VERSION ""

NS_ :

BS_:

BU_: CVC_I MHU TBOX FCAM_I MRR SRR_RL SRR_RR SRR_FL SRR_FR DUMMY_ECU ADCU_I AMP HUD

BO_ 1178 RMCU_WarnMsg: 8 CVC_I
 SG_ CRC_RMCU_WarnMsg : 7|8@0+ (1,0) [0|255] ""  MHU
 SG_ ALIVE_RMCU_WarnMsg : 11|4@0+ (1,0) [0|15] ""  MHU
 SG_ RMCU_Warning_Flag_1 : 12|1@0+ (1,0) [0|1] ""  MHU
 SG_ RMCU_Warning_Flag_2 : 13|1@0+ (1,0) [0|1] ""  MHU
 SG_ RMCU_Warning_Flag_3 : 14|1@0+ (1,0) [0|1] ""  MHU
 SG_ RMCU_Warning_Flag_4 : 15|1@0+ (1,0) [0|1] ""  MHU
 SG_ RMCU_Warning_Flag_5 : 16|1@0+ (1,0) [0|1] ""  MHU
 SG_ RMCU_Warning_Flag_6 : 17|1@0+ (1,0) [0|1] ""  MHU
 SG_ RMCU_Warning_Flag_7 : 18|1@0+ (1,0) [0|1] ""  MHU
 SG_ RMCU_Warning_Flag_8 : 19|1@0+ (1,0) [0|1] ""  MHU
 SG_ RMCU_Warning_Flag_9 : 20|1@0+ (1,0) [0|1] ""  MHU
 SG_ RMCU_Warning_Flag_10 : 21|1@0+ (1,0) [0|1] ""  MHU
 SG_ RMCU_Warning_Flag_11 : 22|1@0+ (1,0) [0|1] ""  MHU
 SG_ RMCU_Warning_Flag_12 : 23|1@0+ (1,0) [0|1] ""  MHU
 SG_ RMCU_Reserved_signal1 : 31|8@0+ (1,0) [0|255] ""  MHU
 SG_ RMCU_Reserved_signal2 : 39|8@0+ (1,0) [0|255] ""  MHU
 SG_ RMCU_Reserved_signal3 : 47|8@0+ (1,0) [0|255] ""  MHU
 SG_ RMCU_Reserved_signal4 : 55|8@0+ (1,0) [0|255] ""  MHU
 SG_ RMCU_Reserved_signal5 : 63|8@0+ (1,0) [0|255] ""  MHU

BO_ 1179 FMCU_WarnMsg: 8 CVC_I
 SG_ CRC_FMCU_WarnMsg : 7|8@0+ (1,0) [0|255] ""  MHU
 SG_ ALIVE_FMCU_WarnMsg : 11|4@0+ (1,0) [0|15] ""  MHU
 SG_ FMCU_Warning_Flag_1 : 12|1@0+ (1,0) [0|1] ""  MHU
 SG_ FMCU_Warning_Flag_2 : 13|1@0+ (1,0) [0|1] ""  MHU
 SG_ FMCU_Warning_Flag_3 : 14|1@0+ (1,0) [0|1] ""  MHU
 SG_ FMCU_Warning_Flag_4 : 15|1@0+ (1,0) [0|1] ""  MHU
 SG_ FMCU_Warning_Flag_5 : 16|1@0+ (1,0) [0|1] ""  MHU
 SG_ FMCU_Warning_Flag_6 : 17|1@0+ (1,0) [0|1] ""  MHU
 SG_ FMCU_Warning_Flag_7 : 18|1@0+ (1,0) [0|1] ""  MHU
 SG_ FMCU_Warning_Flag_8 : 19|1@0+ (1,0) [0|1] ""  MHU
 SG_ FMCU_Warning_Flag_9 : 20|1@0+ (1,0) [0|1] ""  MHU
 SG_ FMCU_Warning_Flag_10 : 21|1@0+ (1,0) [0|1] ""  MHU
 SG_ FMCU_Warning_Flag_11 : 22|1@0+ (1,0) [0|1] ""  MHU
 SG_ FMCU_Warning_Flag_12 : 23|1@0+ (1,0) [0|1] ""  MHU
 SG_ FMCU_Reserved_signal1 : 31|8@0+ (1,0) [0|255] ""  MHU
 SG_ FMCU_Reserved_signal2 : 39|8@0+ (1,0) [0|255] ""  MHU
 SG_ FMCU_Reserved_signal3 : 47|8@0+ (1,0) [0|255] ""  MHU
 SG_ FMCU_Reserved_signal4 : 55|8@0+ (1,0) [0|255] ""  MHU
 SG_ FMCU_Reserved_signal5 : 63|8@0+ (1,0) [0|255] ""  MHU

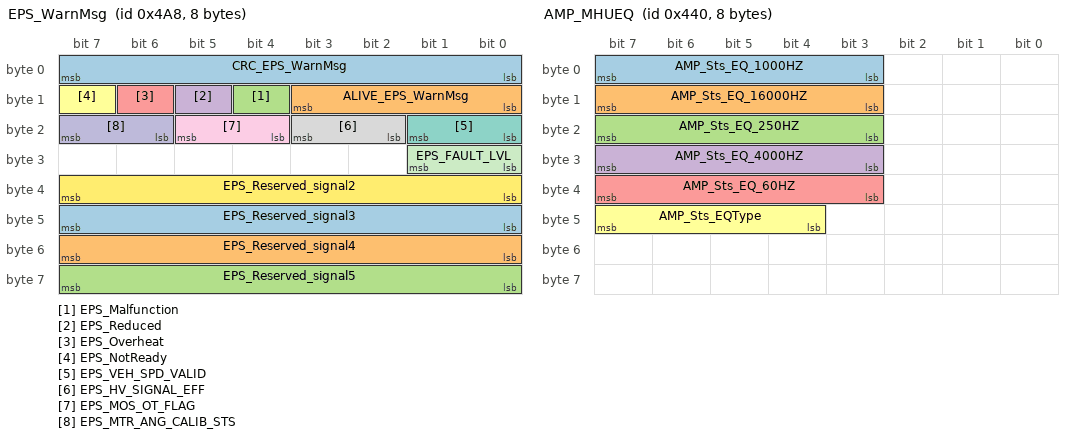
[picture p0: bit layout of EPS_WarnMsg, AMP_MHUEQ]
BO_ 1192 EPS_WarnMsg: 8 CVC_I
 SG_ CRC_EPS_WarnMsg : 7|8@0+ (1,0) [0|255] ""  MHU
 SG_ ALIVE_EPS_WarnMsg : 11|4@0+ (1,0) [0|15] ""  MHU
 SG_ EPS_Malfunction : 12|1@0+ (1,0) [0|1] ""  MHU
 SG_ EPS_Reduced : 13|1@0+ (1,0) [0|1] ""  MHU
 SG_ EPS_Overheat : 14|1@0+ (1,0) [0|1] ""  MHU
 SG_ EPS_NotReady : 15|1@0+ (1,0) [0|1] ""  MHU
 SG_ EPS_VEH_SPD_VALID : 17|2@0+ (1,0) [0|3] ""  MHU
 SG_ EPS_HV_SIGNAL_EFF : 19|2@0+ (1,0) [0|3] ""  MHU
 SG_ EPS_MOS_OT_FLAG : 21|2@0+ (1,0) [0|3] ""  MHU
 SG_ EPS_MTR_ANG_CALIB_STS : 23|2@0+ (1,0) [0|3] ""  MHU
 SG_ EPS_FAULT_LVL : 25|2@0+ (1,0) [0|3] ""  MHU
 SG_ EPS_Reserved_signal2 : 39|8@0+ (1,0) [0|255] ""  MHU
 SG_ EPS_Reserved_signal3 : 47|8@0+ (1,0) [0|255] ""  MHU
 SG_ EPS_Reserved_signal4 : 55|8@0+ (1,0) [0|255] ""  MHU
 SG_ EPS_Reserved_signal5 : 63|8@0+ (1,0) [0|255] ""  MHU

BO_ 1196 CVC_WarnMsg: 12 CVC_I
 SG_ CRC_CVC_WarnMsg : 7|8@0+ (1,0) [0|255] ""  MHU
 SG_ ALIVE_CVC_WarnMsg : 11|4@0+ (1,0) [0|15] ""  MHU
 SG_ CVC_GearPOnlyAtStationaryAlert : 12|1@0+ (1,0) [0|1] ""  MHU
 SG_ CVC_GearP_NotPossibleAlert : 13|1@0+ (1,0) [0|1] ""  MHU
 SG_ CVC_PressBrakeToEngageGear : 14|1@0+ (1,0) [0|1] ""  MHU
 SG_ CVC_CantChangeGear : 15|1@0+ (1,0) [0|1] ""  MHU
 SG_ CVC_GearMalfunction : 16|1@0+ (1,0) [0|1] ""  MHU
 SG_ CVC_RangeAlert : 17|1@0+ (1,0) [0|1] ""  MHU
 SG_ CVC_HVSystemReduced : 18|1@0+ (1,0) [0|1] ""  MHU
 SG_ CVC_FrontEDSReduced : 19|1@0+ (1,0) [0|1] ""  MHU
 SG_ CVC_FrontEDS_Malfunc : 20|1@0+ (1,0) [0|1] ""  MHU
 SG_ CVC_RearEDSReduced : 21|1@0+ (1,0) [0|1] ""  MHU
 SG_ CVC_RearEDS_Malfunc : 22|1@0+ (1,0) [0|1] ""  MHU
 SG_ CVC_CoolingSystem_Malfunc : 23|1@0+ (1,0) [0|1] ""  MHU
 SG_ CVC_NeutralRequest : 24|1@0+ (1,0) [0|1] ""  MHU
 SG_ CVC_SoftShutdown : 25|1@0+ (1,0) [0|1] ""  MHU
 SG_ CVC_EmergencyShutdown : 26|1@0+ (1,0) [0|1] ""  MHU
 SG_ CVC_ChgPortDoorSys_Malfunc : 27|1@0+ (1,0) [0|1] ""  MHU
 SG_ CVC_Gearchange_NotPossible : 28|1@0+ (1,0) [0|1] ""  MHU
 SG_ CVC_12v_Warning : 29|1@0+ (1,0) [0|1] ""  MHU,ADCU_I
 SG_ CVC_WflagRes19 : 30|1@0+ (1,0) [0|1] ""  MHU
 SG_ CVC_WflagRes20 : 31|1@0+ (1,0) [0|1] ""  MHU
 SG_ CVC_WflagRes21 : 32|1@0+ (1,0) [0|1] ""  MHU
 SG_ CVC_WflagRes22 : 33|1@0+ (1,0) [0|1] ""  MHU
 SG_ CVC_WflagRes23 : 34|1@0+ (1,0) [0|1] ""  MHU
 SG_ CVC_WflagRes24 : 35|1@0+ (1,0) [0|1] ""  MHU
 SG_ CVC_WflagRes25 : 36|1@0+ (1,0) [0|1] ""  MHU
 SG_ CVC_WflagRes26 : 37|1@0+ (1,0) [0|1] ""  MHU
 SG_ CVC_WflagRes27 : 38|1@0+ (1,0) [0|1] ""  MHU
 SG_ CVC_SuperFastCharge_longer : 39|1@0+ (1,0) [0|1] ""  MHU
 SG_ CVC_InvalidLimitSpeed : 46|1@0+ (1,0) [0|1] ""  MHU
 SG_ CVC_InvalidCruiseSpeed : 47|1@0+ (1,0) [0|1] ""  MHU
 SG_ CVC_Reserved_signal2 : 55|8@0+ (1,0) [0|255] ""  MHU
 SG_ CVC_Reserved_signal3 : 63|8@0+ (1,0) [0|255] ""  MHU
 SG_ CabinCoolDemand : 71|7@0+ (0.1,0) [0|10] "kW"  MHU
 SG_ CabinHeatDemand : 79|7@0+ (0.1,0) [0|10] "kW"  MHU
 SG_ CVC_TMSMode : 87|8@0+ (1,0) [0|255] ""  MHU

BO_ 1248 CVC_WarnMsgID_1: 64 CVC_I
 SG_ CRC_CVC_WarnMsgID_1 : 7|8@0+ (1,0) [0|255] ""  MHU
 SG_ ALIVE_CVC_WarnMsgID_1 : 11|4@0+ (1,0) [0|15] ""  MHU
 SG_ WarnMsgID_0 : 12|1@0+ (1,0) [0|1] ""  MHU
 SG_ WarnMsgID_1 : 13|1@0+ (1,0) [0|1] ""  MHU
 SG_ WarnMsgID_2 : 14|1@0+ (1,0) [0|1] ""  MHU
 SG_ WarnMsgID_3 : 15|1@0+ (1,0) [0|1] ""  MHU
 SG_ WarnMsgID_4 : 16|1@0+ (1,0) [0|1] ""  MHU
 SG_ WarnMsgID_5 : 17|1@0+ (1,0) [0|1] ""  MHU
 SG_ WarnMsgID_6 : 18|1@0+ (1,0) [0|1] ""  MHU
 SG_ WarnMsgID_7 : 19|1@0+ (1,0) [0|1] ""  MHU
 SG_ WarnMsgID_8 : 20|1@0+ (1,0) [0|1] ""  MHU
 SG_ WarnMsgID_9 : 21|1@0+ (1,0) [0|1] ""  MHU
 SG_ WarnMsgID_10 : 22|1@0+ (1,0) [0|1] ""  MHU
 SG_ WarnMsgID_11 : 23|1@0+ (1,0) [0|1] ""  MHU
 SG_ WarnMsgID_12 : 24|1@0+ (1,0) [0|1] ""  MHU
 SG_ WarnMsgID_13 : 25|1@0+ (1,0) [0|1] ""  MHU
 SG_ WarnMsgID_14 : 26|1@0+ (1,0) [0|1] ""  MHU
 SG_ WarnMsgID_15 : 27|1@0+ (1,0) [0|1] ""  MHU
 SG_ WarnMsgID_16 : 28|1@0+ (1,0) [0|1] ""  MHU
 SG_ WarnMsgID_17 : 29|1@0+ (1,0) [0|1] ""  MHU
 SG_ WarnMsgID_18 : 30|1@0+ (1,0) [0|1] ""  MHU
 SG_ WarnMsgID_19 : 31|1@0+ (1,0) [0|1] ""  MHU
 SG_ WarnMsgID_20 : 32|1@0+ (1,0) [0|1] ""  MHU
 SG_ WarnMsgID_21 : 33|1@0+ (1,0) [0|1] ""  MHU
 SG_ WarnMsgID_22 : 34|1@0+ (1,0) [0|1] ""  MHU
 SG_ WarnMsgID_23 : 35|1@0+ (1,0) [0|1] ""  MHU
 SG_ WarnMsgID_24 : 36|1@0+ (1,0) [0|1] ""  MHU
 SG_ WarnMsgID_25 : 37|1@0+ (1,0) [0|1] ""  MHU
 SG_ WarnMsgID_26 : 38|1@0+ (1,0) [0|1] ""  MHU
 SG_ WarnMsgID_27 : 39|1@0+ (1,0) [0|1] ""  MHU
 SG_ WarnMsgID_28 : 40|1@0+ (1,0) [0|1] ""  MHU
 SG_ WarnMsgID_29 : 41|1@0+ (1,0) [0|1] ""  MHU
 SG_ WarnMsgID_30 : 42|1@0+ (1,0) [0|1] ""  MHU
 SG_ WarnMsgID_31 : 43|1@0+ (1,0) [0|1] ""  MHU
 SG_ WarnMsgID_32 : 44|1@0+ (1,0) [0|1] ""  MHU
 SG_ WarnMsgID_33 : 45|1@0+ (1,0) [0|1] ""  MHU
 SG_ WarnMsgID_34 : 46|1@0+ (1,0) [0|1] ""  MHU
 SG_ WarnMsgID_35 : 47|1@0+ (1,0) [0|1] ""  MHU
 SG_ WarnMsgID_36 : 48|1@0+ (1,0) [0|1] ""  MHU
 SG_ WarnMsgID_37 : 49|1@0+ (1,0) [0|1] ""  MHU
 SG_ WarnMsgID_38 : 50|1@0+ (1,0) [0|1] ""  MHU
 SG_ WarnMsgID_39 : 51|1@0+ (1,0) [0|1] ""  MHU
 SG_ WarnMsgID_40 : 52|1@0+ (1,0) [0|1] ""  MHU
 SG_ WarnMsgID_41 : 53|1@0+ (1,0) [0|1] ""  MHU
 SG_ WarnMsgID_42 : 54|1@0+ (1,0) [0|1] ""  MHU
 SG_ WarnMsgID_43 : 55|1@0+ (1,0) [0|1] ""  MHU
 SG_ WarnMsgID_44 : 56|1@0+ (1,0) [0|1] ""  MHU
 SG_ WarnMsgID_45 : 57|1@0+ (1,0) [0|1] ""  MHU
 SG_ WarnMsgID_46 : 58|1@0+ (1,0) [0|1] ""  MHU
 SG_ WarnMsgID_47 : 59|1@0+ (1,0) [0|1] ""  MHU
 SG_ WarnMsgID_48 : 60|1@0+ (1,0) [0|1] ""  MHU
 SG_ WarnMsgID_49 : 61|1@0+ (1,0) [0|1] ""  MHU
 SG_ WarnMsgID_50 : 62|1@0+ (1,0) [0|1] ""  MHU
 SG_ WarnMsgID_51 : 63|1@0+ (1,0) [0|1] ""  MHU
 SG_ WarnMsgID_52 : 64|1@0+ (1,0) [0|1] ""  MHU
 SG_ WarnMsgID_53 : 65|1@0+ (1,0) [0|1] ""  MHU
 SG_ WarnMsgID_54 : 66|1@0+ (1,0) [0|1] ""  MHU
 SG_ WarnMsgID_55 : 67|1@0+ (1,0) [0|1] ""  MHU
 SG_ WarnMsgID_56 : 68|1@0+ (1,0) [0|1] ""  MHU
 SG_ WarnMsgID_57 : 69|1@0+ (1,0) [0|1] ""  MHU
 SG_ WarnMsgID_58 : 70|1@0+ (1,0) [0|1] ""  MHU
 SG_ WarnMsgID_59 : 71|1@0+ (1,0) [0|1] ""  MHU
 SG_ WarnMsgID_60 : 72|1@0+ (1,0) [0|1] ""  MHU
 SG_ WarnMsgID_61 : 73|1@0+ (1,0) [0|1] ""  MHU
 SG_ WarnMsgID_62 : 74|1@0+ (1,0) [0|1] ""  MHU
 SG_ WarnMsgID_63 : 75|1@0+ (1,0) [0|1] ""  MHU
 SG_ WarnMsgID_64 : 76|1@0+ (1,0) [0|1] ""  MHU
 SG_ WarnMsgID_65 : 77|1@0+ (1,0) [0|1] ""  MHU
 SG_ WarnMsgID_66 : 78|1@0+ (1,0) [0|1] ""  MHU
 SG_ WarnMsgID_67 : 79|1@0+ (1,0) [0|1] ""  MHU
 SG_ WarnMsgID_68 : 80|1@0+ (1,0) [0|1] ""  MHU
 SG_ WarnMsgID_69 : 81|1@0+ (1,0) [0|1] ""  MHU
 SG_ WarnMsgID_70 : 82|1@0+ (1,0) [0|1] ""  MHU
 SG_ WarnMsgID_71 : 83|1@0+ (1,0) [0|1] ""  MHU
 SG_ WarnMsgID_72 : 84|1@0+ (1,0) [0|1] ""  MHU
 SG_ WarnMsgID_73 : 85|1@0+ (1,0) [0|1] ""  MHU
 SG_ WarnMsgID_74 : 86|1@0+ (1,0) [0|1] ""  MHU
 SG_ WarnMsgID_75 : 87|1@0+ (1,0) [0|1] ""  MHU
 SG_ WarnMsgID_76 : 88|1@0+ (1,0) [0|1] ""  MHU
 SG_ WarnMsgID_77 : 89|1@0+ (1,0) [0|1] ""  MHU
 SG_ WarnMsgID_78 : 90|1@0+ (1,0) [0|1] ""  MHU
 SG_ WarnMsgID_79 : 91|1@0+ (1,0) [0|1] ""  MHU
 SG_ WarnMsgID_80 : 92|1@0+ (1,0) [0|1] ""  MHU
 SG_ WarnMsgID_81 : 93|1@0+ (1,0) [0|1] ""  MHU
 SG_ WarnMsgID_82 : 94|1@0+ (1,0) [0|1] ""  MHU
 SG_ WarnMsgID_83 : 95|1@0+ (1,0) [0|1] ""  MHU
 SG_ WarnMsgID_84 : 96|1@0+ (1,0) [0|1] ""  MHU
 SG_ WarnMsgID_85 : 97|1@0+ (1,0) [0|1] ""  MHU
 SG_ WarnMsgID_86 : 98|1@0+ (1,0) [0|1] ""  MHU
 SG_ WarnMsgID_87 : 99|1@0+ (1,0) [0|1] ""  MHU
 SG_ WarnMsgID_88 : 100|1@0+ (1,0) [0|1] ""  MHU
 SG_ WarnMsgID_89 : 101|1@0+ (1,0) [0|1] ""  MHU
 SG_ WarnMsgID_90 : 102|1@0+ (1,0) [0|1] ""  MHU
 SG_ WarnMsgID_91 : 103|1@0+ (1,0) [0|1] ""  MHU
 SG_ WarnMsgID_92 : 104|1@0+ (1,0) [0|1] ""  MHU
 SG_ WarnMsgID_93 : 105|1@0+ (1,0) [0|1] ""  MHU
 SG_ WarnMsgID_94 : 106|1@0+ (1,0) [0|1] ""  MHU
 SG_ WarnMsgID_95 : 107|1@0+ (1,0) [0|1] ""  MHU
 SG_ WarnMsgID_96 : 108|1@0+ (1,0) [0|1] ""  MHU
 SG_ WarnMsgID_97 : 109|1@0+ (1,0) [0|1] ""  MHU
 SG_ WarnMsgID_98 : 110|1@0+ (1,0) [0|1] ""  MHU
 SG_ WarnMsgID_99 : 111|1@0+ (1,0) [0|1] ""  MHU
 SG_ WarnMsgID_100 : 112|1@0+ (1,0) [0|1] ""  MHU
 SG_ WarnMsgID_101 : 113|1@0+ (1,0) [0|1] ""  MHU
 SG_ WarnMsgID_102 : 114|1@0+ (1,0) [0|1] ""  MHU
 SG_ WarnMsgID_103 : 115|1@0+ (1,0) [0|1] ""  MHU
 SG_ WarnMsgID_104 : 116|1@0+ (1,0) [0|1] ""  MHU
 SG_ WarnMsgID_105 : 117|1@0+ (1,0) [0|1] ""  MHU
 SG_ WarnMsgID_106 : 118|1@0+ (1,0) [0|1] ""  MHU
 SG_ WarnMsgID_107 : 119|1@0+ (1,0) [0|1] ""  MHU
 SG_ WarnMsgID_108 : 120|1@0+ (1,0) [0|1] ""  MHU
 SG_ WarnMsgID_109 : 121|1@0+ (1,0) [0|1] ""  MHU
 SG_ WarnMsgID_110 : 122|1@0+ (1,0) [0|1] ""  MHU
 SG_ WarnMsgID_111 : 123|1@0+ (1,0) [0|1] ""  MHU
 SG_ WarnMsgID_112 : 124|1@0+ (1,0) [0|1] ""  MHU
 SG_ WarnMsgID_113 : 125|1@0+ (1,0) [0|1] ""  MHU
 SG_ WarnMsgID_114 : 126|1@0+ (1,0) [0|1] ""  MHU
 SG_ WarnMsgID_115 : 127|1@0+ (1,0) [0|1] ""  MHU
 SG_ WarnMsgID_116 : 128|1@0+ (1,0) [0|1] ""  MHU
 SG_ WarnMsgID_117 : 129|1@0+ (1,0) [0|1] ""  MHU
 SG_ WarnMsgID_118 : 130|1@0+ (1,0) [0|1] ""  MHU
 SG_ WarnMsgID_119 : 131|1@0+ (1,0) [0|1] ""  MHU
 SG_ WarnMsgID_120 : 132|1@0+ (1,0) [0|1] ""  MHU
 SG_ WarnMsgID_121 : 133|1@0+ (1,0) [0|1] ""  MHU
 SG_ WarnMsgID_122 : 134|1@0+ (1,0) [0|1] ""  MHU
 SG_ WarnMsgID_123 : 135|1@0+ (1,0) [0|1] ""  MHU
 SG_ WarnMsgID_124 : 136|1@0+ (1,0) [0|1] ""  MHU
 SG_ WarnMsgID_125 : 137|1@0+ (1,0) [0|1] ""  MHU
 SG_ WarnMsgID_126 : 138|1@0+ (1,0) [0|1] ""  MHU
 SG_ WarnMsgID_127 : 139|1@0+ (1,0) [0|1] ""  MHU
 SG_ WarnMsgID_128 : 140|1@0+ (1,0) [0|1] ""  MHU
 SG_ WarnMsgID_129 : 141|1@0+ (1,0) [0|1] ""  MHU
 SG_ WarnMsgID_130 : 142|1@0+ (1,0) [0|1] ""  MHU
 SG_ WarnMsgID_131 : 143|1@0+ (1,0) [0|1] ""  MHU
 SG_ WarnMsgID_132 : 144|1@0+ (1,0) [0|1] ""  MHU
 SG_ WarnMsgID_133 : 145|1@0+ (1,0) [0|1] ""  MHU
 SG_ WarnMsgID_134 : 146|1@0+ (1,0) [0|1] ""  MHU
 SG_ WarnMsgID_135 : 147|1@0+ (1,0) [0|1] ""  MHU
 SG_ WarnMsgID_136 : 148|1@0+ (1,0) [0|1] ""  MHU
 SG_ WarnMsgID_137 : 149|1@0+ (1,0) [0|1] ""  MHU
 SG_ WarnMsgID_138 : 150|1@0+ (1,0) [0|1] ""  MHU
 SG_ WarnMsgID_139 : 151|1@0+ (1,0) [0|1] ""  MHU
 SG_ WarnMsgID_140 : 152|1@0+ (1,0) [0|1] ""  MHU
 SG_ WarnMsgID_141 : 153|1@0+ (1,0) [0|1] ""  MHU
 SG_ WarnMsgID_142 : 154|1@0+ (1,0) [0|1] ""  MHU
 SG_ WarnMsgID_143 : 155|1@0+ (1,0) [0|1] ""  MHU
 SG_ WarnMsgID_144 : 156|1@0+ (1,0) [0|1] ""  MHU
 SG_ WarnMsgID_145 : 157|1@0+ (1,0) [0|1] ""  MHU
 SG_ WarnMsgID_146 : 158|1@0+ (1,0) [0|1] ""  MHU
 SG_ WarnMsgID_147 : 159|1@0+ (1,0) [0|1] ""  MHU
 SG_ WarnMsgID_148 : 160|1@0+ (1,0) [0|1] ""  MHU
 SG_ WarnMsgID_149 : 161|1@0+ (1,0) [0|1] ""  MHU
 SG_ WarnMsgID_150 : 162|1@0+ (1,0) [0|1] ""  MHU
 SG_ WarnMsgID_151 : 163|1@0+ (1,0) [0|1] ""  MHU
 SG_ WarnMsgID_152 : 164|1@0+ (1,0) [0|1] ""  MHU
 SG_ WarnMsgID_153 : 165|1@0+ (1,0) [0|1] ""  MHU
 SG_ WarnMsgID_154 : 166|1@0+ (1,0) [0|1] ""  MHU
 SG_ WarnMsgID_155 : 167|1@0+ (1,0) [0|1] ""  MHU
 SG_ WarnMsgID_156 : 168|1@0+ (1,0) [0|1] ""  MHU
 SG_ WarnMsgID_157 : 169|1@0+ (1,0) [0|1] ""  MHU
 SG_ WarnMsgID_158 : 170|1@0+ (1,0) [0|1] ""  MHU
 SG_ WarnMsgID_159 : 171|1@0+ (1,0) [0|1] ""  MHU
 SG_ WarnMsgID_160 : 172|1@0+ (1,0) [0|1] ""  MHU
 SG_ WarnMsgID_161 : 173|1@0+ (1,0) [0|1] ""  MHU
 SG_ WarnMsgID_162 : 174|1@0+ (1,0) [0|1] ""  MHU
 SG_ WarnMsgID_163 : 175|1@0+ (1,0) [0|1] ""  MHU
 SG_ WarnMsgID_164 : 176|1@0+ (1,0) [0|1] ""  MHU
 SG_ WarnMsgID_165 : 177|1@0+ (1,0) [0|1] ""  MHU
 SG_ WarnMsgID_166 : 178|1@0+ (1,0) [0|1] ""  MHU
 SG_ WarnMsgID_167 : 179|1@0+ (1,0) [0|1] ""  MHU
 SG_ WarnMsgID_168 : 180|1@0+ (1,0) [0|1] ""  MHU
 SG_ WarnMsgID_169 : 181|1@0+ (1,0) [0|1] ""  MHU
 SG_ WarnMsgID_170 : 182|1@0+ (1,0) [0|1] ""  MHU
 SG_ WarnMsgID_171 : 183|1@0+ (1,0) [0|1] ""  MHU
 SG_ WarnMsgID_172 : 184|1@0+ (1,0) [0|1] ""  MHU
 SG_ WarnMsgID_173 : 185|1@0+ (1,0) [0|1] ""  MHU
 SG_ WarnMsgID_174 : 186|1@0+ (1,0) [0|1] ""  MHU
 SG_ WarnMsgID_175 : 187|1@0+ (1,0) [0|1] ""  MHU
 SG_ WarnMsgID_176 : 188|1@0+ (1,0) [0|1] ""  MHU
 SG_ WarnMsgID_177 : 189|1@0+ (1,0) [0|1] ""  MHU
 SG_ WarnMsgID_178 : 190|1@0+ (1,0) [0|1] ""  MHU
 SG_ WarnMsgID_179 : 191|1@0+ (1,0) [0|1] ""  MHU
 SG_ WarnMsgID_180 : 192|1@0+ (1,0) [0|1] ""  MHU
 SG_ WarnMsgID_181 : 193|1@0+ (1,0) [0|1] ""  MHU
 SG_ WarnMsgID_182 : 194|1@0+ (1,0) [0|1] ""  MHU
 SG_ WarnMsgID_183 : 195|1@0+ (1,0) [0|1] ""  MHU
 SG_ WarnMsgID_184 : 196|1@0+ (1,0) [0|1] ""  MHU
 SG_ WarnMsgID_185 : 197|1@0+ (1,0) [0|1] ""  MHU
 SG_ WarnMsgID_186 : 198|1@0+ (1,0) [0|1] ""  MHU
 SG_ WarnMsgID_187 : 199|1@0+ (1,0) [0|1] ""  MHU
 SG_ WarnMsgID_188 : 200|1@0+ (1,0) [0|1] ""  MHU
 SG_ WarnMsgID_189 : 201|1@0+ (1,0) [0|1] ""  MHU
 SG_ WarnMsgID_190 : 202|1@0+ (1,0) [0|1] ""  MHU
 SG_ WarnMsgID_191 : 203|1@0+ (1,0) [0|1] ""  MHU
 SG_ WarnMsgID_192 : 204|1@0+ (1,0) [0|1] ""  MHU
 SG_ WarnMsgID_193 : 205|1@0+ (1,0) [0|1] ""  MHU
 SG_ WarnMsgID_194 : 206|1@0+ (1,0) [0|1] ""  MHU
 SG_ WarnMsgID_195 : 207|1@0+ (1,0) [0|1] ""  MHU
 SG_ WarnMsgID_196 : 208|1@0+ (1,0) [0|1] ""  MHU
 SG_ WarnMsgID_197 : 209|1@0+ (1,0) [0|1] ""  MHU
 SG_ WarnMsgID_198 : 210|1@0+ (1,0) [0|1] ""  MHU
 SG_ WarnMsgID_199 : 211|1@0+ (1,0) [0|1] ""  MHU
 SG_ WarnMsgID_200 : 212|1@0+ (1,0) [0|1] ""  MHU
 SG_ WarnMsgID_201 : 213|1@0+ (1,0) [0|1] ""  MHU
 SG_ WarnMsgID_202 : 214|1@0+ (1,0) [0|1] ""  MHU
 SG_ WarnMsgID_203 : 215|1@0+ (1,0) [0|1] ""  MHU
 SG_ WarnMsgID_204 : 216|1@0+ (1,0) [0|1] ""  MHU
 SG_ WarnMsgID_205 : 217|1@0+ (1,0) [0|1] ""  MHU
 SG_ WarnMsgID_206 : 218|1@0+ (1,0) [0|1] ""  MHU
 SG_ WarnMsgID_207 : 219|1@0+ (1,0) [0|1] ""  MHU
 SG_ WarnMsgID_208 : 220|1@0+ (1,0) [0|1] ""  MHU
 SG_ WarnMsgID_209 : 221|1@0+ (1,0) [0|1] ""  MHU
 SG_ WarnMsgID_210 : 222|1@0+ (1,0) [0|1] ""  MHU
 SG_ WarnMsgID_211 : 223|1@0+ (1,0) [0|1] ""  MHU
 SG_ WarnMsgID_212 : 224|1@0+ (1,0) [0|1] ""  MHU
 SG_ WarnMsgID_213 : 225|1@0+ (1,0) [0|1] ""  MHU
 SG_ WarnMsgID_214 : 226|1@0+ (1,0) [0|1] ""  MHU
 SG_ WarnMsgID_215 : 227|1@0+ (1,0) [0|1] ""  MHU
 SG_ WarnMsgID_216 : 228|1@0+ (1,0) [0|1] ""  MHU
 SG_ WarnMsgID_217 : 229|1@0+ (1,0) [0|1] ""  MHU
 SG_ WarnMsgID_218 : 230|1@0+ (1,0) [0|1] ""  MHU
 SG_ WarnMsgID_219 : 231|1@0+ (1,0) [0|1] ""  MHU
 SG_ WarnMsgID_220 : 232|1@0+ (1,0) [0|1] ""  MHU
 SG_ WarnMsgID_221 : 233|1@0+ (1,0) [0|1] ""  MHU
 SG_ WarnMsgID_222 : 234|1@0+ (1,0) [0|1] ""  MHU
 SG_ WarnMsgID_223 : 235|1@0+ (1,0) [0|1] ""  MHU
 SG_ WarnMsgID_224 : 236|1@0+ (1,0) [0|1] ""  MHU
 SG_ WarnMsgID_225 : 237|1@0+ (1,0) [0|1] ""  MHU
 SG_ WarnMsgID_226 : 238|1@0+ (1,0) [0|1] ""  MHU
 SG_ WarnMsgID_227 : 239|1@0+ (1,0) [0|1] ""  MHU
 SG_ WarnMsgID_228 : 240|1@0+ (1,0) [0|1] ""  MHU
 SG_ WarnMsgID_229 : 241|1@0+ (1,0) [0|1] ""  MHU
 SG_ WarnMsgID_230 : 242|1@0+ (1,0) [0|1] ""  MHU
 SG_ WarnMsgID_231 : 243|1@0+ (1,0) [0|1] ""  MHU
 SG_ WarnMsgID_232 : 244|1@0+ (1,0) [0|1] ""  MHU
 SG_ WarnMsgID_233 : 245|1@0+ (1,0) [0|1] ""  MHU
 SG_ WarnMsgID_234 : 246|1@0+ (1,0) [0|1] ""  MHU
 SG_ WarnMsgID_235 : 247|1@0+ (1,0) [0|1] ""  MHU
 SG_ WarnMsgID_236 : 248|1@0+ (1,0) [0|1] ""  MHU
 SG_ WarnMsgID_237 : 249|1@0+ (1,0) [0|1] ""  MHU
 SG_ WarnMsgID_238 : 250|1@0+ (1,0) [0|1] ""  MHU
 SG_ WarnMsgID_239 : 251|1@0+ (1,0) [0|1] ""  MHU
 SG_ WarnMsgID_240 : 252|1@0+ (1,0) [0|1] ""  MHU
 SG_ WarnMsgID_241 : 253|1@0+ (1,0) [0|1] ""  MHU
 SG_ WarnMsgID_242 : 254|1@0+ (1,0) [0|1] ""  MHU
 SG_ WarnMsgID_243 : 255|1@0+ (1,0) [0|1] ""  MHU
 SG_ WarnMsgID_244 : 256|1@0+ (1,0) [0|1] ""  MHU
 SG_ WarnMsgID_245 : 257|1@0+ (1,0) [0|1] ""  MHU
 SG_ WarnMsgID_246 : 258|1@0+ (1,0) [0|1] ""  MHU
 SG_ WarnMsgID_247 : 259|1@0+ (1,0) [0|1] ""  MHU
 SG_ WarnMsgID_248 : 260|1@0+ (1,0) [0|1] ""  MHU
 SG_ WarnMsgID_249 : 261|1@0+ (1,0) [0|1] ""  MHU
 SG_ WarnMsgID_250 : 262|1@0+ (1,0) [0|1] ""  MHU
 SG_ WarnMsgID_251 : 263|1@0+ (1,0) [0|1] ""  MHU
 SG_ WarnMsgID_252 : 264|1@0+ (1,0) [0|1] ""  MHU
 SG_ WarnMsgID_253 : 265|1@0+ (1,0) [0|1] ""  MHU
 SG_ WarnMsgID_254 : 266|1@0+ (1,0) [0|1] ""  MHU
 SG_ WarnMsgID_255 : 267|1@0+ (1,0) [0|1] ""  MHU
 SG_ WarnMsgID_256 : 268|1@0+ (1,0) [0|1] ""  MHU
 SG_ WarnMsgID_257 : 269|1@0+ (1,0) [0|1] ""  MHU
 SG_ WarnMsgID_258 : 270|1@0+ (1,0) [0|1] ""  MHU
 SG_ WarnMsgID_259 : 271|1@0+ (1,0) [0|1] ""  MHU
 SG_ WarnMsgID_260 : 272|1@0+ (1,0) [0|1] ""  MHU
 SG_ WarnMsgID_261 : 273|1@0+ (1,0) [0|1] ""  MHU
 SG_ WarnMsgID_262 : 274|1@0+ (1,0) [0|1] ""  MHU
 SG_ WarnMsgID_263 : 275|1@0+ (1,0) [0|1] ""  MHU
 SG_ WarnMsgID_264 : 276|1@0+ (1,0) [0|1] ""  MHU
 SG_ WarnMsgID_265 : 277|1@0+ (1,0) [0|1] ""  MHU
 SG_ WarnMsgID_266 : 278|1@0+ (1,0) [0|1] ""  MHU
 SG_ WarnMsgID_267 : 279|1@0+ (1,0) [0|1] ""  MHU
 SG_ WarnMsgID_268 : 280|1@0+ (1,0) [0|1] ""  MHU
 SG_ WarnMsgID_269 : 281|1@0+ (1,0) [0|1] ""  MHU
 SG_ WarnMsgID_270 : 282|1@0+ (1,0) [0|1] ""  MHU
 SG_ WarnMsgID_271 : 283|1@0+ (1,0) [0|1] ""  MHU
 SG_ WarnMsgID_272 : 284|1@0+ (1,0) [0|1] ""  MHU
 SG_ WarnMsgID_273 : 285|1@0+ (1,0) [0|1] ""  MHU
 SG_ WarnMsgID_274 : 286|1@0+ (1,0) [0|1] ""  MHU
 SG_ WarnMsgID_275 : 287|1@0+ (1,0) [0|1] ""  MHU
 SG_ WarnMsgID_276 : 288|1@0+ (1,0) [0|1] ""  MHU
 SG_ WarnMsgID_277 : 289|1@0+ (1,0) [0|1] ""  MHU
 SG_ WarnMsgID_278 : 290|1@0+ (1,0) [0|1] ""  MHU
 SG_ WarnMsgID_279 : 291|1@0+ (1,0) [0|1] ""  MHU
 SG_ WarnMsgID_280 : 292|1@0+ (1,0) [0|1] ""  MHU
 SG_ WarnMsgID_281 : 293|1@0+ (1,0) [0|1] ""  MHU
 SG_ WarnMsgID_282 : 294|1@0+ (1,0) [0|1] ""  MHU
 SG_ WarnMsgID_283 : 295|1@0+ (1,0) [0|1] ""  MHU
 SG_ WarnMsgID_284 : 296|1@0+ (1,0) [0|1] ""  MHU
 SG_ WarnMsgID_285 : 297|1@0+ (1,0) [0|1] ""  MHU
 SG_ WarnMsgID_286 : 298|1@0+ (1,0) [0|1] ""  MHU
 SG_ WarnMsgID_287 : 299|1@0+ (1,0) [0|1] ""  MHU
 SG_ WarnMsgID_288 : 300|1@0+ (1,0) [0|1] ""  MHU
 SG_ WarnMsgID_289 : 301|1@0+ (1,0) [0|1] ""  MHU
 SG_ WarnMsgID_290 : 302|1@0+ (1,0) [0|1] ""  MHU
 SG_ WarnMsgID_291 : 303|1@0+ (1,0) [0|1] ""  MHU
 SG_ WarnMsgID_292 : 304|1@0+ (1,0) [0|1] ""  MHU
 SG_ WarnMsgID_293 : 305|1@0+ (1,0) [0|1] ""  MHU
 SG_ WarnMsgID_294 : 306|1@0+ (1,0) [0|1] ""  MHU
 SG_ WarnMsgID_295 : 307|1@0+ (1,0) [0|1] ""  MHU
 SG_ WarnMsgID_296 : 308|1@0+ (1,0) [0|1] ""  MHU
 SG_ WarnMsgID_297 : 309|1@0+ (1,0) [0|1] ""  MHU
 SG_ WarnMsgID_298 : 310|1@0+ (1,0) [0|1] ""  MHU
 SG_ WarnMsgID_299 : 311|1@0+ (1,0) [0|1] ""  MHU
 SG_ WarnMsgID_300 : 312|1@0+ (1,0) [0|1] ""  MHU
 SG_ WarnMsgID_301 : 313|1@0+ (1,0) [0|1] ""  MHU
 SG_ WarnMsgID_302 : 314|1@0+ (1,0) [0|1] ""  MHU
 SG_ WarnMsgID_303 : 315|1@0+ (1,0) [0|1] ""  MHU
 SG_ WarnMsgID_304 : 316|1@0+ (1,0) [0|1] ""  MHU
 SG_ WarnMsgID_305 : 317|1@0+ (1,0) [0|1] ""  MHU
 SG_ WarnMsgID_306 : 318|1@0+ (1,0) [0|1] ""  MHU
 SG_ WarnMsgID_307 : 319|1@0+ (1,0) [0|1] ""  MHU
 SG_ WarnMsgID_308 : 320|1@0+ (1,0) [0|1] ""  MHU
 SG_ WarnMsgID_309 : 321|1@0+ (1,0) [0|1] ""  MHU
 SG_ WarnMsgID_310 : 322|1@0+ (1,0) [0|1] ""  MHU
 SG_ WarnMsgID_311 : 323|1@0+ (1,0) [0|1] ""  MHU
 SG_ WarnMsgID_312 : 324|1@0+ (1,0) [0|1] ""  MHU
 SG_ WarnMsgID_313 : 325|1@0+ (1,0) [0|1] ""  MHU
 SG_ WarnMsgID_314 : 326|1@0+ (1,0) [0|1] ""  MHU
 SG_ WarnMsgID_315 : 327|1@0+ (1,0) [0|1] ""  MHU
 SG_ WarnMsgID_316 : 328|1@0+ (1,0) [0|1] ""  MHU
 SG_ WarnMsgID_317 : 329|1@0+ (1,0) [0|1] ""  MHU
 SG_ WarnMsgID_318 : 330|1@0+ (1,0) [0|1] ""  MHU
 SG_ WarnMsgID_319 : 331|1@0+ (1,0) [0|1] ""  MHU
 SG_ WarnMsgID_320 : 332|1@0+ (1,0) [0|1] ""  MHU
 SG_ WarnMsgID_321 : 333|1@0+ (1,0) [0|1] ""  MHU
 SG_ WarnMsgID_322 : 334|1@0+ (1,0) [0|1] ""  MHU
 SG_ WarnMsgID_323 : 335|1@0+ (1,0) [0|1] ""  MHU
 SG_ WarnMsgID_324 : 336|1@0+ (1,0) [0|1] ""  MHU
 SG_ WarnMsgID_325 : 337|1@0+ (1,0) [0|1] ""  MHU
 SG_ WarnMsgID_326 : 338|1@0+ (1,0) [0|1] ""  MHU
 SG_ WarnMsgID_327 : 339|1@0+ (1,0) [0|1] ""  MHU
 SG_ WarnMsgID_328 : 340|1@0+ (1,0) [0|1] ""  MHU
 SG_ WarnMsgID_329 : 341|1@0+ (1,0) [0|1] ""  MHU
 SG_ WarnMsgID_330 : 342|1@0+ (1,0) [0|1] ""  MHU
 SG_ WarnMsgID_331 : 343|1@0+ (1,0) [0|1] ""  MHU
 SG_ WarnMsgID_332 : 344|1@0+ (1,0) [0|1] ""  MHU
 SG_ WarnMsgID_333 : 345|1@0+ (1,0) [0|1] ""  MHU
 SG_ WarnMsgID_334 : 346|1@0+ (1,0) [0|1] ""  MHU
 SG_ WarnMsgID_335 : 347|1@0+ (1,0) [0|1] ""  MHU
 SG_ WarnMsgID_336 : 348|1@0+ (1,0) [0|1] ""  MHU
 SG_ WarnMsgID_337 : 349|1@0+ (1,0) [0|1] ""  MHU
 SG_ WarnMsgID_338 : 350|1@0+ (1,0) [0|1] ""  MHU
 SG_ WarnMsgID_339 : 351|1@0+ (1,0) [0|1] ""  MHU
 SG_ WarnMsgID_340 : 352|1@0+ (1,0) [0|1] ""  MHU
 SG_ WarnMsgID_341 : 353|1@0+ (1,0) [0|1] ""  MHU
 SG_ WarnMsgID_342 : 354|1@0+ (1,0) [0|1] ""  MHU
 SG_ WarnMsgID_343 : 355|1@0+ (1,0) [0|1] ""  MHU
 SG_ WarnMsgID_344 : 356|1@0+ (1,0) [0|1] ""  MHU
 SG_ WarnMsgID_345 : 357|1@0+ (1,0) [0|1] ""  MHU
 SG_ WarnMsgID_346 : 358|1@0+ (1,0) [0|1] ""  MHU
 SG_ WarnMsgID_347 : 359|1@0+ (1,0) [0|1] ""  MHU
 SG_ WarnMsgID_348 : 360|1@0+ (1,0) [0|1] ""  MHU
 SG_ WarnMsgID_349 : 361|1@0+ (1,0) [0|1] ""  MHU
 SG_ WarnMsgID_350 : 362|1@0+ (1,0) [0|1] ""  MHU
 SG_ WarnMsgID_351 : 363|1@0+ (1,0) [0|1] ""  MHU
 SG_ WarnMsgID_352 : 364|1@0+ (1,0) [0|1] ""  MHU
 SG_ WarnMsgID_353 : 365|1@0+ (1,0) [0|1] ""  MHU
 SG_ WarnMsgID_354 : 366|1@0+ (1,0) [0|1] ""  MHU
 SG_ WarnMsgID_355 : 367|1@0+ (1,0) [0|1] ""  MHU
 SG_ WarnMsgID_356 : 368|1@0+ (1,0) [0|1] ""  MHU
 SG_ WarnMsgID_357 : 369|1@0+ (1,0) [0|1] ""  MHU
 SG_ WarnMsgID_358 : 370|1@0+ (1,0) [0|1] ""  MHU
 SG_ WarnMsgID_359 : 371|1@0+ (1,0) [0|1] ""  MHU
 SG_ WarnMsgID_360 : 372|1@0+ (1,0) [0|1] ""  MHU
 SG_ WarnMsgID_361 : 373|1@0+ (1,0) [0|1] ""  MHU
 SG_ WarnMsgID_362 : 374|1@0+ (1,0) [0|1] ""  MHU
 SG_ WarnMsgID_363 : 375|1@0+ (1,0) [0|1] ""  MHU
 SG_ WarnMsgID_364 : 376|1@0+ (1,0) [0|1] ""  MHU
 SG_ WarnMsgID_365 : 377|1@0+ (1,0) [0|1] ""  MHU
 SG_ WarnMsgID_366 : 378|1@0+ (1,0) [0|1] ""  MHU
 SG_ WarnMsgID_367 : 379|1@0+ (1,0) [0|1] ""  MHU
 SG_ WarnMsgID_368 : 380|1@0+ (1,0) [0|1] ""  MHU
 SG_ WarnMsgID_369 : 381|1@0+ (1,0) [0|1] ""  MHU
 SG_ WarnMsgID_370 : 382|1@0+ (1,0) [0|1] ""  MHU
 SG_ WarnMsgID_371 : 383|1@0+ (1,0) [0|1] ""  MHU
 SG_ WarnMsgID_372 : 384|1@0+ (1,0) [0|1] ""  MHU
 SG_ WarnMsgID_373 : 385|1@0+ (1,0) [0|1] ""  MHU
 SG_ WarnMsgID_374 : 386|1@0+ (1,0) [0|1] ""  MHU
 SG_ WarnMsgID_375 : 387|1@0+ (1,0) [0|1] ""  MHU
 SG_ WarnMsgID_376 : 388|1@0+ (1,0) [0|1] ""  MHU
 SG_ WarnMsgID_377 : 389|1@0+ (1,0) [0|1] ""  MHU
 SG_ WarnMsgID_378 : 390|1@0+ (1,0) [0|1] ""  MHU
 SG_ WarnMsgID_379 : 391|1@0+ (1,0) [0|1] ""  MHU
 SG_ WarnMsgID_380 : 392|1@0+ (1,0) [0|1] ""  MHU
 SG_ WarnMsgID_381 : 393|1@0+ (1,0) [0|1] ""  MHU
 SG_ WarnMsgID_382 : 394|1@0+ (1,0) [0|1] ""  MHU
 SG_ WarnMsgID_383 : 395|1@0+ (1,0) [0|1] ""  MHU
 SG_ WarnMsgID_384 : 396|1@0+ (1,0) [0|1] ""  MHU
 SG_ WarnMsgID_385 : 397|1@0+ (1,0) [0|1] ""  MHU
 SG_ WarnMsgID_386 : 398|1@0+ (1,0) [0|1] ""  MHU
 SG_ WarnMsgID_387 : 399|1@0+ (1,0) [0|1] ""  MHU
 SG_ WarnMsgID_388 : 400|1@0+ (1,0) [0|1] ""  MHU
 SG_ WarnMsgID_389 : 401|1@0+ (1,0) [0|1] ""  MHU
 SG_ WarnMsgID_390 : 402|1@0+ (1,0) [0|1] ""  MHU
 SG_ WarnMsgID_391 : 403|1@0+ (1,0) [0|1] ""  MHU
 SG_ WarnMsgID_392 : 404|1@0+ (1,0) [0|1] ""  MHU
 SG_ WarnMsgID_393 : 405|1@0+ (1,0) [0|1] ""  MHU
 SG_ WarnMsgID_394 : 406|1@0+ (1,0) [0|1] ""  MHU
 SG_ WarnMsgID_395 : 407|1@0+ (1,0) [0|1] ""  MHU
 SG_ WarnMsgID_396 : 408|1@0+ (1,0) [0|1] ""  MHU
 SG_ WarnMsgID_397 : 409|1@0+ (1,0) [0|1] ""  MHU
 SG_ WarnMsgID_398 : 410|1@0+ (1,0) [0|1] ""  MHU
 SG_ WarnMsgID_399 : 411|1@0+ (1,0) [0|1] ""  MHU
 SG_ WarnMsgID_400 : 412|1@0+ (1,0) [0|1] ""  MHU
 SG_ WarnMsgID_401 : 413|1@0+ (1,0) [0|1] ""  MHU
 SG_ WarnMsgID_402 : 414|1@0+ (1,0) [0|1] ""  MHU
 SG_ WarnMsgID_403 : 415|1@0+ (1,0) [0|1] ""  MHU
 SG_ WarnMsgID_404 : 416|1@0+ (1,0) [0|1] ""  MHU
 SG_ WarnMsgID_405 : 417|1@0+ (1,0) [0|1] ""  MHU
 SG_ WarnMsgID_406 : 418|1@0+ (1,0) [0|1] ""  MHU
 SG_ WarnMsgID_407 : 419|1@0+ (1,0) [0|1] ""  MHU
 SG_ WarnMsgID_408 : 420|1@0+ (1,0) [0|1] ""  MHU
 SG_ WarnMsgID_409 : 421|1@0+ (1,0) [0|1] ""  MHU
 SG_ WarnMsgID_410 : 422|1@0+ (1,0) [0|1] ""  MHU
 SG_ WarnMsgID_411 : 423|1@0+ (1,0) [0|1] ""  MHU
 SG_ WarnMsgID_412 : 424|1@0+ (1,0) [0|1] ""  MHU
 SG_ WarnMsgID_413 : 425|1@0+ (1,0) [0|1] ""  MHU
 SG_ WarnMsgID_414 : 426|1@0+ (1,0) [0|1] ""  MHU
 SG_ WarnMsgID_415 : 427|1@0+ (1,0) [0|1] ""  MHU
 SG_ WarnMsgID_416 : 428|1@0+ (1,0) [0|1] ""  MHU
 SG_ WarnMsgID_417 : 429|1@0+ (1,0) [0|1] ""  MHU
 SG_ WarnMsgID_418 : 430|1@0+ (1,0) [0|1] ""  MHU
 SG_ WarnMsgID_419 : 431|1@0+ (1,0) [0|1] ""  MHU
 SG_ WarnMsgID_420 : 432|1@0+ (1,0) [0|1] ""  MHU
 SG_ WarnMsgID_421 : 433|1@0+ (1,0) [0|1] ""  MHU
 SG_ WarnMsgID_422 : 434|1@0+ (1,0) [0|1] ""  MHU
 SG_ WarnMsgID_423 : 435|1@0+ (1,0) [0|1] ""  MHU
 SG_ WarnMsgID_424 : 436|1@0+ (1,0) [0|1] ""  MHU
 SG_ WarnMsgID_425 : 437|1@0+ (1,0) [0|1] ""  MHU
 SG_ WarnMsgID_426 : 438|1@0+ (1,0) [0|1] ""  MHU
 SG_ WarnMsgID_427 : 439|1@0+ (1,0) [0|1] ""  MHU
 SG_ WarnMsgID_428 : 440|1@0+ (1,0) [0|1] ""  MHU
 SG_ WarnMsgID_429 : 441|1@0+ (1,0) [0|1] ""  MHU
 SG_ WarnMsgID_430 : 442|1@0+ (1,0) [0|1] ""  MHU
 SG_ WarnMsgID_431 : 443|1@0+ (1,0) [0|1] ""  MHU
 SG_ WarnMsgID_432 : 444|1@0+ (1,0) [0|1] ""  MHU
 SG_ WarnMsgID_433 : 445|1@0+ (1,0) [0|1] ""  MHU
 SG_ WarnMsgID_434 : 446|1@0+ (1,0) [0|1] ""  MHU
 SG_ WarnMsgID_435 : 447|1@0+ (1,0) [0|1] ""  MHU
 SG_ WarnMsgID_436 : 448|1@0+ (1,0) [0|1] ""  MHU
 SG_ WarnMsgID_437 : 449|1@0+ (1,0) [0|1] ""  MHU
 SG_ WarnMsgID_438 : 450|1@0+ (1,0) [0|1] ""  MHU
 SG_ WarnMsgID_439 : 451|1@0+ (1,0) [0|1] ""  MHU
 SG_ WarnMsgID_440 : 452|1@0+ (1,0) [0|1] ""  MHU
 SG_ WarnMsgID_441 : 453|1@0+ (1,0) [0|1] ""  MHU
 SG_ WarnMsgID_442 : 454|1@0+ (1,0) [0|1] ""  MHU
 SG_ WarnMsgID_443 : 455|1@0+ (1,0) [0|1] ""  MHU
 SG_ WarnMsgID_444 : 456|1@0+ (1,0) [0|1] ""  MHU
 SG_ WarnMsgID_445 : 457|1@0+ (1,0) [0|1] ""  MHU
 SG_ WarnMsgID_446 : 458|1@0+ (1,0) [0|1] ""  MHU
 SG_ WarnMsgID_447 : 459|1@0+ (1,0) [0|1] ""  MHU
 SG_ WarnMsgID_448 : 460|1@0+ (1,0) [0|1] ""  MHU
 SG_ WarnMsgID_449 : 461|1@0+ (1,0) [0|1] ""  MHU
 SG_ WarnMsgID_450 : 462|1@0+ (1,0) [0|1] ""  MHU
 SG_ WarnMsgID_451 : 463|1@0+ (1,0) [0|1] ""  MHU
 SG_ WarnMsgID_452 : 464|1@0+ (1,0) [0|1] ""  MHU
 SG_ WarnMsgID_453 : 465|1@0+ (1,0) [0|1] ""  MHU
 SG_ WarnMsgID_454 : 466|1@0+ (1,0) [0|1] ""  MHU
 SG_ WarnMsgID_455 : 467|1@0+ (1,0) [0|1] ""  MHU
 SG_ WarnMsgID_456 : 468|1@0+ (1,0) [0|1] ""  MHU
 SG_ WarnMsgID_457 : 469|1@0+ (1,0) [0|1] ""  MHU
 SG_ WarnMsgID_458 : 470|1@0+ (1,0) [0|1] ""  MHU
 SG_ WarnMsgID_459 : 471|1@0+ (1,0) [0|1] ""  MHU
 SG_ WarnMsgID_460 : 472|1@0+ (1,0) [0|1] ""  MHU
 SG_ WarnMsgID_461 : 473|1@0+ (1,0) [0|1] ""  MHU
 SG_ WarnMsgID_462 : 474|1@0+ (1,0) [0|1] ""  MHU
 SG_ WarnMsgID_463 : 475|1@0+ (1,0) [0|1] ""  MHU
 SG_ WarnMsgID_464 : 476|1@0+ (1,0) [0|1] ""  MHU
 SG_ WarnMsgID_465 : 477|1@0+ (1,0) [0|1] ""  MHU
 SG_ WarnMsgID_466 : 478|1@0+ (1,0) [0|1] ""  MHU
 SG_ WarnMsgID_467 : 479|1@0+ (1,0) [0|1] ""  MHU
 SG_ WarnMsgID_468 : 480|1@0+ (1,0) [0|1] ""  MHU
 SG_ WarnMsgID_469 : 481|1@0+ (1,0) [0|1] ""  MHU
 SG_ WarnMsgID_470 : 482|1@0+ (1,0) [0|1] ""  MHU
 SG_ WarnMsgID_471 : 483|1@0+ (1,0) [0|1] ""  MHU
 SG_ WarnMsgID_472 : 484|1@0+ (1,0) [0|1] ""  MHU
 SG_ WarnMsgID_473 : 485|1@0+ (1,0) [0|1] ""  MHU
 SG_ WarnMsgID_474 : 486|1@0+ (1,0) [0|1] ""  MHU
 SG_ WarnMsgID_475 : 487|1@0+ (1,0) [0|1] ""  MHU
 SG_ WarnMsgID_476 : 488|1@0+ (1,0) [0|1] ""  MHU
 SG_ WarnMsgID_477 : 489|1@0+ (1,0) [0|1] ""  MHU
 SG_ WarnMsgID_478 : 490|1@0+ (1,0) [0|1] ""  MHU
 SG_ WarnMsgID_479 : 491|1@0+ (1,0) [0|1] ""  MHU
 SG_ WarnMsgID_480 : 492|1@0+ (1,0) [0|1] ""  MHU
 SG_ WarnMsgID_481 : 493|1@0+ (1,0) [0|1] ""  MHU
 SG_ WarnMsgID_482 : 494|1@0+ (1,0) [0|1] ""  MHU
 SG_ WarnMsgID_483 : 495|1@0+ (1,0) [0|1] ""  MHU
 SG_ WarnMsgID_484 : 496|1@0+ (1,0) [0|1] ""  MHU
 SG_ WarnMsgID_485 : 497|1@0+ (1,0) [0|1] ""  MHU
 SG_ WarnMsgID_486 : 498|1@0+ (1,0) [0|1] ""  MHU
 SG_ WarnMsgID_487 : 499|1@0+ (1,0) [0|1] ""  MHU
 SG_ WarnMsgID_488 : 500|1@0+ (1,0) [0|1] ""  MHU
 SG_ WarnMsgID_489 : 501|1@0+ (1,0) [0|1] ""  MHU
 SG_ WarnMsgID_490 : 502|1@0+ (1,0) [0|1] ""  MHU
 SG_ WarnMsgID_491 : 503|1@0+ (1,0) [0|1] ""  MHU
 SG_ WarnMsgID_492 : 504|1@0+ (1,0) [0|1] ""  MHU
 SG_ WarnMsgID_493 : 505|1@0+ (1,0) [0|1] ""  MHU
 SG_ WarnMsgID_494 : 506|1@0+ (1,0) [0|1] ""  MHU
 SG_ WarnMsgID_495 : 507|1@0+ (1,0) [0|1] ""  MHU
 SG_ WarnMsgID_496 : 508|1@0+ (1,0) [0|1] ""  MHU
 SG_ WarnMsgID_497 : 509|1@0+ (1,0) [0|1] ""  MHU
 SG_ WarnMsgID_498 : 510|1@0+ (1,0) [0|1] ""  MHU
 SG_ WarnMsgID_499 : 511|1@0+ (1,0) [0|1] ""  MHU

BO_ 1249 CVC_WarnMsgID_2: 64 CVC_I
 SG_ CRC_CVC_WarnMsgID_2 : 7|8@0+ (1,0) [0|255] ""  MHU
 SG_ ALIVE_CVC_WarnMsgID_2 : 11|4@0+ (1,0) [0|15] ""  MHU
 SG_ WarnMsgID_500 : 12|1@0+ (1,0) [0|1] ""  MHU
 SG_ WarnMsgID_501 : 13|1@0+ (1,0) [0|1] ""  MHU
 SG_ WarnMsgID_502 : 14|1@0+ (1,0) [0|1] ""  MHU
 SG_ WarnMsgID_503 : 15|1@0+ (1,0) [0|1] ""  MHU
 SG_ WarnMsgID_504 : 16|1@0+ (1,0) [0|1] ""  MHU
 SG_ WarnMsgID_505 : 17|1@0+ (1,0) [0|1] ""  MHU
 SG_ WarnMsgID_506 : 18|1@0+ (1,0) [0|1] ""  MHU
 SG_ WarnMsgID_507 : 19|1@0+ (1,0) [0|1] ""  MHU
 SG_ WarnMsgID_508 : 20|1@0+ (1,0) [0|1] ""  MHU
 SG_ WarnMsgID_509 : 21|1@0+ (1,0) [0|1] ""  MHU
 SG_ WarnMsgID_510 : 22|1@0+ (1,0) [0|1] ""  MHU
 SG_ WarnMsgID_511 : 23|1@0+ (1,0) [0|1] ""  MHU
 SG_ WarnMsgID_512 : 24|1@0+ (1,0) [0|1] ""  MHU
 SG_ WarnMsgID_513 : 25|1@0+ (1,0) [0|1] ""  MHU
 SG_ WarnMsgID_514 : 26|1@0+ (1,0) [0|1] ""  MHU
 SG_ WarnMsgID_515 : 27|1@0+ (1,0) [0|1] ""  MHU
 SG_ WarnMsgID_516 : 28|1@0+ (1,0) [0|1] ""  MHU
 SG_ WarnMsgID_517 : 29|1@0+ (1,0) [0|1] ""  MHU
 SG_ WarnMsgID_518 : 30|1@0+ (1,0) [0|1] ""  MHU
 SG_ WarnMsgID_519 : 31|1@0+ (1,0) [0|1] ""  MHU
 SG_ WarnMsgID_520 : 32|1@0+ (1,0) [0|1] ""  MHU
 SG_ WarnMsgID_521 : 33|1@0+ (1,0) [0|1] ""  MHU
 SG_ WarnMsgID_522 : 34|1@0+ (1,0) [0|1] ""  MHU
 SG_ WarnMsgID_523 : 35|1@0+ (1,0) [0|1] ""  MHU
 SG_ WarnMsgID_524 : 36|1@0+ (1,0) [0|1] ""  MHU
 SG_ WarnMsgID_525 : 37|1@0+ (1,0) [0|1] ""  MHU
 SG_ WarnMsgID_526 : 38|1@0+ (1,0) [0|1] ""  MHU
 SG_ WarnMsgID_527 : 39|1@0+ (1,0) [0|1] ""  MHU
 SG_ WarnMsgID_528 : 40|1@0+ (1,0) [0|1] ""  MHU
 SG_ WarnMsgID_529 : 41|1@0+ (1,0) [0|1] ""  MHU
 SG_ WarnMsgID_530 : 42|1@0+ (1,0) [0|1] ""  MHU
 SG_ WarnMsgID_531 : 43|1@0+ (1,0) [0|1] ""  MHU
 SG_ WarnMsgID_532 : 44|1@0+ (1,0) [0|1] ""  MHU
 SG_ WarnMsgID_533 : 45|1@0+ (1,0) [0|1] ""  MHU
 SG_ WarnMsgID_534 : 46|1@0+ (1,0) [0|1] ""  MHU
 SG_ WarnMsgID_535 : 47|1@0+ (1,0) [0|1] ""  MHU
 SG_ WarnMsgID_536 : 48|1@0+ (1,0) [0|1] ""  MHU
 SG_ WarnMsgID_537 : 49|1@0+ (1,0) [0|1] ""  MHU
 SG_ WarnMsgID_538 : 50|1@0+ (1,0) [0|1] ""  MHU
 SG_ WarnMsgID_539 : 51|1@0+ (1,0) [0|1] ""  MHU
 SG_ WarnMsgID_540 : 52|1@0+ (1,0) [0|1] ""  MHU
 SG_ WarnMsgID_541 : 53|1@0+ (1,0) [0|1] ""  MHU
 SG_ WarnMsgID_542 : 54|1@0+ (1,0) [0|1] ""  MHU
 SG_ WarnMsgID_543 : 55|1@0+ (1,0) [0|1] ""  MHU
 SG_ WarnMsgID_544 : 56|1@0+ (1,0) [0|1] ""  MHU
 SG_ WarnMsgID_545 : 57|1@0+ (1,0) [0|1] ""  MHU
 SG_ WarnMsgID_546 : 58|1@0+ (1,0) [0|1] ""  MHU
 SG_ WarnMsgID_547 : 59|1@0+ (1,0) [0|1] ""  MHU
 SG_ WarnMsgID_548 : 60|1@0+ (1,0) [0|1] ""  MHU
 SG_ WarnMsgID_549 : 61|1@0+ (1,0) [0|1] ""  MHU
 SG_ WarnMsgID_550 : 62|1@0+ (1,0) [0|1] ""  MHU
 SG_ WarnMsgID_551 : 63|1@0+ (1,0) [0|1] ""  MHU
 SG_ WarnMsgID_552 : 64|1@0+ (1,0) [0|1] ""  MHU
 SG_ WarnMsgID_553 : 65|1@0+ (1,0) [0|1] ""  MHU
 SG_ WarnMsgID_554 : 66|1@0+ (1,0) [0|1] ""  MHU
 SG_ WarnMsgID_555 : 67|1@0+ (1,0) [0|1] ""  MHU
 SG_ WarnMsgID_556 : 68|1@0+ (1,0) [0|1] ""  MHU
 SG_ WarnMsgID_557 : 69|1@0+ (1,0) [0|1] ""  MHU
 SG_ WarnMsgID_558 : 70|1@0+ (1,0) [0|1] ""  MHU
 SG_ WarnMsgID_559 : 71|1@0+ (1,0) [0|1] ""  MHU
 SG_ WarnMsgID_560 : 72|1@0+ (1,0) [0|1] ""  MHU
 SG_ WarnMsgID_561 : 73|1@0+ (1,0) [0|1] ""  MHU
 SG_ WarnMsgID_562 : 74|1@0+ (1,0) [0|1] ""  MHU
 SG_ WarnMsgID_563 : 75|1@0+ (1,0) [0|1] ""  MHU
 SG_ WarnMsgID_564 : 76|1@0+ (1,0) [0|1] ""  MHU
 SG_ WarnMsgID_565 : 77|1@0+ (1,0) [0|1] ""  MHU
 SG_ WarnMsgID_566 : 78|1@0+ (1,0) [0|1] ""  MHU
 SG_ WarnMsgID_567 : 79|1@0+ (1,0) [0|1] ""  MHU
 SG_ WarnMsgID_568 : 80|1@0+ (1,0) [0|1] ""  MHU
 SG_ WarnMsgID_569 : 81|1@0+ (1,0) [0|1] ""  MHU
 SG_ WarnMsgID_570 : 82|1@0+ (1,0) [0|1] ""  MHU
 SG_ WarnMsgID_571 : 83|1@0+ (1,0) [0|1] ""  MHU
 SG_ WarnMsgID_572 : 84|1@0+ (1,0) [0|1] ""  MHU
 SG_ WarnMsgID_573 : 85|1@0+ (1,0) [0|1] ""  MHU
 SG_ WarnMsgID_574 : 86|1@0+ (1,0) [0|1] ""  MHU
 SG_ WarnMsgID_575 : 87|1@0+ (1,0) [0|1] ""  MHU
 SG_ WarnMsgID_576 : 88|1@0+ (1,0) [0|1] ""  MHU
 SG_ WarnMsgID_577 : 89|1@0+ (1,0) [0|1] ""  MHU
 SG_ WarnMsgID_578 : 90|1@0+ (1,0) [0|1] ""  MHU
 SG_ WarnMsgID_579 : 91|1@0+ (1,0) [0|1] ""  MHU
 SG_ WarnMsgID_580 : 92|1@0+ (1,0) [0|1] ""  MHU
 SG_ WarnMsgID_581 : 93|1@0+ (1,0) [0|1] ""  MHU
 SG_ WarnMsgID_582 : 94|1@0+ (1,0) [0|1] ""  MHU
 SG_ WarnMsgID_583 : 95|1@0+ (1,0) [0|1] ""  MHU
 SG_ WarnMsgID_584 : 96|1@0+ (1,0) [0|1] ""  MHU
 SG_ WarnMsgID_585 : 97|1@0+ (1,0) [0|1] ""  MHU
 SG_ WarnMsgID_586 : 98|1@0+ (1,0) [0|1] ""  MHU
 SG_ WarnMsgID_587 : 99|1@0+ (1,0) [0|1] ""  MHU
 SG_ WarnMsgID_588 : 100|1@0+ (1,0) [0|1] ""  MHU
 SG_ WarnMsgID_589 : 101|1@0+ (1,0) [0|1] ""  MHU
 SG_ WarnMsgID_590 : 102|1@0+ (1,0) [0|1] ""  MHU
 SG_ WarnMsgID_591 : 103|1@0+ (1,0) [0|1] ""  MHU
 SG_ WarnMsgID_592 : 104|1@0+ (1,0) [0|1] ""  MHU
 SG_ WarnMsgID_593 : 105|1@0+ (1,0) [0|1] ""  MHU
 SG_ WarnMsgID_594 : 106|1@0+ (1,0) [0|1] ""  MHU
 SG_ WarnMsgID_595 : 107|1@0+ (1,0) [0|1] ""  MHU
 SG_ WarnMsgID_596 : 108|1@0+ (1,0) [0|1] ""  MHU
 SG_ WarnMsgID_597 : 109|1@0+ (1,0) [0|1] ""  MHU
 SG_ WarnMsgID_598 : 110|1@0+ (1,0) [0|1] ""  MHU
 SG_ WarnMsgID_599 : 111|1@0+ (1,0) [0|1] ""  MHU
 SG_ WarnMsgID_600 : 112|1@0+ (1,0) [0|1] ""  MHU
 SG_ WarnMsgID_601 : 113|1@0+ (1,0) [0|1] ""  MHU
 SG_ WarnMsgID_602 : 114|1@0+ (1,0) [0|1] ""  MHU
 SG_ WarnMsgID_603 : 115|1@0+ (1,0) [0|1] ""  MHU
 SG_ WarnMsgID_604 : 116|1@0+ (1,0) [0|1] ""  MHU
 SG_ WarnMsgID_605 : 117|1@0+ (1,0) [0|1] ""  MHU
 SG_ WarnMsgID_606 : 118|1@0+ (1,0) [0|1] ""  MHU
 SG_ WarnMsgID_607 : 119|1@0+ (1,0) [0|1] ""  MHU
 SG_ WarnMsgID_608 : 120|1@0+ (1,0) [0|1] ""  MHU
 SG_ WarnMsgID_609 : 121|1@0+ (1,0) [0|1] ""  MHU
 SG_ WarnMsgID_610 : 122|1@0+ (1,0) [0|1] ""  MHU
 SG_ WarnMsgID_611 : 123|1@0+ (1,0) [0|1] ""  MHU
 SG_ WarnMsgID_612 : 124|1@0+ (1,0) [0|1] ""  MHU
 SG_ WarnMsgID_613 : 125|1@0+ (1,0) [0|1] ""  MHU
 SG_ WarnMsgID_614 : 126|1@0+ (1,0) [0|1] ""  MHU
 SG_ WarnMsgID_615 : 127|1@0+ (1,0) [0|1] ""  MHU
 SG_ WarnMsgID_616 : 128|1@0+ (1,0) [0|1] ""  MHU
 SG_ WarnMsgID_617 : 129|1@0+ (1,0) [0|1] ""  MHU
 SG_ WarnMsgID_618 : 130|1@0+ (1,0) [0|1] ""  MHU
 SG_ WarnMsgID_619 : 131|1@0+ (1,0) [0|1] ""  MHU
 SG_ WarnMsgID_620 : 132|1@0+ (1,0) [0|1] ""  MHU
 SG_ WarnMsgID_621 : 133|1@0+ (1,0) [0|1] ""  MHU
 SG_ WarnMsgID_622 : 134|1@0+ (1,0) [0|1] ""  MHU
 SG_ WarnMsgID_623 : 135|1@0+ (1,0) [0|1] ""  MHU
 SG_ WarnMsgID_624 : 136|1@0+ (1,0) [0|1] ""  MHU
 SG_ WarnMsgID_625 : 137|1@0+ (1,0) [0|1] ""  MHU
 SG_ WarnMsgID_626 : 138|1@0+ (1,0) [0|1] ""  MHU
 SG_ WarnMsgID_627 : 139|1@0+ (1,0) [0|1] ""  MHU
 SG_ WarnMsgID_628 : 140|1@0+ (1,0) [0|1] ""  MHU
 SG_ WarnMsgID_629 : 141|1@0+ (1,0) [0|1] ""  MHU
 SG_ WarnMsgID_630 : 142|1@0+ (1,0) [0|1] ""  MHU
 SG_ WarnMsgID_631 : 143|1@0+ (1,0) [0|1] ""  MHU
 SG_ WarnMsgID_632 : 144|1@0+ (1,0) [0|1] ""  MHU
 SG_ WarnMsgID_633 : 145|1@0+ (1,0) [0|1] ""  MHU
 SG_ WarnMsgID_634 : 146|1@0+ (1,0) [0|1] ""  MHU
 SG_ WarnMsgID_635 : 147|1@0+ (1,0) [0|1] ""  MHU
 SG_ WarnMsgID_636 : 148|1@0+ (1,0) [0|1] ""  MHU
 SG_ WarnMsgID_637 : 149|1@0+ (1,0) [0|1] ""  MHU
 SG_ WarnMsgID_638 : 150|1@0+ (1,0) [0|1] ""  MHU
 SG_ WarnMsgID_639 : 151|1@0+ (1,0) [0|1] ""  MHU
 SG_ WarnMsgID_640 : 152|1@0+ (1,0) [0|1] ""  MHU
 SG_ WarnMsgID_641 : 153|1@0+ (1,0) [0|1] ""  MHU
 SG_ WarnMsgID_642 : 154|1@0+ (1,0) [0|1] ""  MHU
 SG_ WarnMsgID_643 : 155|1@0+ (1,0) [0|1] ""  MHU
 SG_ WarnMsgID_644 : 156|1@0+ (1,0) [0|1] ""  MHU
 SG_ WarnMsgID_645 : 157|1@0+ (1,0) [0|1] ""  MHU
 SG_ WarnMsgID_646 : 158|1@0+ (1,0) [0|1] ""  MHU
 SG_ WarnMsgID_647 : 159|1@0+ (1,0) [0|1] ""  MHU
 SG_ WarnMsgID_648 : 160|1@0+ (1,0) [0|1] ""  MHU
 SG_ WarnMsgID_649 : 161|1@0+ (1,0) [0|1] ""  MHU
 SG_ WarnMsgID_650 : 162|1@0+ (1,0) [0|1] ""  MHU
 SG_ WarnMsgID_651 : 163|1@0+ (1,0) [0|1] ""  MHU
 SG_ WarnMsgID_652 : 164|1@0+ (1,0) [0|1] ""  MHU
 SG_ WarnMsgID_653 : 165|1@0+ (1,0) [0|1] ""  MHU
 SG_ WarnMsgID_654 : 166|1@0+ (1,0) [0|1] ""  MHU
 SG_ WarnMsgID_655 : 167|1@0+ (1,0) [0|1] ""  MHU
 SG_ WarnMsgID_656 : 168|1@0+ (1,0) [0|1] ""  MHU
 SG_ WarnMsgID_657 : 169|1@0+ (1,0) [0|1] ""  MHU
 SG_ WarnMsgID_658 : 170|1@0+ (1,0) [0|1] ""  MHU
 SG_ WarnMsgID_659 : 171|1@0+ (1,0) [0|1] ""  MHU
 SG_ WarnMsgID_660 : 172|1@0+ (1,0) [0|1] ""  MHU
 SG_ WarnMsgID_661 : 173|1@0+ (1,0) [0|1] ""  MHU
 SG_ WarnMsgID_662 : 174|1@0+ (1,0) [0|1] ""  MHU
 SG_ WarnMsgID_663 : 175|1@0+ (1,0) [0|1] ""  MHU
 SG_ WarnMsgID_664 : 176|1@0+ (1,0) [0|1] ""  MHU
 SG_ WarnMsgID_665 : 177|1@0+ (1,0) [0|1] ""  MHU
 SG_ WarnMsgID_666 : 178|1@0+ (1,0) [0|1] ""  MHU
 SG_ WarnMsgID_667 : 179|1@0+ (1,0) [0|1] ""  MHU
 SG_ WarnMsgID_668 : 180|1@0+ (1,0) [0|1] ""  MHU
 SG_ WarnMsgID_669 : 181|1@0+ (1,0) [0|1] ""  MHU
 SG_ WarnMsgID_670 : 182|1@0+ (1,0) [0|1] ""  MHU
 SG_ WarnMsgID_671 : 183|1@0+ (1,0) [0|1] ""  MHU
 SG_ WarnMsgID_672 : 184|1@0+ (1,0) [0|1] ""  MHU
 SG_ WarnMsgID_673 : 185|1@0+ (1,0) [0|1] ""  MHU
 SG_ WarnMsgID_674 : 186|1@0+ (1,0) [0|1] ""  MHU
 SG_ WarnMsgID_675 : 187|1@0+ (1,0) [0|1] ""  MHU
 SG_ WarnMsgID_676 : 188|1@0+ (1,0) [0|1] ""  MHU
 SG_ WarnMsgID_677 : 189|1@0+ (1,0) [0|1] ""  MHU
 SG_ WarnMsgID_678 : 190|1@0+ (1,0) [0|1] ""  MHU
 SG_ WarnMsgID_679 : 191|1@0+ (1,0) [0|1] ""  MHU
 SG_ WarnMsgID_680 : 192|1@0+ (1,0) [0|1] ""  MHU
 SG_ WarnMsgID_681 : 193|1@0+ (1,0) [0|1] ""  MHU
 SG_ WarnMsgID_682 : 194|1@0+ (1,0) [0|1] ""  MHU
 SG_ WarnMsgID_683 : 195|1@0+ (1,0) [0|1] ""  MHU
 SG_ WarnMsgID_684 : 196|1@0+ (1,0) [0|1] ""  MHU
 SG_ WarnMsgID_685 : 197|1@0+ (1,0) [0|1] ""  MHU
 SG_ WarnMsgID_686 : 198|1@0+ (1,0) [0|1] ""  MHU
 SG_ WarnMsgID_687 : 199|1@0+ (1,0) [0|1] ""  MHU
 SG_ WarnMsgID_688 : 200|1@0+ (1,0) [0|1] ""  MHU
 SG_ WarnMsgID_689 : 201|1@0+ (1,0) [0|1] ""  MHU
 SG_ WarnMsgID_690 : 202|1@0+ (1,0) [0|1] ""  MHU
 SG_ WarnMsgID_691 : 203|1@0+ (1,0) [0|1] ""  MHU
 SG_ WarnMsgID_692 : 204|1@0+ (1,0) [0|1] ""  MHU
 SG_ WarnMsgID_693 : 205|1@0+ (1,0) [0|1] ""  MHU
 SG_ WarnMsgID_694 : 206|1@0+ (1,0) [0|1] ""  MHU
 SG_ WarnMsgID_695 : 207|1@0+ (1,0) [0|1] ""  MHU
 SG_ WarnMsgID_696 : 208|1@0+ (1,0) [0|1] ""  MHU
 SG_ WarnMsgID_697 : 209|1@0+ (1,0) [0|1] ""  MHU
 SG_ WarnMsgID_698 : 210|1@0+ (1,0) [0|1] ""  MHU
 SG_ WarnMsgID_699 : 211|1@0+ (1,0) [0|1] ""  MHU
 SG_ WarnMsgID_700 : 212|1@0+ (1,0) [0|1] ""  MHU
 SG_ WarnMsgID_701 : 213|1@0+ (1,0) [0|1] ""  MHU
 SG_ WarnMsgID_702 : 214|1@0+ (1,0) [0|1] ""  MHU
 SG_ WarnMsgID_703 : 215|1@0+ (1,0) [0|1] ""  MHU
 SG_ WarnMsgID_704 : 216|1@0+ (1,0) [0|1] ""  MHU
 SG_ WarnMsgID_705 : 217|1@0+ (1,0) [0|1] ""  MHU
 SG_ WarnMsgID_706 : 218|1@0+ (1,0) [0|1] ""  MHU
 SG_ WarnMsgID_707 : 219|1@0+ (1,0) [0|1] ""  MHU
 SG_ WarnMsgID_708 : 220|1@0+ (1,0) [0|1] ""  MHU
 SG_ WarnMsgID_709 : 221|1@0+ (1,0) [0|1] ""  MHU
 SG_ WarnMsgID_710 : 222|1@0+ (1,0) [0|1] ""  MHU
 SG_ WarnMsgID_711 : 223|1@0+ (1,0) [0|1] ""  MHU
 SG_ WarnMsgID_712 : 224|1@0+ (1,0) [0|1] ""  MHU
 SG_ WarnMsgID_713 : 225|1@0+ (1,0) [0|1] ""  MHU
 SG_ WarnMsgID_714 : 226|1@0+ (1,0) [0|1] ""  MHU
 SG_ WarnMsgID_715 : 227|1@0+ (1,0) [0|1] ""  MHU
 SG_ WarnMsgID_716 : 228|1@0+ (1,0) [0|1] ""  MHU
 SG_ WarnMsgID_717 : 229|1@0+ (1,0) [0|1] ""  MHU
 SG_ WarnMsgID_718 : 230|1@0+ (1,0) [0|1] ""  MHU
 SG_ WarnMsgID_719 : 231|1@0+ (1,0) [0|1] ""  MHU
 SG_ WarnMsgID_720 : 232|1@0+ (1,0) [0|1] ""  MHU
 SG_ WarnMsgID_721 : 233|1@0+ (1,0) [0|1] ""  MHU
 SG_ WarnMsgID_722 : 234|1@0+ (1,0) [0|1] ""  MHU
 SG_ WarnMsgID_723 : 235|1@0+ (1,0) [0|1] ""  MHU
 SG_ WarnMsgID_724 : 236|1@0+ (1,0) [0|1] ""  MHU
 SG_ WarnMsgID_725 : 237|1@0+ (1,0) [0|1] ""  MHU
 SG_ WarnMsgID_726 : 238|1@0+ (1,0) [0|1] ""  MHU
 SG_ WarnMsgID_727 : 239|1@0+ (1,0) [0|1] ""  MHU
 SG_ WarnMsgID_728 : 240|1@0+ (1,0) [0|1] ""  MHU
 SG_ WarnMsgID_729 : 241|1@0+ (1,0) [0|1] ""  MHU
 SG_ WarnMsgID_730 : 242|1@0+ (1,0) [0|1] ""  MHU
 SG_ WarnMsgID_731 : 243|1@0+ (1,0) [0|1] ""  MHU
 SG_ WarnMsgID_732 : 244|1@0+ (1,0) [0|1] ""  MHU
 SG_ WarnMsgID_733 : 245|1@0+ (1,0) [0|1] ""  MHU
 SG_ WarnMsgID_734 : 246|1@0+ (1,0) [0|1] ""  MHU
 SG_ WarnMsgID_735 : 247|1@0+ (1,0) [0|1] ""  MHU
 SG_ WarnMsgID_736 : 248|1@0+ (1,0) [0|1] ""  MHU
 SG_ WarnMsgID_737 : 249|1@0+ (1,0) [0|1] ""  MHU
 SG_ WarnMsgID_738 : 250|1@0+ (1,0) [0|1] ""  MHU
 SG_ WarnMsgID_739 : 251|1@0+ (1,0) [0|1] ""  MHU
 SG_ WarnMsgID_740 : 252|1@0+ (1,0) [0|1] ""  MHU
 SG_ WarnMsgID_741 : 253|1@0+ (1,0) [0|1] ""  MHU
 SG_ WarnMsgID_742 : 254|1@0+ (1,0) [0|1] ""  MHU
 SG_ WarnMsgID_743 : 255|1@0+ (1,0) [0|1] ""  MHU
 SG_ WarnMsgID_744 : 256|1@0+ (1,0) [0|1] ""  MHU
 SG_ WarnMsgID_745 : 257|1@0+ (1,0) [0|1] ""  MHU
 SG_ WarnMsgID_746 : 258|1@0+ (1,0) [0|1] ""  MHU
 SG_ WarnMsgID_747 : 259|1@0+ (1,0) [0|1] ""  MHU
 SG_ WarnMsgID_748 : 260|1@0+ (1,0) [0|1] ""  MHU
 SG_ WarnMsgID_749 : 261|1@0+ (1,0) [0|1] ""  MHU
 SG_ WarnMsgID_750 : 262|1@0+ (1,0) [0|1] ""  MHU
 SG_ WarnMsgID_751 : 263|1@0+ (1,0) [0|1] ""  MHU
 SG_ WarnMsgID_752 : 264|1@0+ (1,0) [0|1] ""  MHU
 SG_ WarnMsgID_753 : 265|1@0+ (1,0) [0|1] ""  MHU
 SG_ WarnMsgID_754 : 266|1@0+ (1,0) [0|1] ""  MHU
 SG_ WarnMsgID_755 : 267|1@0+ (1,0) [0|1] ""  MHU
 SG_ WarnMsgID_756 : 268|1@0+ (1,0) [0|1] ""  MHU
 SG_ WarnMsgID_757 : 269|1@0+ (1,0) [0|1] ""  MHU
 SG_ WarnMsgID_758 : 270|1@0+ (1,0) [0|1] ""  MHU
 SG_ WarnMsgID_759 : 271|1@0+ (1,0) [0|1] ""  MHU
 SG_ WarnMsgID_760 : 272|1@0+ (1,0) [0|1] ""  MHU
 SG_ WarnMsgID_761 : 273|1@0+ (1,0) [0|1] ""  MHU
 SG_ WarnMsgID_762 : 274|1@0+ (1,0) [0|1] ""  MHU
 SG_ WarnMsgID_763 : 275|1@0+ (1,0) [0|1] ""  MHU
 SG_ WarnMsgID_764 : 276|1@0+ (1,0) [0|1] ""  MHU
 SG_ WarnMsgID_765 : 277|1@0+ (1,0) [0|1] ""  MHU
 SG_ WarnMsgID_766 : 278|1@0+ (1,0) [0|1] ""  MHU
 SG_ WarnMsgID_767 : 279|1@0+ (1,0) [0|1] ""  MHU
 SG_ WarnMsgID_768 : 280|1@0+ (1,0) [0|1] ""  MHU
 SG_ WarnMsgID_769 : 281|1@0+ (1,0) [0|1] ""  MHU
 SG_ WarnMsgID_770 : 282|1@0+ (1,0) [0|1] ""  MHU
 SG_ WarnMsgID_771 : 283|1@0+ (1,0) [0|1] ""  MHU
 SG_ WarnMsgID_772 : 284|1@0+ (1,0) [0|1] ""  MHU
 SG_ WarnMsgID_773 : 285|1@0+ (1,0) [0|1] ""  MHU
 SG_ WarnMsgID_774 : 286|1@0+ (1,0) [0|1] ""  MHU
 SG_ WarnMsgID_775 : 287|1@0+ (1,0) [0|1] ""  MHU
 SG_ WarnMsgID_776 : 288|1@0+ (1,0) [0|1] ""  MHU
 SG_ WarnMsgID_777 : 289|1@0+ (1,0) [0|1] ""  MHU
 SG_ WarnMsgID_778 : 290|1@0+ (1,0) [0|1] ""  MHU
 SG_ WarnMsgID_779 : 291|1@0+ (1,0) [0|1] ""  MHU
 SG_ WarnMsgID_780 : 292|1@0+ (1,0) [0|1] ""  MHU
 SG_ WarnMsgID_781 : 293|1@0+ (1,0) [0|1] ""  MHU
 SG_ WarnMsgID_782 : 294|1@0+ (1,0) [0|1] ""  MHU
 SG_ WarnMsgID_783 : 295|1@0+ (1,0) [0|1] ""  MHU
 SG_ WarnMsgID_784 : 296|1@0+ (1,0) [0|1] ""  MHU
 SG_ WarnMsgID_785 : 297|1@0+ (1,0) [0|1] ""  MHU
 SG_ WarnMsgID_786 : 298|1@0+ (1,0) [0|1] ""  MHU
 SG_ WarnMsgID_787 : 299|1@0+ (1,0) [0|1] ""  MHU
 SG_ WarnMsgID_788 : 300|1@0+ (1,0) [0|1] ""  MHU
 SG_ WarnMsgID_789 : 301|1@0+ (1,0) [0|1] ""  MHU
 SG_ WarnMsgID_790 : 302|1@0+ (1,0) [0|1] ""  MHU
 SG_ WarnMsgID_791 : 303|1@0+ (1,0) [0|1] ""  MHU
 SG_ WarnMsgID_792 : 304|1@0+ (1,0) [0|1] ""  MHU
 SG_ WarnMsgID_793 : 305|1@0+ (1,0) [0|1] ""  MHU
 SG_ WarnMsgID_794 : 306|1@0+ (1,0) [0|1] ""  MHU
 SG_ WarnMsgID_795 : 307|1@0+ (1,0) [0|1] ""  MHU
 SG_ WarnMsgID_796 : 308|1@0+ (1,0) [0|1] ""  MHU
 SG_ WarnMsgID_797 : 309|1@0+ (1,0) [0|1] ""  MHU
 SG_ WarnMsgID_798 : 310|1@0+ (1,0) [0|1] ""  MHU
 SG_ WarnMsgID_799 : 311|1@0+ (1,0) [0|1] ""  MHU
 SG_ WarnMsgID_800 : 312|1@0+ (1,0) [0|1] ""  MHU
 SG_ WarnMsgID_801 : 313|1@0+ (1,0) [0|1] ""  MHU
 SG_ WarnMsgID_802 : 314|1@0+ (1,0) [0|1] ""  MHU
 SG_ WarnMsgID_803 : 315|1@0+ (1,0) [0|1] ""  MHU
 SG_ WarnMsgID_804 : 316|1@0+ (1,0) [0|1] ""  MHU
 SG_ WarnMsgID_805 : 317|1@0+ (1,0) [0|1] ""  MHU
 SG_ WarnMsgID_806 : 318|1@0+ (1,0) [0|1] ""  MHU
 SG_ WarnMsgID_807 : 319|1@0+ (1,0) [0|1] ""  MHU
 SG_ WarnMsgID_808 : 320|1@0+ (1,0) [0|1] ""  MHU
 SG_ WarnMsgID_809 : 321|1@0+ (1,0) [0|1] ""  MHU
 SG_ WarnMsgID_810 : 322|1@0+ (1,0) [0|1] ""  MHU
 SG_ WarnMsgID_811 : 323|1@0+ (1,0) [0|1] ""  MHU
 SG_ WarnMsgID_812 : 324|1@0+ (1,0) [0|1] ""  MHU
 SG_ WarnMsgID_813 : 325|1@0+ (1,0) [0|1] ""  MHU
 SG_ WarnMsgID_814 : 326|1@0+ (1,0) [0|1] ""  MHU
 SG_ WarnMsgID_815 : 327|1@0+ (1,0) [0|1] ""  MHU
 SG_ WarnMsgID_816 : 328|1@0+ (1,0) [0|1] ""  MHU
 SG_ WarnMsgID_817 : 329|1@0+ (1,0) [0|1] ""  MHU
 SG_ WarnMsgID_818 : 330|1@0+ (1,0) [0|1] ""  MHU
 SG_ WarnMsgID_819 : 331|1@0+ (1,0) [0|1] ""  MHU
 SG_ WarnMsgID_820 : 332|1@0+ (1,0) [0|1] ""  MHU
 SG_ WarnMsgID_821 : 333|1@0+ (1,0) [0|1] ""  MHU
 SG_ WarnMsgID_822 : 334|1@0+ (1,0) [0|1] ""  MHU
 SG_ WarnMsgID_823 : 335|1@0+ (1,0) [0|1] ""  MHU
 SG_ WarnMsgID_824 : 336|1@0+ (1,0) [0|1] ""  MHU
 SG_ WarnMsgID_825 : 337|1@0+ (1,0) [0|1] ""  MHU
 SG_ WarnMsgID_826 : 338|1@0+ (1,0) [0|1] ""  MHU
 SG_ WarnMsgID_827 : 339|1@0+ (1,0) [0|1] ""  MHU
 SG_ WarnMsgID_828 : 340|1@0+ (1,0) [0|1] ""  MHU
 SG_ WarnMsgID_829 : 341|1@0+ (1,0) [0|1] ""  MHU
 SG_ WarnMsgID_830 : 342|1@0+ (1,0) [0|1] ""  MHU
 SG_ WarnMsgID_831 : 343|1@0+ (1,0) [0|1] ""  MHU
 SG_ WarnMsgID_832 : 344|1@0+ (1,0) [0|1] ""  MHU
 SG_ WarnMsgID_833 : 345|1@0+ (1,0) [0|1] ""  MHU
 SG_ WarnMsgID_834 : 346|1@0+ (1,0) [0|1] ""  MHU
 SG_ WarnMsgID_835 : 347|1@0+ (1,0) [0|1] ""  MHU
 SG_ WarnMsgID_836 : 348|1@0+ (1,0) [0|1] ""  MHU
 SG_ WarnMsgID_837 : 349|1@0+ (1,0) [0|1] ""  MHU
 SG_ WarnMsgID_838 : 350|1@0+ (1,0) [0|1] ""  MHU
 SG_ WarnMsgID_839 : 351|1@0+ (1,0) [0|1] ""  MHU
 SG_ WarnMsgID_840 : 352|1@0+ (1,0) [0|1] ""  MHU
 SG_ WarnMsgID_841 : 353|1@0+ (1,0) [0|1] ""  MHU
 SG_ WarnMsgID_842 : 354|1@0+ (1,0) [0|1] ""  MHU
 SG_ WarnMsgID_843 : 355|1@0+ (1,0) [0|1] ""  MHU
 SG_ WarnMsgID_844 : 356|1@0+ (1,0) [0|1] ""  MHU
 SG_ WarnMsgID_845 : 357|1@0+ (1,0) [0|1] ""  MHU
 SG_ WarnMsgID_846 : 358|1@0+ (1,0) [0|1] ""  MHU
 SG_ WarnMsgID_847 : 359|1@0+ (1,0) [0|1] ""  MHU
 SG_ WarnMsgID_848 : 360|1@0+ (1,0) [0|1] ""  MHU
 SG_ WarnMsgID_849 : 361|1@0+ (1,0) [0|1] ""  MHU
 SG_ WarnMsgID_850 : 362|1@0+ (1,0) [0|1] ""  MHU
 SG_ WarnMsgID_851 : 363|1@0+ (1,0) [0|1] ""  MHU
 SG_ WarnMsgID_852 : 364|1@0+ (1,0) [0|1] ""  MHU
 SG_ WarnMsgID_853 : 365|1@0+ (1,0) [0|1] ""  MHU
 SG_ WarnMsgID_854 : 366|1@0+ (1,0) [0|1] ""  MHU
 SG_ WarnMsgID_855 : 367|1@0+ (1,0) [0|1] ""  MHU
 SG_ WarnMsgID_856 : 368|1@0+ (1,0) [0|1] ""  MHU
 SG_ WarnMsgID_857 : 369|1@0+ (1,0) [0|1] ""  MHU
 SG_ WarnMsgID_858 : 370|1@0+ (1,0) [0|1] ""  MHU
 SG_ WarnMsgID_859 : 371|1@0+ (1,0) [0|1] ""  MHU
 SG_ WarnMsgID_860 : 372|1@0+ (1,0) [0|1] ""  MHU
 SG_ WarnMsgID_861 : 373|1@0+ (1,0) [0|1] ""  MHU
 SG_ WarnMsgID_862 : 374|1@0+ (1,0) [0|1] ""  MHU
 SG_ WarnMsgID_863 : 375|1@0+ (1,0) [0|1] ""  MHU
 SG_ WarnMsgID_864 : 376|1@0+ (1,0) [0|1] ""  MHU
 SG_ WarnMsgID_865 : 377|1@0+ (1,0) [0|1] ""  MHU
 SG_ WarnMsgID_866 : 378|1@0+ (1,0) [0|1] ""  MHU
 SG_ WarnMsgID_867 : 379|1@0+ (1,0) [0|1] ""  MHU
 SG_ WarnMsgID_868 : 380|1@0+ (1,0) [0|1] ""  MHU
 SG_ WarnMsgID_869 : 381|1@0+ (1,0) [0|1] ""  MHU
 SG_ WarnMsgID_870 : 382|1@0+ (1,0) [0|1] ""  MHU
 SG_ WarnMsgID_871 : 383|1@0+ (1,0) [0|1] ""  MHU
 SG_ WarnMsgID_872 : 384|1@0+ (1,0) [0|1] ""  MHU
 SG_ WarnMsgID_873 : 385|1@0+ (1,0) [0|1] ""  MHU
 SG_ WarnMsgID_874 : 386|1@0+ (1,0) [0|1] ""  MHU
 SG_ WarnMsgID_875 : 387|1@0+ (1,0) [0|1] ""  MHU
 SG_ WarnMsgID_876 : 388|1@0+ (1,0) [0|1] ""  MHU
 SG_ WarnMsgID_877 : 389|1@0+ (1,0) [0|1] ""  MHU
 SG_ WarnMsgID_878 : 390|1@0+ (1,0) [0|1] ""  MHU
 SG_ WarnMsgID_879 : 391|1@0+ (1,0) [0|1] ""  MHU
 SG_ WarnMsgID_880 : 392|1@0+ (1,0) [0|1] ""  MHU
 SG_ WarnMsgID_881 : 393|1@0+ (1,0) [0|1] ""  MHU
 SG_ WarnMsgID_882 : 394|1@0+ (1,0) [0|1] ""  MHU
 SG_ WarnMsgID_883 : 395|1@0+ (1,0) [0|1] ""  MHU
 SG_ WarnMsgID_884 : 396|1@0+ (1,0) [0|1] ""  MHU
 SG_ WarnMsgID_885 : 397|1@0+ (1,0) [0|1] ""  MHU
 SG_ WarnMsgID_886 : 398|1@0+ (1,0) [0|1] ""  MHU
 SG_ WarnMsgID_887 : 399|1@0+ (1,0) [0|1] ""  MHU
 SG_ WarnMsgID_888 : 400|1@0+ (1,0) [0|1] ""  MHU
 SG_ WarnMsgID_889 : 401|1@0+ (1,0) [0|1] ""  MHU
 SG_ WarnMsgID_890 : 402|1@0+ (1,0) [0|1] ""  MHU
 SG_ WarnMsgID_891 : 403|1@0+ (1,0) [0|1] ""  MHU
 SG_ WarnMsgID_892 : 404|1@0+ (1,0) [0|1] ""  MHU
 SG_ WarnMsgID_893 : 405|1@0+ (1,0) [0|1] ""  MHU
 SG_ WarnMsgID_894 : 406|1@0+ (1,0) [0|1] ""  MHU
 SG_ WarnMsgID_895 : 407|1@0+ (1,0) [0|1] ""  MHU
 SG_ WarnMsgID_896 : 408|1@0+ (1,0) [0|1] ""  MHU
 SG_ WarnMsgID_897 : 409|1@0+ (1,0) [0|1] ""  MHU
 SG_ WarnMsgID_898 : 410|1@0+ (1,0) [0|1] ""  MHU
 SG_ WarnMsgID_899 : 411|1@0+ (1,0) [0|1] ""  MHU
 SG_ WarnMsgID_900 : 412|1@0+ (1,0) [0|1] ""  MHU
 SG_ WarnMsgID_901 : 413|1@0+ (1,0) [0|1] ""  MHU
 SG_ WarnMsgID_902 : 414|1@0+ (1,0) [0|1] ""  MHU
 SG_ WarnMsgID_903 : 415|1@0+ (1,0) [0|1] ""  MHU
 SG_ WarnMsgID_904 : 416|1@0+ (1,0) [0|1] ""  MHU
 SG_ WarnMsgID_905 : 417|1@0+ (1,0) [0|1] ""  MHU
 SG_ WarnMsgID_906 : 418|1@0+ (1,0) [0|1] ""  MHU
 SG_ WarnMsgID_907 : 419|1@0+ (1,0) [0|1] ""  MHU
 SG_ WarnMsgID_908 : 420|1@0+ (1,0) [0|1] ""  MHU
 SG_ WarnMsgID_909 : 421|1@0+ (1,0) [0|1] ""  MHU
 SG_ WarnMsgID_910 : 422|1@0+ (1,0) [0|1] ""  MHU
 SG_ WarnMsgID_911 : 423|1@0+ (1,0) [0|1] ""  MHU
 SG_ WarnMsgID_912 : 424|1@0+ (1,0) [0|1] ""  MHU
 SG_ WarnMsgID_913 : 425|1@0+ (1,0) [0|1] ""  MHU
 SG_ WarnMsgID_914 : 426|1@0+ (1,0) [0|1] ""  MHU
 SG_ WarnMsgID_915 : 427|1@0+ (1,0) [0|1] ""  MHU
 SG_ WarnMsgID_916 : 428|1@0+ (1,0) [0|1] ""  MHU
 SG_ WarnMsgID_917 : 429|1@0+ (1,0) [0|1] ""  MHU
 SG_ WarnMsgID_918 : 430|1@0+ (1,0) [0|1] ""  MHU
 SG_ WarnMsgID_919 : 431|1@0+ (1,0) [0|1] ""  MHU
 SG_ WarnMsgID_920 : 432|1@0+ (1,0) [0|1] ""  MHU
 SG_ WarnMsgID_921 : 433|1@0+ (1,0) [0|1] ""  MHU
 SG_ WarnMsgID_922 : 434|1@0+ (1,0) [0|1] ""  MHU
 SG_ WarnMsgID_923 : 435|1@0+ (1,0) [0|1] ""  MHU
 SG_ WarnMsgID_924 : 436|1@0+ (1,0) [0|1] ""  MHU
 SG_ WarnMsgID_925 : 437|1@0+ (1,0) [0|1] ""  MHU
 SG_ WarnMsgID_926 : 438|1@0+ (1,0) [0|1] ""  MHU
 SG_ WarnMsgID_927 : 439|1@0+ (1,0) [0|1] ""  MHU
 SG_ WarnMsgID_928 : 440|1@0+ (1,0) [0|1] ""  MHU
 SG_ WarnMsgID_929 : 441|1@0+ (1,0) [0|1] ""  MHU
 SG_ WarnMsgID_930 : 442|1@0+ (1,0) [0|1] ""  MHU
 SG_ WarnMsgID_931 : 443|1@0+ (1,0) [0|1] ""  MHU
 SG_ WarnMsgID_932 : 444|1@0+ (1,0) [0|1] ""  MHU
 SG_ WarnMsgID_933 : 445|1@0+ (1,0) [0|1] ""  MHU
 SG_ WarnMsgID_934 : 446|1@0+ (1,0) [0|1] ""  MHU
 SG_ WarnMsgID_935 : 447|1@0+ (1,0) [0|1] ""  MHU
 SG_ WarnMsgID_936 : 448|1@0+ (1,0) [0|1] ""  MHU
 SG_ WarnMsgID_937 : 449|1@0+ (1,0) [0|1] ""  MHU
 SG_ WarnMsgID_938 : 450|1@0+ (1,0) [0|1] ""  MHU
 SG_ WarnMsgID_939 : 451|1@0+ (1,0) [0|1] ""  MHU
 SG_ WarnMsgID_940 : 452|1@0+ (1,0) [0|1] ""  MHU
 SG_ WarnMsgID_941 : 453|1@0+ (1,0) [0|1] ""  MHU
 SG_ WarnMsgID_942 : 454|1@0+ (1,0) [0|1] ""  MHU
 SG_ WarnMsgID_943 : 455|1@0+ (1,0) [0|1] ""  MHU
 SG_ WarnMsgID_944 : 456|1@0+ (1,0) [0|1] ""  MHU
 SG_ WarnMsgID_945 : 457|1@0+ (1,0) [0|1] ""  MHU
 SG_ WarnMsgID_946 : 458|1@0+ (1,0) [0|1] ""  MHU
 SG_ WarnMsgID_947 : 459|1@0+ (1,0) [0|1] ""  MHU
 SG_ WarnMsgID_948 : 460|1@0+ (1,0) [0|1] ""  MHU
 SG_ WarnMsgID_949 : 461|1@0+ (1,0) [0|1] ""  MHU
 SG_ WarnMsgID_950 : 462|1@0+ (1,0) [0|1] ""  MHU
 SG_ WarnMsgID_951 : 463|1@0+ (1,0) [0|1] ""  MHU
 SG_ WarnMsgID_952 : 464|1@0+ (1,0) [0|1] ""  MHU
 SG_ WarnMsgID_953 : 465|1@0+ (1,0) [0|1] ""  MHU
 SG_ WarnMsgID_954 : 466|1@0+ (1,0) [0|1] ""  MHU
 SG_ WarnMsgID_955 : 467|1@0+ (1,0) [0|1] ""  MHU
 SG_ WarnMsgID_956 : 468|1@0+ (1,0) [0|1] ""  MHU
 SG_ WarnMsgID_957 : 469|1@0+ (1,0) [0|1] ""  MHU
 SG_ WarnMsgID_958 : 470|1@0+ (1,0) [0|1] ""  MHU
 SG_ WarnMsgID_959 : 471|1@0+ (1,0) [0|1] ""  MHU
 SG_ WarnMsgID_960 : 472|1@0+ (1,0) [0|1] ""  MHU
 SG_ WarnMsgID_961 : 473|1@0+ (1,0) [0|1] ""  MHU
 SG_ WarnMsgID_962 : 474|1@0+ (1,0) [0|1] ""  MHU
 SG_ WarnMsgID_963 : 475|1@0+ (1,0) [0|1] ""  MHU
 SG_ WarnMsgID_964 : 476|1@0+ (1,0) [0|1] ""  MHU
 SG_ WarnMsgID_965 : 477|1@0+ (1,0) [0|1] ""  MHU
 SG_ WarnMsgID_966 : 478|1@0+ (1,0) [0|1] ""  MHU
 SG_ WarnMsgID_967 : 479|1@0+ (1,0) [0|1] ""  MHU
 SG_ WarnMsgID_968 : 480|1@0+ (1,0) [0|1] ""  MHU
 SG_ WarnMsgID_969 : 481|1@0+ (1,0) [0|1] ""  MHU
 SG_ WarnMsgID_970 : 482|1@0+ (1,0) [0|1] ""  MHU
 SG_ WarnMsgID_971 : 483|1@0+ (1,0) [0|1] ""  MHU
 SG_ WarnMsgID_972 : 484|1@0+ (1,0) [0|1] ""  MHU
 SG_ WarnMsgID_973 : 485|1@0+ (1,0) [0|1] ""  MHU
 SG_ WarnMsgID_974 : 486|1@0+ (1,0) [0|1] ""  MHU
 SG_ WarnMsgID_975 : 487|1@0+ (1,0) [0|1] ""  MHU
 SG_ WarnMsgID_976 : 488|1@0+ (1,0) [0|1] ""  MHU
 SG_ WarnMsgID_977 : 489|1@0+ (1,0) [0|1] ""  MHU
 SG_ WarnMsgID_978 : 490|1@0+ (1,0) [0|1] ""  MHU
 SG_ WarnMsgID_979 : 491|1@0+ (1,0) [0|1] ""  MHU
 SG_ WarnMsgID_980 : 492|1@0+ (1,0) [0|1] ""  MHU
 SG_ WarnMsgID_981 : 493|1@0+ (1,0) [0|1] ""  MHU
 SG_ WarnMsgID_982 : 494|1@0+ (1,0) [0|1] ""  MHU
 SG_ WarnMsgID_983 : 495|1@0+ (1,0) [0|1] ""  MHU
 SG_ WarnMsgID_984 : 496|1@0+ (1,0) [0|1] ""  MHU
 SG_ WarnMsgID_985 : 497|1@0+ (1,0) [0|1] ""  MHU
 SG_ WarnMsgID_986 : 498|1@0+ (1,0) [0|1] ""  MHU
 SG_ WarnMsgID_987 : 499|1@0+ (1,0) [0|1] ""  MHU
 SG_ WarnMsgID_988 : 500|1@0+ (1,0) [0|1] ""  MHU
 SG_ WarnMsgID_989 : 501|1@0+ (1,0) [0|1] ""  MHU
 SG_ WarnMsgID_990 : 502|1@0+ (1,0) [0|1] ""  MHU
 SG_ WarnMsgID_991 : 503|1@0+ (1,0) [0|1] ""  MHU
 SG_ WarnMsgID_992 : 504|1@0+ (1,0) [0|1] ""  MHU
 SG_ WarnMsgID_993 : 505|1@0+ (1,0) [0|1] ""  MHU
 SG_ WarnMsgID_994 : 506|1@0+ (1,0) [0|1] ""  MHU
 SG_ WarnMsgID_995 : 507|1@0+ (1,0) [0|1] ""  MHU
 SG_ WarnMsgID_996 : 508|1@0+ (1,0) [0|1] ""  MHU
 SG_ WarnMsgID_997 : 509|1@0+ (1,0) [0|1] ""  MHU
 SG_ WarnMsgID_998 : 510|1@0+ (1,0) [0|1] ""  MHU
 SG_ WarnMsgID_999 : 511|1@0+ (1,0) [0|1] ""  MHU

BO_ 1088 AMP_MHUEQ: 8 AMP
 SG_ AMP_Sts_EQ_1000HZ : 7|5@0+ (1,0) [0|24] ""  MHU
 SG_ AMP_Sts_EQ_16000HZ : 15|5@0+ (1,0) [0|24] ""  MHU
 SG_ AMP_Sts_EQ_250HZ : 23|5@0+ (1,0) [0|24] ""  MHU
 SG_ AMP_Sts_EQ_4000HZ : 31|5@0+ (1,0) [0|24] ""  MHU
 SG_ AMP_Sts_EQ_60HZ : 39|5@0+ (1,0) [0|24] ""  MHU
 SG_ AMP_Sts_EQType : 47|4@0+ (1,0) [0|15] ""  MHU

BO_ 1882 AMP_Debug1: 8 AMP
 SG_ DSP_RUN_STATUS : 1|2@0+ (1,0) [0|3] ""  DUMMY_ECU
 SG_ SYS_RUN_STATUS : 3|2@0+ (1,0) [0|3] ""  DUMMY_ECU
 SG_ A2B_RUN_STATUS : 5|2@0+ (1,0) [0|3] ""  DUMMY_ECU
 SG_ POWERIC_STATUS : 7|2@0+ (1,0) [0|3] ""  DUMMY_ECU
 SG_ CHANNEL1_DAIG_STATUS : 9|2@0+ (1,0) [0|3] ""  DUMMY_ECU
 SG_ CHANNEL2_DAIG_STATUS : 11|2@0+ (1,0) [0|3] ""  DUMMY_ECU
 SG_ CHANNEL3_DAIG_STATUS : 13|2@0+ (1,0) [0|3] ""  DUMMY_ECU
 SG_ CHANNEL4_DAIG_STATUS : 15|2@0+ (1,0) [0|3] ""  DUMMY_ECU
 SG_ CHANNEL5_DAIG_STATUS : 17|2@0+ (1,0) [0|3] ""  DUMMY_ECU
 SG_ CHANNEL6_DAIG_STATUS : 19|2@0+ (1,0) [0|3] ""  DUMMY_ECU
 SG_ CHANNEL7_DAIG_STATUS : 21|2@0+ (1,0) [0|3] ""  DUMMY_ECU
 SG_ CHANNEL8_DAIG_STATUS : 23|2@0+ (1,0) [0|3] ""  DUMMY_ECU
 SG_ CHANNEL9_DAIG_STATUS : 25|2@0+ (1,0) [0|3] ""  DUMMY_ECU
 SG_ CHANNEL10_DAIG_STATUS : 27|2@0+ (1,0) [0|3] ""  DUMMY_ECU
 SG_ CHANNEL11_DAIG_STATUS : 29|2@0+ (1,0) [0|3] ""  DUMMY_ECU
 SG_ CHANNEL12_DAIG_STATUS : 31|2@0+ (1,0) [0|3] ""  DUMMY_ECU
 SG_ CHANNEL13_DAIG_STATUS : 33|2@0+ (1,0) [0|3] ""  DUMMY_ECU
 SG_ CHANNEL14_DAIG_STATUS : 35|2@0+ (1,0) [0|3] ""  DUMMY_ECU
 SG_ CHANNEL15_DAIG_STATUS : 37|2@0+ (1,0) [0|3] ""  DUMMY_ECU
 SG_ CHANNEL16_DAIG_STATUS : 39|2@0+ (1,0) [0|3] ""  DUMMY_ECU

BO_ 1136 AMP_MHU_A2B_Slots_Sts: 8 AMP
 SG_ Slot0_Ready_Sts : 23|2@0+ (1,0) [0|3] ""  MHU
 SG_ Slot0_Data_Available_Sts : 21|1@0+ (1,0) [0|1] ""  MHU
 SG_ Slot1_Ready_Sts : 20|2@0+ (1,0) [0|3] ""  MHU
 SG_ Slot1_Data_Available_Sts : 18|1@0+ (1,0) [0|1] ""  MHU
 SG_ Slot2_Ready_Sts : 17|2@0+ (1,0) [0|3] ""  MHU
 SG_ Slot2_Data_Available_Sts : 31|1@0+ (1,0) [0|1] ""  MHU
 SG_ Slot3_Ready_Sts : 30|2@0+ (1,0) [0|3] ""  MHU
 SG_ Slot3_Data_Available_Sts : 28|1@0+ (1,0) [0|1] ""  MHU
 SG_ Slot4_Ready_Sts : 27|2@0+ (1,0) [0|3] ""  MHU
 SG_ Slot4_Data_Available_Sts : 25|1@0+ (1,0) [0|1] ""  MHU
 SG_ Slot5_Ready_Sts : 24|2@0+ (1,0) [0|3] ""  MHU
 SG_ Slot5_Data_Available_Sts : 38|1@0+ (1,0) [0|1] ""  MHU
 SG_ Slot6_Ready_Sts : 37|2@0+ (1,0) [0|3] ""  MHU
 SG_ Slot6_Data_Available_Sts : 35|1@0+ (1,0) [0|1] ""  MHU
 SG_ Slot7_Ready_Sts : 34|2@0+ (1,0) [0|3] ""  MHU
 SG_ Slot7_Data_Available_Sts : 32|1@0+ (1,0) [0|1] ""  MHU
 SG_ Slot8_Ready_Sts : 47|2@0+ (1,0) [0|3] ""  MHU
 SG_ Slot8_Data_Available_Sts : 45|1@0+ (1,0) [0|1] ""  MHU
 SG_ Slot9_Ready_Sts : 44|2@0+ (1,0) [0|3] ""  MHU
 SG_ Slot9_Data_Available_Sts : 42|1@0+ (1,0) [0|1] ""  MHU
 SG_ Slot10_Ready_Sts : 41|2@0+ (1,0) [0|3] ""  MHU
 SG_ Slot10_Data_Available_Sts : 55|1@0+ (1,0) [0|1] ""  MHU
 SG_ Slot11_Ready_Sts : 54|2@0+ (1,0) [0|3] ""  MHU
 SG_ Slot11_Data_Available_Sts : 52|1@0+ (1,0) [0|1] ""  MHU
 SG_ Slot12_Ready_Sts : 51|2@0+ (1,0) [0|3] ""  MHU
 SG_ Slot12_Data_Available_Sts : 49|1@0+ (1,0) [0|1] ""  MHU
 SG_ Slot13_Ready_Sts : 48|2@0+ (1,0) [0|3] ""  MHU
 SG_ Slot13_Data_Available_Sts : 62|1@0+ (1,0) [0|1] ""  MHU
 SG_ Slot14_Ready_Sts : 61|2@0+ (1,0) [0|3] ""  MHU
 SG_ Slot14_Data_Available_Sts : 59|1@0+ (1,0) [0|1] ""  MHU
 SG_ Slot15_Ready_Sts : 58|2@0+ (1,0) [0|3] ""  MHU
 SG_ Slot15_Data_Available_Sts : 56|1@0+ (1,0) [0|1] ""  MHU
 SG_ Slot16_Ready_Sts : 7|2@0+ (1,0) [0|3] ""  MHU
 SG_ Slot16_Data_Available_Sts : 5|1@0+ (1,0) [0|1] ""  MHU
 SG_ Slot17_Ready_Sts : 2|2@0+ (1,0) [0|3] ""  MHU
 SG_ Slot17_Data_Available_Sts : 0|1@0+ (1,0) [0|1] ""  MHU
 SG_ Slot18_Ready_Sts : 15|2@0+ (1,0) [0|3] ""  MHU
 SG_ Slot18_Data_Available_Sts : 13|1@0+ (1,0) [0|1] ""  MHU
 SG_ A2B_Initialization_Sts : 4|2@0+ (1,0) [0|3] ""  MHU

BO_ 1141 MHU_AMP_A2B_Slots: 8 MHU
 SG_ Slot0_Ready : 23|2@0+ (1,0) [0|3] ""  AMP
 SG_ Slot0_Data_Available : 21|1@0+ (1,0) [0|1] ""  AMP
 SG_ Slot1_Ready : 20|2@0+ (1,0) [0|3] ""  AMP
 SG_ Slot1_Data_Available : 18|1@0+ (1,0) [0|1] ""  AMP
 SG_ Slot2_Ready : 17|2@0+ (1,0) [0|3] ""  AMP
 SG_ Slot2_Data_Available : 31|1@0+ (1,0) [0|1] ""  AMP
 SG_ Slot3_Ready : 30|2@0+ (1,0) [0|3] ""  AMP
 SG_ Slot3_Data_Available : 28|1@0+ (1,0) [0|1] ""  AMP
 SG_ Slot4_Ready : 27|2@0+ (1,0) [0|3] ""  AMP
 SG_ Slot4_Data_Available : 25|1@0+ (1,0) [0|1] ""  AMP
 SG_ Slot5_Ready : 24|2@0+ (1,0) [0|3] ""  AMP
 SG_ Slot5_Data_Available : 38|1@0+ (1,0) [0|1] ""  AMP
 SG_ Slot6_Ready : 37|2@0+ (1,0) [0|3] ""  AMP
 SG_ Slot6_Data_Available : 35|1@0+ (1,0) [0|1] ""  AMP
 SG_ Slot7_Ready : 34|2@0+ (1,0) [0|3] ""  AMP
 SG_ Slot7_Data_Available : 32|1@0+ (1,0) [0|1] ""  AMP
 SG_ Slot8_Ready : 47|2@0+ (1,0) [0|3] ""  AMP
 SG_ Slot8_Data_Available : 45|1@0+ (1,0) [0|1] ""  AMP
 SG_ Slot9_Ready : 44|2@0+ (1,0) [0|3] ""  AMP
 SG_ Slot9_Data_Available : 42|1@0+ (1,0) [0|1] ""  AMP
 SG_ Slot10_Ready : 41|2@0+ (1,0) [0|3] ""  AMP
 SG_ Slot10_Data_Available : 55|1@0+ (1,0) [0|1] ""  AMP
 SG_ Slot11_Ready : 54|2@0+ (1,0) [0|3] ""  AMP
 SG_ Slot11_Data_Available : 52|1@0+ (1,0) [0|1] ""  AMP
 SG_ Slot12_Ready : 51|2@0+ (1,0) [0|3] ""  AMP
 SG_ Slot12_Data_Available : 49|1@0+ (1,0) [0|1] ""  AMP
 SG_ Slot13_Ready : 48|2@0+ (1,0) [0|3] ""  AMP
 SG_ Slot13_Data_Available : 62|1@0+ (1,0) [0|1] ""  AMP
 SG_ Slot14_Ready : 61|2@0+ (1,0) [0|3] ""  AMP
 SG_ Slot14_Data_Available : 59|1@0+ (1,0) [0|1] ""  AMP
 SG_ Slot15_Ready : 58|2@0+ (1,0) [0|3] ""  AMP
 SG_ Slot15_Data_Available : 56|1@0+ (1,0) [0|1] ""  AMP
 SG_ Slot16_Ready : 7|2@0+ (1,0) [0|3] ""  AMP
 SG_ Slot16_Data_Available : 5|1@0+ (1,0) [0|1] ""  AMP
 SG_ Slot17_Ready : 2|2@0+ (1,0) [0|3] ""  AMP
 SG_ Slot17_Data_Available : 0|1@0+ (1,0) [0|1] ""  AMP
 SG_ Slot18_Ready : 15|2@0+ (1,0) [0|3] ""  AMP
 SG_ Slot18_Data_Available : 13|1@0+ (1,0) [0|1] ""  AMP
 SG_ A2B_Initialization : 4|2@0+ (1,0) [0|3] ""  AMP

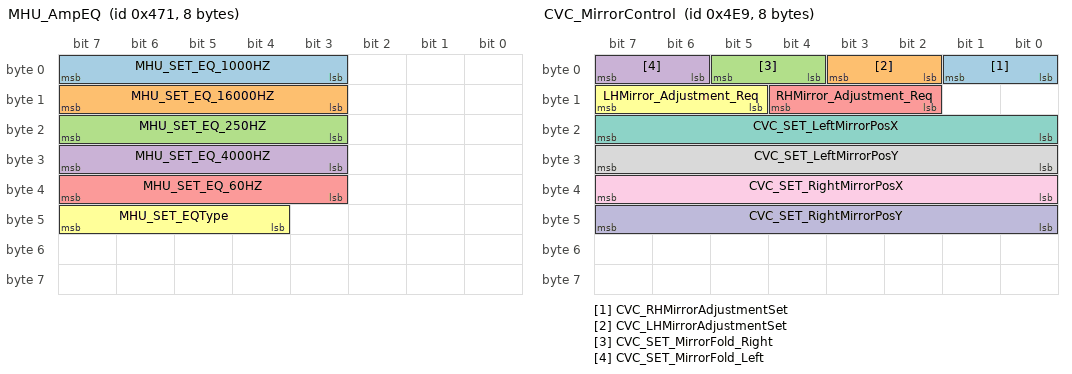
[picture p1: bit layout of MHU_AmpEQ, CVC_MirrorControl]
BO_ 1137 MHU_AmpEQ: 8 MHU
 SG_ MHU_SET_EQ_1000HZ : 7|5@0+ (1,0) [0|24] ""  AMP
 SG_ MHU_SET_EQ_16000HZ : 15|5@0+ (1,0) [0|24] ""  AMP
 SG_ MHU_SET_EQ_250HZ : 23|5@0+ (1,0) [0|24] ""  AMP
 SG_ MHU_SET_EQ_4000HZ : 31|5@0+ (1,0) [0|24] ""  AMP
 SG_ MHU_SET_EQ_60HZ : 39|5@0+ (1,0) [0|24] ""  AMP
 SG_ MHU_SET_EQType : 47|4@0+ (1,0) [0|6] ""  AMP

BO_ 1109 MHU_AMP_SET: 12 MHU
 SG_ Audio_Zone : 23|3@0+ (1,0) [0|3] ""  AMP
 SG_ VehicleSpeedAdjustment_Sensitivi : 20|3@0+ (1,0) [0|3] ""  AMP
 SG_ Preset_Value : 17|2@0+ (1,0) [0|2] ""  AMP
 SG_ Immersive_Level : 31|2@0+ (1,0) [0|3] ""  AMP
 SG_ Media_Volume : 29|6@0+ (1,0) [0|40] ""  AMP
 SG_ TEL_Volume : 39|6@0+ (1,0) [0|40] ""  AMP
 SG_ Warning_Volume : 33|6@0+ (1,0) [0|40] ""  AMP
 SG_ Navigation_Volume : 43|6@0+ (1,0) [0|40] ""  AMP
 SG_ VA_Volume : 53|6@0+ (1,0) [0|40] ""  AMP
 SG_ Notification_Volume : 71|6@0+ (1,0) [0|40] ""  AMP
 SG_ Ringtone_Volume : 79|6@0+ (1,0) [0|40] ""  AMP
 SG_ Media_Mute : 63|1@0+ (1,0) [0|1] ""  AMP
 SG_ TEL_Mute : 62|1@0+ (1,0) [0|1] ""  AMP
 SG_ Warning_Mute : 61|1@0+ (1,0) [0|1] ""  AMP
 SG_ Navigation_Mute : 60|1@0+ (1,0) [0|1] ""  AMP
 SG_ VA_Mute : 59|1@0+ (1,0) [0|1] ""  AMP
 SG_ Notification_Mute : 65|1@0+ (1,0) [0|1] ""  AMP
 SG_ Ringtone_Mute : 73|1@0+ (1,0) [0|1] ""  AMP
 SG_ Global_Mute : 58|1@0+ (1,0) [0|1] ""  AMP
 SG_ Directional_Warning_Mute_FL : 57|1@0+ (1,0) [0|1] ""  AMP
 SG_ Directional_Warning_Mute_FR : 56|1@0+ (1,0) [0|1] ""  AMP
 SG_ Directional_Warning_Mute_RL : 15|1@0+ (1,0) [0|1] ""  AMP
 SG_ Directional_Warning_Mute_RR : 14|1@0+ (1,0) [0|1] ""  AMP
 SG_ Directional_Warning_Mute_Center : 13|1@0+ (1,0) [0|1] ""  AMP

BO_ 1138 AMP_MHU_SET_STS: 12 AMP
 SG_ Audio_Zone_Sts : 23|3@0+ (1,0) [0|3] ""  MHU
 SG_ VehicleSpeedAdjustment_Sens_0000 : 20|3@0+ (1,0) [0|3] ""  MHU
 SG_ Preset_Value_Sts : 17|2@0+ (1,0) [0|2] ""  MHU
 SG_ Immersive_Level_Sts : 31|2@0+ (1,0) [0|3] ""  MHU
 SG_ Media_Volume_Sts : 29|6@0+ (1,0) [0|40] ""  MHU
 SG_ TEL_Volume_Sts : 39|6@0+ (1,0) [0|40] ""  MHU
 SG_ Warning_Volume_Sts : 33|6@0+ (1,0) [0|40] ""  MHU
 SG_ Navigation_Volume_Sts : 43|6@0+ (1,0) [0|40] ""  MHU
 SG_ VA_Volume_Sts : 53|6@0+ (1,0) [0|40] ""  MHU
 SG_ Notification_Volume_Sts : 71|6@0+ (1,0) [0|40] ""  MHU
 SG_ Ringtone_Volume_Sts : 79|6@0+ (1,0) [0|40] ""  MHU
 SG_ Media_Mute_Sts : 63|1@0+ (1,0) [0|1] ""  MHU
 SG_ TEL_Mute_Sts : 62|1@0+ (1,0) [0|1] ""  MHU
 SG_ Warning_Mute_Sts : 61|1@0+ (1,0) [0|1] ""  MHU
 SG_ Navigation_Mute_Sts : 60|1@0+ (1,0) [0|1] ""  MHU
 SG_ VA_Mute_Sts : 59|1@0+ (1,0) [0|1] ""  MHU
 SG_ Notification_Mute_Sts : 65|1@0+ (1,0) [0|1] ""  MHU
 SG_ Ringtone_Mute_Sts : 73|1@0+ (1,0) [0|1] ""  MHU
 SG_ Global_Mute_Sts : 58|1@0+ (1,0) [0|1] ""  MHU
 SG_ Directional_Warning_Mute_FL_Sts : 57|1@0+ (1,0) [0|1] ""  MHU
 SG_ Directional_Warning_Mute_FR_Sts : 56|1@0+ (1,0) [0|1] ""  MHU
 SG_ Directional_Warning_Mute_RL_Sts : 15|1@0+ (1,0) [0|1] ""  MHU
 SG_ Directional_Warning_Mute_RR_Sts : 14|1@0+ (1,0) [0|1] ""  MHU
 SG_ Directional_Warning_Mute_Center_ : 13|1@0+ (1,0) [0|1] ""  MHU

BO_ 1257 CVC_MirrorControl: 8 CVC_I
 SG_ CVC_RHMirrorAdjustmentSet : 1|2@0+ (1,0) [0|3] ""  MHU,ADCU_I
 SG_ CVC_LHMirrorAdjustmentSet : 3|2@0+ (1,0) [0|3] ""  MHU,ADCU_I
 SG_ CVC_SET_MirrorFold_Right : 5|2@0+ (1,0) [0|3] ""  MHU,ADCU_I
 SG_ CVC_SET_MirrorFold_Left : 7|2@0+ (1,0) [0|3] ""  MHU,ADCU_I
 SG_ RHMirror_Adjustment_Req : 12|3@0+ (1,0) [0|5] ""  MHU,ADCU_I
 SG_ LHMirror_Adjustment_Req : 15|3@0+ (1,0) [0|5] ""  MHU,ADCU_I
 SG_ CVC_SET_LeftMirrorPosX : 23|8@0+ (1,-15) [-15|15] "deg"  MHU,ADCU_I
 SG_ CVC_SET_LeftMirrorPosY : 31|8@0+ (1,-15) [-15|15] "deg"  MHU,ADCU_I
 SG_ CVC_SET_RightMirrorPosX : 39|8@0+ (1,-15) [-15|15] "deg"  MHU,ADCU_I
 SG_ CVC_SET_RightMirrorPosY : 47|8@0+ (1,-15) [-15|15] "deg"  MHU,ADCU_I

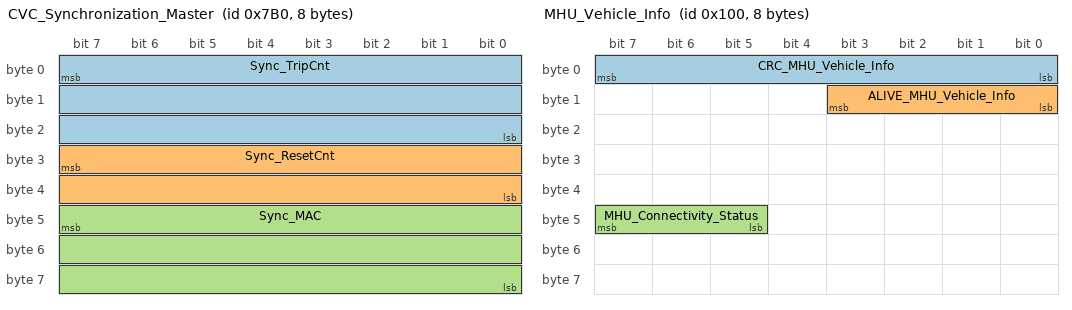
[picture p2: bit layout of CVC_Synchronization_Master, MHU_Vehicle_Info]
BO_ 1968 CVC_Synchronization_Master: 8 CVC_I
 SG_ Sync_TripCnt : 7|24@0+ (1,0) [0|16777215] ""  MHU
 SG_ Sync_ResetCnt : 31|16@0+ (1,0) [0|65535] ""  MHU
 SG_ Sync_MAC : 47|24@0+ (1,0) [0|16777215] ""  MHU

BO_ 256 MHU_Vehicle_Info: 8 MHU
 SG_ CRC_MHU_Vehicle_Info : 7|8@0+ (1,0) [0|255] ""  FCAM_I,ADCU_I
 SG_ ALIVE_MHU_Vehicle_Info : 11|4@0+ (1,0) [0|15] ""  FCAM_I,ADCU_I
 SG_ MHU_Connectivity_Status : 47|3@0+ (1,0) [0|7] ""  FCAM_I,ADCU_I

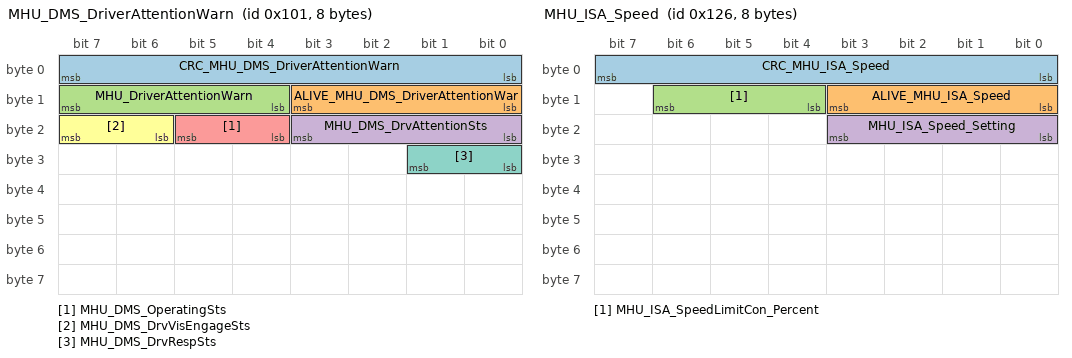
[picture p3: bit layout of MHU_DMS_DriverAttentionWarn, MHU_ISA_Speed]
BO_ 257 MHU_DMS_DriverAttentionWarn: 8 MHU
 SG_ CRC_MHU_DMS_DriverAttentionWarn : 7|8@0+ (1,0) [0|255] ""  CVC_I,FCAM_I,ADCU_I
 SG_ ALIVE_MHU_DMS_DriverAttentionWar : 11|4@0+ (1,0) [0|15] ""  CVC_I,FCAM_I,ADCU_I
 SG_ MHU_DriverAttentionWarn : 15|4@0+ (1,0) [0|15] ""  CVC_I,FCAM_I,ADCU_I
 SG_ MHU_DMS_DrvAttentionSts : 19|4@0+ (1,0) [0|8] ""  CVC_I,FCAM_I,ADCU_I
 SG_ MHU_DMS_OperatingSts : 21|2@0+ (1,0) [0|3] ""  CVC_I,FCAM_I,ADCU_I
 SG_ MHU_DMS_DrvVisEngageSts : 23|2@0+ (1,0) [0|3] ""  CVC_I,FCAM_I,ADCU_I
 SG_ MHU_DMS_DrvRespSts : 25|2@0+ (1,0) [0|3] ""  CVC_I,FCAM_I,ADCU_I

BO_ 284 FOTAClampCtrl: 8 MHU
 SG_ TBOX_FOTA_STAT_TerminalReq : 7|3@0+ (1,0) [0|7] ""  CVC_I

BO_ 294 MHU_ISA_Speed: 8 MHU
 SG_ CRC_MHU_ISA_Speed : 7|8@0+ (1,0) [0|255] ""  FCAM_I,ADCU_I
 SG_ ALIVE_MHU_ISA_Speed : 11|4@0+ (1,0) [0|15] ""  FCAM_I,ADCU_I
 SG_ MHU_ISA_SpeedLimitCon_Percent : 14|3@0+ (1,0) [0|7] ""  FCAM_I,ADCU_I
 SG_ MHU_ISA_Speed_Setting : 19|4@0+ (1,0) [0|15] ""  FCAM_I,ADCU_I

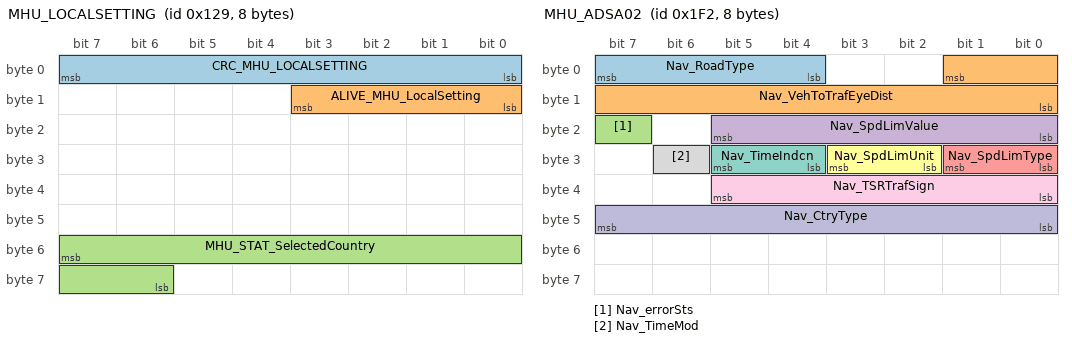
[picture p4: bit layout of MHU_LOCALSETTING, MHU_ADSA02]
BO_ 297 MHU_LOCALSETTING: 8 MHU
 SG_ CRC_MHU_LOCALSETTING : 7|8@0+ (1,0) [0|255] ""  CVC_I,FCAM_I,ADCU_I
 SG_ ALIVE_MHU_LocalSetting : 11|4@0+ (1,0) [0|15] ""  CVC_I,FCAM_I,ADCU_I
 SG_ MHU_STAT_SelectedCountry : 55|10@0+ (1,0) [0|1023] ""  CVC_I,FCAM_I,ADCU_I

BO_ 498 MHU_ADSA02: 8 MHU
 SG_ Nav_RoadType : 7|4@0+ (1,0) [0|15] ""  FCAM_I,MRR,SRR_RL,SRR_RR,ADCU_I
 SG_ Nav_VehToTrafEyeDist : 1|10@0+ (1,0) [0|1000] "m"  FCAM_I,MRR,SRR_RL,SRR_RR,ADCU_I
 SG_ Nav_errorSts : 23|1@0+ (1,0) [0|1] ""  FCAM_I,MRR,SRR_RL,SRR_RR,ADCU_I
 SG_ Nav_SpdLimValue : 21|6@0+ (1,0) [0|63] ""  FCAM_I,MRR,SRR_RL,SRR_RR,ADCU_I
 SG_ Nav_SpdLimType : 25|2@0+ (1,0) [0|3] ""  FCAM_I,MRR,SRR_RL,SRR_RR,ADCU_I
 SG_ Nav_SpdLimUnit : 27|2@0+ (1,0) [0|3] ""  FCAM_I,MRR,SRR_RL,SRR_RR,ADCU_I
 SG_ Nav_TimeIndcn : 29|2@0+ (1,0) [0|3] ""  FCAM_I,MRR,SRR_RL,SRR_RR,ADCU_I
 SG_ Nav_TimeMod : 30|1@0+ (1,0) [0|1] ""  FCAM_I,MRR,SRR_RL,SRR_RR,ADCU_I
 SG_ Nav_TSRTrafSign : 37|6@0+ (1,0) [0|63] ""  FCAM_I,MRR,SRR_RL,SRR_RR,ADCU_I
 SG_ Nav_CtryType : 47|8@0+ (1,0) [0|255] ""  FCAM_I,MRR,SRR_RL,SRR_RR,ADCU_I

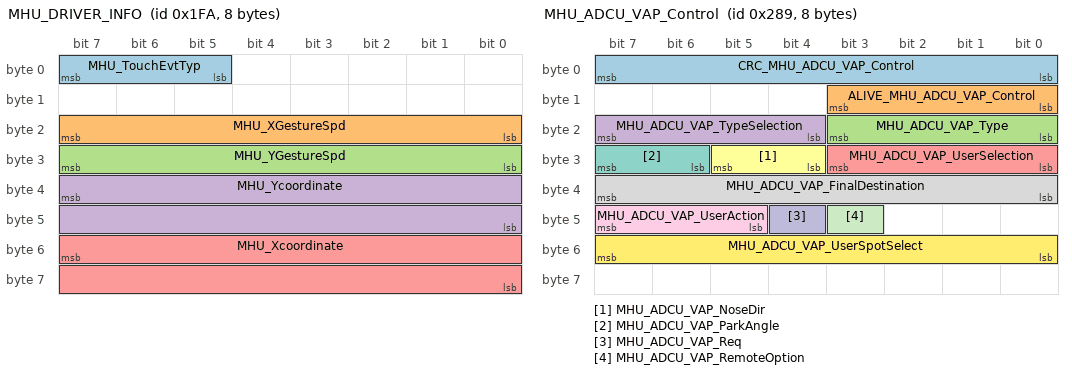
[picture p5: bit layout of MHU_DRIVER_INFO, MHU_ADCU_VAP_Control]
BO_ 506 MHU_DRIVER_INFO: 8 MHU
 SG_ MHU_TouchEvtTyp : 7|3@0+ (1,0) [0|7] ""  CVC_I,ADCU_I
 SG_ MHU_XGestureSpd : 23|8@0+ (1,0) [0|255] ""  CVC_I,ADCU_I
 SG_ MHU_YGestureSpd : 31|8@0+ (1,0) [0|255] ""  CVC_I,ADCU_I
 SG_ MHU_Ycoordinate : 39|16@0+ (1,0) [0|65535] ""  CVC_I,ADCU_I
 SG_ MHU_Xcoordinate : 55|16@0+ (1,0) [0|65535] ""  CVC_I,ADCU_I

BO_ 649 MHU_ADCU_VAP_Control: 8 MHU
 SG_ CRC_MHU_ADCU_VAP_Control : 7|8@0+ (1,0) [0|255] ""  ADCU_I
 SG_ ALIVE_MHU_ADCU_VAP_Control : 11|4@0+ (1,0) [0|15] ""  ADCU_I
 SG_ MHU_ADCU_VAP_Type : 19|4@0+ (1,0) [0|15] ""  ADCU_I
 SG_ MHU_ADCU_VAP_TypeSelection : 23|4@0+ (1,0) [0|15] ""  ADCU_I
 SG_ MHU_ADCU_VAP_UserSelection : 27|4@0+ (1,0) [0|15] ""  ADCU_I
 SG_ MHU_ADCU_VAP_NoseDir : 29|2@0+ (1,0) [0|3] ""  ADCU_I
 SG_ MHU_ADCU_VAP_ParkAngle : 31|2@0+ (1,0) [0|3] ""  ADCU_I
 SG_ MHU_ADCU_VAP_FinalDestination : 39|8@0+ (0.5,0) [0|100] "%"  ADCU_I
 SG_ MHU_ADCU_VAP_UserAction : 47|3@0+ (1,0) [0|7] ""  ADCU_I
 SG_ MHU_ADCU_VAP_Req : 44|1@0+ (1,0) [0|1] ""  ADCU_I
 SG_ MHU_ADCU_VAP_RemoteOption : 43|1@0+ (1,0) [0|1] ""  ADCU_I
 SG_ MHU_ADCU_VAP_UserSpotSelect : 55|8@0+ (1,0) [0|255] ""  ADCU_I

CM_ SG_ 1178 CRC_RMCU_WarnMsg "Checksum";
CM_ SG_ 1178 ALIVE_RMCU_WarnMsg "Alive Counter";
CM_ SG_ 1178 RMCU_Warning_Flag_1 "Warning Message Flag, Component owner, Supplier align and define for this signal";
CM_ SG_ 1178 RMCU_Warning_Flag_2 "Warning Message Flag, Component owner, Supplier align and define for this signal";
CM_ SG_ 1178 RMCU_Warning_Flag_3 "Warning Message Flag, Component owner, Supplier align and define for this signal";
CM_ SG_ 1178 RMCU_Warning_Flag_4 "Warning Message Flag, Component owner, Supplier align and define for this signal";
CM_ SG_ 1178 RMCU_Warning_Flag_5 "Warning Message Flag, Component owner, Supplier align and define for this signal";
CM_ SG_ 1178 RMCU_Warning_Flag_6 "Warning Message Flag, Component owner, Supplier align and define for this signal";
CM_ SG_ 1178 RMCU_Warning_Flag_7 "Warning Message Flag, Component owner, Supplier align and define for this signal";
CM_ SG_ 1178 RMCU_Warning_Flag_8 "Warning Message Flag, Component owner, Supplier align and define for this signal";
CM_ SG_ 1178 RMCU_Warning_Flag_9 "Warning Message Flag, Component owner, Supplier align and define for this signal";
CM_ SG_ 1178 RMCU_Warning_Flag_10 "Warning Message Flag, Component owner, Supplier align and define for this signal";
CM_ SG_ 1178 RMCU_Warning_Flag_11 "Warning Message Flag, Component owner, Supplier align and define for this signal";
CM_ SG_ 1178 RMCU_Warning_Flag_12 "Warning Message Flag, Component owner, Supplier align and define for this signal";
CM_ SG_ 1178 RMCU_Reserved_signal1 "Warning Message Flag, Component owner, Supplier align and define for this signal";
CM_ SG_ 1178 RMCU_Reserved_signal2 "Warning Message Flag, Component owner, Supplier align and define for this signal";
CM_ SG_ 1178 RMCU_Reserved_signal3 "Warning Message Flag, Component owner, Supplier align and define for this signal";
CM_ SG_ 1178 RMCU_Reserved_signal4 "Warning Message Flag, Component owner, Supplier align and define for this signal";
CM_ SG_ 1178 RMCU_Reserved_signal5 "Warning Message Flag, Component owner, Supplier align and define for this signal";
CM_ SG_ 1179 CRC_FMCU_WarnMsg "Checksum";
CM_ SG_ 1179 ALIVE_FMCU_WarnMsg "Alive Counter";
CM_ SG_ 1179 FMCU_Warning_Flag_1 "Warning Message Flag, Component owner, Supplier align and define for this signal";
CM_ SG_ 1179 FMCU_Warning_Flag_2 "Warning Message Flag, Component owner, Supplier align and define for this signal";
CM_ SG_ 1179 FMCU_Warning_Flag_3 "Warning Message Flag, Component owner, Supplier align and define for this signal";
CM_ SG_ 1179 FMCU_Warning_Flag_4 "Warning Message Flag, Component owner, Supplier align and define for this signal";
CM_ SG_ 1179 FMCU_Warning_Flag_5 "Warning Message Flag, Component owner, Supplier align and define for this signal";
CM_ SG_ 1179 FMCU_Warning_Flag_6 "Warning Message Flag, Component owner, Supplier align and define for this signal";
CM_ SG_ 1179 FMCU_Warning_Flag_7 "Warning Message Flag, Component owner, Supplier align and define for this signal";
CM_ SG_ 1179 FMCU_Warning_Flag_8 "Warning Message Flag, Component owner, Supplier align and define for this signal";
CM_ SG_ 1179 FMCU_Warning_Flag_9 "Warning Message Flag, Component owner, Supplier align and define for this signal";
CM_ SG_ 1179 FMCU_Warning_Flag_10 "Warning Message Flag, Component owner, Supplier align and define for this signal";
CM_ SG_ 1179 FMCU_Warning_Flag_11 "Warning Message Flag, Component owner, Supplier align and define for this signal";
CM_ SG_ 1179 FMCU_Warning_Flag_12 "Warning Message Flag, Component owner, Supplier align and define for this signal";
CM_ SG_ 1179 FMCU_Reserved_signal1 "Warning Message Flag, Component owner, Supplier align and define for this signal";
CM_ SG_ 1179 FMCU_Reserved_signal2 "Warning Message Flag, Component owner, Supplier align and define for this signal";
CM_ SG_ 1179 FMCU_Reserved_signal3 "Warning Message Flag, Component owner, Supplier align and define for this signal";
CM_ SG_ 1179 FMCU_Reserved_signal4 "Warning Message Flag, Component owner, Supplier align and define for this signal";
CM_ SG_ 1179 FMCU_Reserved_signal5 "Warning Message Flag, Component owner, Supplier align and define for this signal";
CM_ BO_ 1192 "EPS warning message";
CM_ SG_ 1192 CRC_EPS_WarnMsg "Checksum";
CM_ SG_ 1192 ALIVE_EPS_WarnMsg "Alive Counter";
CM_ SG_ 1192 EPS_Malfunction "EPS malfunction, No Power Assistance Steering Available";
CM_ SG_ 1192 EPS_Reduced "EPS reduced, Power Steering Assistance Reduced";
CM_ SG_ 1192 EPS_Overheat "EPS Overheat, No Power Assistance Steering Available";
CM_ SG_ 1192 EPS_NotReady "EPS is not ready, No Power Assistance Steering Available";
CM_ SG_ 1192 EPS_VEH_SPD_VALID "Validity of vehicle speed message detected by EPS";
CM_ SG_ 1192 EPS_HV_SIGNAL_EFF "The effectiveness of high-voltage signals detected by EPS";
CM_ SG_ 1192 EPS_MOS_OT_FLAG "MOS over temperature fault";
CM_ SG_ 1192 EPS_MTR_ANG_CALIB_STS "Motor angle calibration status";
CM_ SG_ 1192 EPS_FAULT_LVL "EPS fault level";
CM_ SG_ 1192 EPS_Reserved_signal2 "Warning Message Flag, Component owner, Supplier align and define for this signal";
CM_ SG_ 1192 EPS_Reserved_signal3 "Warning Message Flag, Component owner, Supplier align and define for this signal";
CM_ SG_ 1192 EPS_Reserved_signal4 "Warning Message Flag, Component owner, Supplier align and define for this signal";
CM_ SG_ 1192 EPS_Reserved_signal5 "Warning Message Flag, Component owner, Supplier align and define for this signal";
CM_ SG_ 1196 CRC_CVC_WarnMsg "Checksum";
CM_ SG_ 1196 ALIVE_CVC_WarnMsg "Alive Counter";
CM_ SG_ 1196 CVC_GearPOnlyAtStationaryAlert "Gear position P only when stationary";
CM_ SG_ 1196 CVC_GearP_NotPossibleAlert "Gear P not possible,  Due to EPP lock is not possible, gear position P may not be possible.";
CM_ SG_ 1196 CVC_PressBrakeToEngageGear "Press Brake to engage gear hint";
CM_ SG_ 1196 CVC_CantChangeGear "Unable to change gear position";
CM_ SG_ 1196 CVC_GearMalfunction "Gear change might be not possible, Possibly faulty selector lever";
CM_ SG_ 1196 CVC_RangeAlert "The range warning, charging soon";
CM_ SG_ 1196 CVC_HVSystemReduced "Reduced HV System Power";
CM_ SG_ 1196 CVC_FrontEDSReduced "Reduced Front EDS Power";
CM_ SG_ 1196 CVC_FrontEDS_Malfunc "Front EDS malfunction";
CM_ SG_ 1196 CVC_RearEDSReduced "Reduced Rear EDS Power";
CM_ SG_ 1196 CVC_RearEDS_Malfunc "Rear EDS malfunction";
CM_ SG_ 1196 CVC_CoolingSystem_Malfunc "EV Cooling system malfunction";
CM_ SG_ 1196 CVC_NeutralRequest "Neutral request warning";
CM_ SG_ 1196 CVC_SoftShutdown "Soft shutdown warning";
CM_ SG_ 1196 CVC_EmergencyShutdown "Emergency Shutdown warning";
CM_ SG_ 1196 CVC_ChgPortDoorSys_Malfunc "Charging Port Door Defective";
CM_ SG_ 1196 CVC_Gearchange_NotPossible "During Game Mode, or charging gun attached, gear change not possible";
CM_ SG_ 1196 CVC_12v_Warning "CVC warning for 12v battery based on data received from BCM";
CM_ SG_ 1196 CVC_WflagRes19 "Reserved CVC Warning message";
CM_ SG_ 1196 CVC_WflagRes20 "Reserved CVC Warning message";
CM_ SG_ 1196 CVC_WflagRes21 "Reserved CVC Warning message";
CM_ SG_ 1196 CVC_WflagRes22 "Reserved CVC Warning message";
CM_ SG_ 1196 CVC_WflagRes23 "Reserved CVC Warning message";
CM_ SG_ 1196 CVC_WflagRes24 "Reserved CVC Warning message";
CM_ SG_ 1196 CVC_WflagRes25 "Reserved CVC Warning message";
CM_ SG_ 1196 CVC_WflagRes26 "Reserved CVC Warning message";
CM_ SG_ 1196 CVC_WflagRes27 "Reserved CVC Warning message";
CM_ SG_ 1196 CVC_SuperFastCharge_longer "CVC SuperFastCharge longer";
CM_ SG_ 1196 CVC_InvalidLimitSpeed "Warning for Invalid Speed limit";
CM_ SG_ 1196 CVC_InvalidCruiseSpeed "Warning for Invalid Cruise Speed";
CM_ SG_ 1196 CVC_Reserved_signal2 "Warning Message Flag, Component owner, Supplier align and define for this signal";
CM_ SG_ 1196 CVC_Reserved_signal3 "Warning Message Flag, Component owner, Supplier align and define for this signal";
CM_ SG_ 1196 CabinCoolDemand "Total Cabin Cooling Demand";
CM_ SG_ 1196 CabinHeatDemand "Total Cabin Heating Demand";
CM_ SG_ 1088 AMP_Sts_EQ_1000HZ "Amplifier setting (audio) equalizer 1000 Hz";
CM_ SG_ 1088 AMP_Sts_EQ_16000HZ "Amplifier setting (audio) equalizer 16000 Hz";
CM_ SG_ 1088 AMP_Sts_EQ_250HZ "Amplifier setting (audio) equalizer 250 Hz";
CM_ SG_ 1088 AMP_Sts_EQ_4000HZ "Amplifier setting (audio) equalizer 4000 Hz";
CM_ SG_ 1088 AMP_Sts_EQ_60HZ "Amplifier Setting (Audio) Equalizer 60Hz";
CM_ SG_ 1088 AMP_Sts_EQType "Amplifier setting equalizer type";
CM_ SG_ 1882 DSP_RUN_STATUS "DSP status";
CM_ SG_ 1882 SYS_RUN_STATUS "System status";
CM_ SG_ 1882 A2B_RUN_STATUS "A2B status";
CM_ SG_ 1882 POWERIC_STATUS "Power IC status";
CM_ SG_ 1882 CHANNEL1_DAIG_STATUS "Channel 1 status";
CM_ SG_ 1882 CHANNEL2_DAIG_STATUS "Channel 2 status";
CM_ SG_ 1882 CHANNEL3_DAIG_STATUS "Channel 3 status";
CM_ SG_ 1882 CHANNEL4_DAIG_STATUS "Channel 4 status";
CM_ SG_ 1882 CHANNEL5_DAIG_STATUS "Channel 5 status";
CM_ SG_ 1882 CHANNEL6_DAIG_STATUS "Channel 6 status";
CM_ SG_ 1882 CHANNEL7_DAIG_STATUS "Channel 7 status";
CM_ SG_ 1882 CHANNEL8_DAIG_STATUS "Channel 8 status";
CM_ SG_ 1882 CHANNEL9_DAIG_STATUS "Channel 9 status";
CM_ SG_ 1882 CHANNEL10_DAIG_STATUS "Channel 10 status";
CM_ SG_ 1882 CHANNEL11_DAIG_STATUS "Channel 11 status";
CM_ SG_ 1882 CHANNEL12_DAIG_STATUS "Channel 12 status";
CM_ SG_ 1882 CHANNEL13_DAIG_STATUS "Channel 13 status";
CM_ SG_ 1882 CHANNEL14_DAIG_STATUS "Channel 14 status";
CM_ SG_ 1882 CHANNEL15_DAIG_STATUS "Channel 15 status";
CM_ SG_ 1882 CHANNEL16_DAIG_STATUS "Channel 16 status";
CM_ BO_ 1136 "Status feedback for MHU_AMP_A2B_Slots";
CM_ SG_ 1136 Slot0_Ready_Sts "Readiness of slot, indicate connection status";
CM_ SG_ 1136 Slot0_Data_Available_Sts "Data availability";
CM_ SG_ 1136 Slot1_Ready_Sts "Readiness of slot, indicate connection status";
CM_ SG_ 1136 Slot1_Data_Available_Sts "Data availability";
CM_ SG_ 1136 Slot2_Ready_Sts "Readiness of slot, indicate connection status";
CM_ SG_ 1136 Slot2_Data_Available_Sts "Data availability";
CM_ SG_ 1136 Slot3_Ready_Sts "Readiness of slot, indicate connection status";
CM_ SG_ 1136 Slot3_Data_Available_Sts "Data availability";
CM_ SG_ 1136 Slot4_Ready_Sts "Readiness of slot, indicate connection status";
CM_ SG_ 1136 Slot4_Data_Available_Sts "Data availability";
CM_ SG_ 1136 Slot5_Ready_Sts "Readiness of slot, indicate connection status";
CM_ SG_ 1136 Slot5_Data_Available_Sts "Data availability";
CM_ SG_ 1136 Slot6_Ready_Sts "Readiness of slot, indicate connection status";
CM_ SG_ 1136 Slot6_Data_Available_Sts "Data availability";
CM_ SG_ 1136 Slot7_Ready_Sts "Readiness of slot, indicate connection status";
CM_ SG_ 1136 Slot7_Data_Available_Sts "Data availability";
CM_ SG_ 1136 Slot8_Ready_Sts "Readiness of slot, indicate connection status";
CM_ SG_ 1136 Slot8_Data_Available_Sts "Data availability";
CM_ SG_ 1136 Slot9_Ready_Sts "Readiness of slot, indicate connection status";
CM_ SG_ 1136 Slot9_Data_Available_Sts "Data availability";
CM_ SG_ 1136 Slot10_Ready_Sts "Readiness of slot, indicate connection status";
CM_ SG_ 1136 Slot10_Data_Available_Sts "Data availability";
CM_ SG_ 1136 Slot11_Ready_Sts "Readiness of slot, indicate connection status";
CM_ SG_ 1136 Slot11_Data_Available_Sts "Data availability";
CM_ SG_ 1136 Slot12_Ready_Sts "Readiness of slot, indicate connection status";
CM_ SG_ 1136 Slot12_Data_Available_Sts "Data availability";
CM_ SG_ 1136 Slot13_Ready_Sts "Readiness of slot, indicate connection status";
CM_ SG_ 1136 Slot13_Data_Available_Sts "Data availability";
CM_ SG_ 1136 Slot14_Ready_Sts "Readiness of slot, indicate connection status";
CM_ SG_ 1136 Slot14_Data_Available_Sts "Data availability";
CM_ SG_ 1136 Slot15_Ready_Sts "Readiness of slot, indicate connection status";
CM_ SG_ 1136 Slot15_Data_Available_Sts "Data availability";
CM_ SG_ 1136 Slot16_Ready_Sts "Readiness of slot, indicate connection status";
CM_ SG_ 1136 Slot16_Data_Available_Sts "Data availability";
CM_ SG_ 1136 Slot17_Ready_Sts "Readiness of slot, indicate connection status";
CM_ SG_ 1136 Slot17_Data_Available_Sts "Data availability";
CM_ SG_ 1136 Slot18_Ready_Sts "Readiness of slot, indicate connection status";
CM_ SG_ 1136 Slot18_Data_Available_Sts "Data availability";
CM_ SG_ 1136 A2B_Initialization_Sts "A2B initialization status";
CM_ SG_ 1141 Slot0_Ready "Readiness of slot, indicate connection status";
CM_ SG_ 1141 Slot0_Data_Available "Data availability";
CM_ SG_ 1141 Slot1_Ready "Readiness of slot, indicate connection status";
CM_ SG_ 1141 Slot1_Data_Available "Data availability";
CM_ SG_ 1141 Slot2_Ready "Readiness of slot, indicate connection status";
CM_ SG_ 1141 Slot2_Data_Available "Data availability";
CM_ SG_ 1141 Slot3_Ready "Readiness of slot, indicate connection status";
CM_ SG_ 1141 Slot3_Data_Available "Data availability";
CM_ SG_ 1141 Slot4_Ready "Readiness of slot, indicate connection status";
CM_ SG_ 1141 Slot4_Data_Available "Data availability";
CM_ SG_ 1141 Slot5_Ready "Readiness of slot, indicate connection status";
CM_ SG_ 1141 Slot5_Data_Available "Data availability";
CM_ SG_ 1141 Slot6_Ready "Readiness of slot, indicate connection status";
CM_ SG_ 1141 Slot6_Data_Available "Data availability";
CM_ SG_ 1141 Slot7_Ready "Readiness of slot, indicate connection status";
CM_ SG_ 1141 Slot7_Data_Available "Data availability";
CM_ SG_ 1141 Slot8_Ready "Readiness of slot, indicate connection status";
CM_ SG_ 1141 Slot8_Data_Available "Data availability";
CM_ SG_ 1141 Slot9_Ready "Readiness of slot, indicate connection status";
CM_ SG_ 1141 Slot9_Data_Available "Data availability";
CM_ SG_ 1141 Slot10_Ready "Readiness of slot, indicate connection status";
CM_ SG_ 1141 Slot10_Data_Available "Data availability";
CM_ SG_ 1141 Slot11_Ready "Readiness of slot, indicate connection status";
CM_ SG_ 1141 Slot11_Data_Available "Data availability";
CM_ SG_ 1141 Slot12_Ready "Readiness of slot, indicate connection status";
CM_ SG_ 1141 Slot12_Data_Available "Data availability";
CM_ SG_ 1141 Slot13_Ready "Readiness of slot, indicate connection status";
CM_ SG_ 1141 Slot13_Data_Available "Data availability";
CM_ SG_ 1141 Slot14_Ready "Readiness of slot, indicate connection status";
CM_ SG_ 1141 Slot14_Data_Available "Data availability";
CM_ SG_ 1141 Slot15_Ready "Readiness of slot, indicate connection status";
CM_ SG_ 1141 Slot15_Data_Available "Data availability";
CM_ SG_ 1141 Slot16_Ready "Readiness of slot, indicate connection status";
CM_ SG_ 1141 Slot16_Data_Available "Data availability";
CM_ SG_ 1141 Slot17_Ready "Readiness of slot, indicate connection status";
CM_ SG_ 1141 Slot17_Data_Available "Data availability";
CM_ SG_ 1141 Slot18_Ready "Readiness of slot, indicate connection status";
CM_ SG_ 1141 Slot18_Data_Available "Data availability";
CM_ SG_ 1141 A2B_Initialization "A2B initialization status";
CM_ BO_ 1137 "Set equalizer from MHU.";
CM_ SG_ 1137 MHU_SET_EQType "Flat - 0Pop - 1Rock - 2Jazz  - 3Classic - 4Vocal - 5Custom - 6Invalid - F";
CM_ SG_ 1109 Audio_Zone "Audio zone";
CM_ SG_ 1109 VehicleSpeedAdjustment_Sensitivi "Adjustment sensitivity ofvolume adjustment following vehicle speed.";
CM_ SG_ 1109 Preset_Value "Sennheiser presets";
CM_ SG_ 1109 Immersive_Level "Sennheiser immersive level";
CM_ SG_ 1109 Media_Volume "Media volume (volume for slot A0 to slot A11)";
CM_ SG_ 1109 TEL_Volume "Volume for slot A12";
CM_ SG_ 1109 Warning_Volume "Volume for Chime: Slot A13 (directional warning) and A16 (safety)";
CM_ SG_ 1109 Navigation_Volume "Volume for prompt of Navigation (volume for Slot A14)";
CM_ SG_ 1109 VA_Volume "Volume for prompt of voice assistant (volume for Slot A15)";
CM_ SG_ 1109 Notification_Volume "Volume for notification (slot A17)";
CM_ SG_ 1109 Ringtone_Volume "Volume for ringtone (slot A18)";
CM_ SG_ 1109 Media_Mute "Mute for Slot A11";
CM_ SG_ 1109 TEL_Mute "Mute for Slot A12";
CM_ SG_ 1109 Warning_Mute "Mute for Chime (slot A13 and A16)";
CM_ SG_ 1109 Navigation_Mute "Mute for Slot A14";
CM_ SG_ 1109 VA_Mute "Mute for Slot A15";
CM_ SG_ 1109 Notification_Mute "Mute for Slot A17";
CM_ SG_ 1109 Ringtone_Mute "Mute for Slot A18";
CM_ SG_ 1109 Global_Mute "Global mute";
CM_ SG_ 1109 Directional_Warning_Mute_FR "Mute front right speakers for directional warning (slot A13)";
CM_ SG_ 1109 Directional_Warning_Mute_RL "Mute rear left speakers for directional warning (slot A13)";
CM_ SG_ 1109 Directional_Warning_Mute_RR "Mute rear right speakers for directional warning (slot A13)";
CM_ SG_ 1109 Directional_Warning_Mute_Center "Mute center dashboard speaker for directional warning (slot A13)";
CM_ BO_ 1138 "Status feedback for setting values from MHU";
CM_ SG_ 1138 Audio_Zone_Sts "Audio zone";
CM_ SG_ 1138 VehicleSpeedAdjustment_Sens_0000 "Adjustment sensitivity ofvolume adjustment following vehicle speed.";
CM_ SG_ 1138 Preset_Value_Sts "Sennheiser presets";
CM_ SG_ 1138 Immersive_Level_Sts "Sennheiser immersive level";
CM_ SG_ 1138 Media_Volume_Sts "Media volume (volume for slot A0 to slot A11)";
CM_ SG_ 1138 TEL_Volume_Sts "Volume for slot A12";
CM_ SG_ 1138 Warning_Volume_Sts "Volume for Chime: Slot A13 (directional warning) and A16 (safety)";
CM_ SG_ 1138 Navigation_Volume_Sts "Volume for prompt of Navigation (volume for Slot A14)";
CM_ SG_ 1138 VA_Volume_Sts "Volume for prompt of voice assistant (volume for Slot A15)";
CM_ SG_ 1138 Notification_Volume_Sts "Volume for notification (slot A17)";
CM_ SG_ 1138 Ringtone_Volume_Sts "Volume for ringtone (slot A18)";
CM_ SG_ 1138 Media_Mute_Sts "Mute for Slot A11";
CM_ SG_ 1138 TEL_Mute_Sts "Mute for Slot A12";
CM_ SG_ 1138 Warning_Mute_Sts "Mute for Chime (slot A13 and A16)";
CM_ SG_ 1138 Navigation_Mute_Sts "Mute for Slot A14";
CM_ SG_ 1138 VA_Mute_Sts "Mute for Slot A15";
CM_ SG_ 1138 Notification_Mute_Sts "Mute for Slot A17";
CM_ SG_ 1138 Ringtone_Mute_Sts "Mute for Slot A18";
CM_ SG_ 1138 Global_Mute_Sts "Global mute";
CM_ SG_ 1138 Directional_Warning_Mute_FL_Sts "Mute front left speakers for directional warning (slot A13)";
CM_ SG_ 1138 Directional_Warning_Mute_FR_Sts "Mute front right speakers for directional warning (slot A13)";
CM_ SG_ 1138 Directional_Warning_Mute_RL_Sts "Mute rear left speakers for directional warning (slot A13)";
CM_ SG_ 1138 Directional_Warning_Mute_RR_Sts "Mute rear right speakers for directional warning (slot A13)";
CM_ SG_ 1138 Directional_Warning_Mute_Center_ "Mute center dashboard speaker for directional warning (slot A13)";
CM_ SG_ 1257 CVC_RHMirrorAdjustmentSet "Right mirror adjustment mode";
CM_ SG_ 1257 CVC_LHMirrorAdjustmentSet "Left mirror adjustment mode";
CM_ SG_ 1257 CVC_SET_MirrorFold_Right "Right side mirror fold";
CM_ SG_ 1257 CVC_SET_MirrorFold_Left "Left side mirror fold";
CM_ SG_ 1257 RHMirror_Adjustment_Req "Right mirror adjustment request";
CM_ SG_ 1257 LHMirror_Adjustment_Req "Left mirror adjustment request";
CM_ SG_ 1257 CVC_SET_LeftMirrorPosX "CVC store Mirror position and send request to BCM_FL";
CM_ SG_ 1257 CVC_SET_LeftMirrorPosY "CVC store Mirror position and send request to BCM_FL";
CM_ SG_ 1257 CVC_SET_RightMirrorPosX "CVC store Mirror position and send request to BCM_FR";
CM_ SG_ 1257 CVC_SET_RightMirrorPosY "CVC store Mirror position and send request to BCM_FR";
CM_ SG_ 256 CRC_MHU_Vehicle_Info "Checksum";
CM_ SG_ 256 ALIVE_MHU_Vehicle_Info "Alive Counter";
CM_ SG_ 256 MHU_Connectivity_Status "Internet Connection Connectivity Status";
CM_ SG_ 257 MHU_DriverAttentionWarn "Driver Attention Monitoring System Warning Level";
CM_ SG_ 257 MHU_DMS_DrvAttentionSts "Driver Monitoring System operating status";
CM_ SG_ 257 MHU_DMS_OperatingSts "Driver visual disengagement status to support autonomous feature (gaze away driving task).";
CM_ SG_ 257 MHU_DMS_DrvVisEngageSts "Driver responsive status (remaining distracted or sleeping 3s after corresponding warning has been issued).";
CM_ SG_ 257 MHU_DMS_DrvRespSts "Driver eyes on/off road status for ACC Stop&Go";
CM_ SG_ 284 TBOX_FOTA_STAT_TerminalReq "CAR state switching request for FOTA";
CM_ SG_ 294 MHU_ISA_SpeedLimitCon_Percent "Speed Limit Control Off Setting Percentage";
CM_ SG_ 294 MHU_ISA_Speed_Setting "Speed Limit Control Offset setting KPH or MPH";
CM_ SG_ 297 CRC_MHU_LOCALSETTING "Checksum";
CM_ SG_ 297 ALIVE_MHU_LocalSetting "Alive Counter";
CM_ SG_ 297 MHU_STAT_SelectedCountry "Current selected country  encoding by ISO 3166-1 numeric";
CM_ SG_ 498 Nav_RoadType "Navigation road type";
CM_ SG_ 498 Nav_VehToTrafEyeDist "Distance between navigation vehicle and electronic signage";
CM_ SG_ 498 Nav_errorSts "Navigation malfunction status";
CM_ SG_ 498 Nav_SpdLimValue "Navigation speed limit";
CM_ SG_ 498 Nav_SpdLimType "Navigation speed limit type";
CM_ SG_ 498 Nav_SpdLimUnit "Navigation speed limit unit";
CM_ SG_ 498 Nav_TimeIndcn "Navigation indication time period";
CM_ SG_ 498 Nav_TimeMod "Navigation Time Mode";
CM_ SG_ 498 Nav_TSRTrafSign "Navigation traffic sign information";
CM_ SG_ 498 Nav_CtryType "Navigation country classification";
CM_ SG_ 506 MHU_TouchEvtTyp "touch screen event type";
CM_ SG_ 506 MHU_XGestureSpd "MHU_XGestureSpd";
CM_ SG_ 506 MHU_YGestureSpd "MHU_YGestureSpd";
CM_ SG_ 506 MHU_Ycoordinate "MHU_Ycoordinate";
CM_ SG_ 506 MHU_Xcoordinate "MHU_Xcoordinate";
BA_DEF_ BO_  "DiagRequest" ENUM  "No","Yes";
BA_DEF_ BO_  "DiagResponse" ENUM  "No","Yes";
BA_DEF_ BO_  "DiagState" ENUM  "No","Yes";
BA_DEF_ BO_  "GenMsgCycleTime" INT 0 65535;
BA_DEF_ BO_  "GenMsgCycleTimeFast" INT 0 65535;
BA_DEF_ BO_  "GenMsgDelayTime" INT 0 65535;
BA_DEF_ BO_  "GenMsgILSupport" ENUM  "No","Yes";
BA_DEF_ BO_  "GenMsgNrOfRepetition" INT 0 65535;
BA_DEF_ BO_  "GenMsgSendType" ENUM  "Cyclic","NoMsgSendType","NotUsed","NotUsed","NotUsed","NotUsed","NotUsed","IfActive","NoMsgSendType","NotUsed";
BA_DEF_ BO_  "NmAsrMessage" ENUM  "No","Yes";
BA_DEF_ BO_  "NmMessage" ENUM  "No","Yes";
BA_DEF_ SG_  "GenSigSendType" ENUM  "Cyclic","NoSigSendType","OnWriteWithRepetition","OnChange","OnChangeWithRepetition","IfActive","IfActiveWithRepetition","OnWrite","NotUsed","NotUsed","NotUsed","NotUsed","NotUsed";
BA_DEF_ SG_  "GenSigStartValue" INT 0 2147483647;
BA_DEF_ SG_  "GenSigTimeoutTime_ALL" INT 0 65535;
BA_DEF_ SG_  "InvalidValue" STRING ;
BA_DEF_ SG_  "GenSigInactiveValue" INT 0 2147483647;
BA_DEF_ BO_  "VFrameFormat" ENUM  "StandardCAN","ExtendedCAN","reserved","J1939PG","reserved","reserved","reserved","reserved","reserved","reserved","reserved","reserved","reserved","reserved","StandardCAN_FD","ExtendedCAN_FD";
BA_DEF_ BO_  "CANFD_BRS" ENUM  "0","1";
BA_DEF_ SG_  "SystemSignalLongSymbol" STRING ;
BA_DEF_ BO_  "SystemMessageLongSymbol" STRING ;
BA_DEF_DEF_  "DiagRequest" "No";
BA_DEF_DEF_  "DiagResponse" "No";
BA_DEF_DEF_  "DiagState" "No";
BA_DEF_DEF_  "GenMsgCycleTime" 0;
BA_DEF_DEF_  "GenMsgCycleTimeFast" 0;
BA_DEF_DEF_  "GenMsgDelayTime" 0;
BA_DEF_DEF_  "GenMsgILSupport" "Yes";
BA_DEF_DEF_  "GenMsgNrOfRepetition" 0;
BA_DEF_DEF_  "GenMsgSendType" "Cyclic";
BA_DEF_DEF_  "NmAsrMessage" "No";
BA_DEF_DEF_  "NmMessage" "No";
BA_DEF_DEF_  "GenSigSendType" "Cyclic";
BA_DEF_DEF_  "GenSigStartValue" 0;
BA_DEF_DEF_  "GenSigTimeoutTime_ALL" 0;
BA_DEF_DEF_  "InvalidValue" "";
BA_DEF_DEF_  "GenSigInactiveValue" 0;
BA_DEF_DEF_  "VFrameFormat" "StandardCAN_FD";
BA_DEF_DEF_  "CANFD_BRS" "1";
BA_DEF_DEF_  "SystemSignalLongSymbol" "";
BA_DEF_DEF_  "SystemMessageLongSymbol" "";
BA_ "GenMsgCycleTime" BO_ 1178 1000;
BA_ "GenMsgCycleTime" BO_ 1179 1000;
BA_ "GenMsgCycleTime" BO_ 1192 100;
BA_ "GenMsgCycleTime" BO_ 1196 100;
BA_ "GenMsgCycleTime" BO_ 1248 100;
BA_ "GenMsgCycleTime" BO_ 1249 100;
BA_ "GenMsgCycleTime" BO_ 1088 100;
BA_ "GenMsgCycleTime" BO_ 1882 50;
BA_ "GenMsgCycleTime" BO_ 1136 50;
BA_ "GenMsgCycleTime" BO_ 1141 50;
BA_ "GenMsgCycleTime" BO_ 1137 100;
BA_ "GenMsgCycleTime" BO_ 1109 100;
BA_ "GenMsgCycleTime" BO_ 1138 100;
BA_ "GenMsgSendType" BO_ 1257 1;
BA_ "GenMsgCycleTime" BO_ 1968 15000;
BA_ "GenMsgCycleTimeFast" BO_ 1968 50;
BA_ "GenMsgNrOfRepetition" BO_ 1968 2;
BA_ "GenMsgCycleTime" BO_ 256 1000;
BA_ "GenMsgCycleTime" BO_ 257 100;
BA_ "GenMsgSendType" BO_ 284 1;
BA_ "GenMsgCycleTime" BO_ 294 50;
BA_ "GenMsgCycleTime" BO_ 297 1000;
BA_ "GenMsgCycleTime" BO_ 498 200;
BA_ "GenMsgSendType" BO_ 506 1;
BA_ "GenMsgCycleTime" BO_ 649 20;
BA_ "InvalidValue" SG_ 1178 ALIVE_RMCU_WarnMsg "Fh";
BA_ "InvalidValue" SG_ 1179 ALIVE_FMCU_WarnMsg "Fh";
BA_ "GenSigTimeoutTime_ALL" SG_ 1192 CRC_EPS_WarnMsg 5000;
BA_ "InvalidValue" SG_ 1192 ALIVE_EPS_WarnMsg "Fh";
BA_ "GenSigTimeoutTime_ALL" SG_ 1192 ALIVE_EPS_WarnMsg 5000;
BA_ "GenSigTimeoutTime_ALL" SG_ 1192 EPS_Malfunction 5000;
BA_ "GenSigSendType" SG_ 1192 EPS_Malfunction 4;
BA_ "GenSigTimeoutTime_ALL" SG_ 1192 EPS_Reduced 5000;
BA_ "GenSigSendType" SG_ 1192 EPS_Reduced 4;
BA_ "GenSigTimeoutTime_ALL" SG_ 1192 EPS_Overheat 5000;
BA_ "GenSigSendType" SG_ 1192 EPS_Overheat 4;
BA_ "GenSigTimeoutTime_ALL" SG_ 1192 EPS_NotReady 5000;
BA_ "GenSigSendType" SG_ 1192 EPS_NotReady 4;
BA_ "GenSigTimeoutTime_ALL" SG_ 1192 EPS_VEH_SPD_VALID 5000;
BA_ "GenSigSendType" SG_ 1192 EPS_VEH_SPD_VALID 4;
BA_ "GenSigTimeoutTime_ALL" SG_ 1192 EPS_HV_SIGNAL_EFF 5000;
BA_ "GenSigSendType" SG_ 1192 EPS_HV_SIGNAL_EFF 4;
BA_ "GenSigTimeoutTime_ALL" SG_ 1192 EPS_MOS_OT_FLAG 5000;
BA_ "GenSigSendType" SG_ 1192 EPS_MOS_OT_FLAG 4;
BA_ "GenSigTimeoutTime_ALL" SG_ 1192 EPS_MTR_ANG_CALIB_STS 5000;
BA_ "GenSigSendType" SG_ 1192 EPS_MTR_ANG_CALIB_STS 4;
BA_ "GenSigTimeoutTime_ALL" SG_ 1192 EPS_FAULT_LVL 5000;
BA_ "GenSigSendType" SG_ 1192 EPS_FAULT_LVL 4;
BA_ "GenSigTimeoutTime_ALL" SG_ 1192 EPS_Reserved_signal2 5000;
BA_ "GenSigSendType" SG_ 1192 EPS_Reserved_signal2 4;
BA_ "GenSigTimeoutTime_ALL" SG_ 1192 EPS_Reserved_signal3 5000;
BA_ "GenSigSendType" SG_ 1192 EPS_Reserved_signal3 4;
BA_ "GenSigTimeoutTime_ALL" SG_ 1192 EPS_Reserved_signal4 5000;
BA_ "GenSigSendType" SG_ 1192 EPS_Reserved_signal4 4;
BA_ "GenSigTimeoutTime_ALL" SG_ 1192 EPS_Reserved_signal5 5000;
BA_ "GenSigSendType" SG_ 1192 EPS_Reserved_signal5 4;
BA_ "InvalidValue" SG_ 1196 ALIVE_CVC_WarnMsg "Fh";
BA_ "InvalidValue" SG_ 1196 CVC_TMSMode "FFh";
BA_ "GenSigTimeoutTime_ALL" SG_ 1248 CRC_CVC_WarnMsgID_1 500;
BA_ "InvalidValue" SG_ 1248 ALIVE_CVC_WarnMsgID_1 "Fh";
BA_ "GenSigTimeoutTime_ALL" SG_ 1248 ALIVE_CVC_WarnMsgID_1 500;
BA_ "GenSigTimeoutTime_ALL" SG_ 1248 WarnMsgID_0 500;
BA_ "GenSigTimeoutTime_ALL" SG_ 1248 WarnMsgID_1 500;
BA_ "GenSigTimeoutTime_ALL" SG_ 1248 WarnMsgID_2 500;
BA_ "GenSigTimeoutTime_ALL" SG_ 1248 WarnMsgID_3 500;
BA_ "GenSigTimeoutTime_ALL" SG_ 1248 WarnMsgID_4 500;
BA_ "GenSigTimeoutTime_ALL" SG_ 1248 WarnMsgID_5 500;
BA_ "GenSigTimeoutTime_ALL" SG_ 1248 WarnMsgID_6 500;
BA_ "GenSigTimeoutTime_ALL" SG_ 1248 WarnMsgID_7 500;
BA_ "GenSigTimeoutTime_ALL" SG_ 1248 WarnMsgID_8 500;
BA_ "GenSigTimeoutTime_ALL" SG_ 1248 WarnMsgID_9 500;
BA_ "GenSigTimeoutTime_ALL" SG_ 1248 WarnMsgID_10 500;
BA_ "GenSigTimeoutTime_ALL" SG_ 1248 WarnMsgID_11 500;
BA_ "GenSigTimeoutTime_ALL" SG_ 1248 WarnMsgID_12 500;
BA_ "GenSigTimeoutTime_ALL" SG_ 1248 WarnMsgID_13 500;
BA_ "GenSigTimeoutTime_ALL" SG_ 1248 WarnMsgID_14 500;
BA_ "GenSigTimeoutTime_ALL" SG_ 1248 WarnMsgID_15 500;
BA_ "GenSigTimeoutTime_ALL" SG_ 1248 WarnMsgID_16 500;
BA_ "GenSigTimeoutTime_ALL" SG_ 1248 WarnMsgID_17 500;
BA_ "GenSigTimeoutTime_ALL" SG_ 1248 WarnMsgID_18 500;
BA_ "GenSigTimeoutTime_ALL" SG_ 1248 WarnMsgID_19 500;
BA_ "GenSigTimeoutTime_ALL" SG_ 1248 WarnMsgID_20 500;
BA_ "GenSigTimeoutTime_ALL" SG_ 1248 WarnMsgID_21 500;
BA_ "GenSigTimeoutTime_ALL" SG_ 1248 WarnMsgID_22 500;
BA_ "GenSigTimeoutTime_ALL" SG_ 1248 WarnMsgID_23 500;
BA_ "GenSigTimeoutTime_ALL" SG_ 1248 WarnMsgID_24 500;
BA_ "GenSigTimeoutTime_ALL" SG_ 1248 WarnMsgID_25 500;
BA_ "GenSigTimeoutTime_ALL" SG_ 1248 WarnMsgID_26 500;
BA_ "GenSigTimeoutTime_ALL" SG_ 1248 WarnMsgID_27 500;
BA_ "GenSigTimeoutTime_ALL" SG_ 1248 WarnMsgID_28 500;
BA_ "GenSigTimeoutTime_ALL" SG_ 1248 WarnMsgID_29 500;
BA_ "GenSigTimeoutTime_ALL" SG_ 1248 WarnMsgID_30 500;
BA_ "GenSigTimeoutTime_ALL" SG_ 1248 WarnMsgID_31 500;
BA_ "GenSigTimeoutTime_ALL" SG_ 1248 WarnMsgID_32 500;
BA_ "GenSigTimeoutTime_ALL" SG_ 1248 WarnMsgID_33 500;
BA_ "GenSigTimeoutTime_ALL" SG_ 1248 WarnMsgID_34 500;
BA_ "GenSigTimeoutTime_ALL" SG_ 1248 WarnMsgID_35 500;
BA_ "GenSigTimeoutTime_ALL" SG_ 1248 WarnMsgID_36 500;
BA_ "GenSigTimeoutTime_ALL" SG_ 1248 WarnMsgID_37 500;
BA_ "GenSigTimeoutTime_ALL" SG_ 1248 WarnMsgID_38 500;
BA_ "GenSigTimeoutTime_ALL" SG_ 1248 WarnMsgID_39 500;
BA_ "GenSigTimeoutTime_ALL" SG_ 1248 WarnMsgID_40 500;
BA_ "GenSigTimeoutTime_ALL" SG_ 1248 WarnMsgID_41 500;
BA_ "GenSigTimeoutTime_ALL" SG_ 1248 WarnMsgID_42 500;
BA_ "GenSigTimeoutTime_ALL" SG_ 1248 WarnMsgID_43 500;
BA_ "GenSigTimeoutTime_ALL" SG_ 1248 WarnMsgID_44 500;
BA_ "GenSigTimeoutTime_ALL" SG_ 1248 WarnMsgID_45 500;
BA_ "GenSigTimeoutTime_ALL" SG_ 1248 WarnMsgID_46 500;
BA_ "GenSigTimeoutTime_ALL" SG_ 1248 WarnMsgID_47 500;
BA_ "GenSigTimeoutTime_ALL" SG_ 1248 WarnMsgID_48 500;
BA_ "GenSigTimeoutTime_ALL" SG_ 1248 WarnMsgID_49 500;
BA_ "GenSigTimeoutTime_ALL" SG_ 1248 WarnMsgID_50 500;
BA_ "GenSigTimeoutTime_ALL" SG_ 1248 WarnMsgID_51 500;
BA_ "GenSigTimeoutTime_ALL" SG_ 1248 WarnMsgID_52 500;
BA_ "GenSigTimeoutTime_ALL" SG_ 1248 WarnMsgID_53 500;
BA_ "GenSigTimeoutTime_ALL" SG_ 1248 WarnMsgID_54 500;
BA_ "GenSigTimeoutTime_ALL" SG_ 1248 WarnMsgID_55 500;
BA_ "GenSigTimeoutTime_ALL" SG_ 1248 WarnMsgID_56 500;
BA_ "GenSigTimeoutTime_ALL" SG_ 1248 WarnMsgID_57 500;
BA_ "GenSigTimeoutTime_ALL" SG_ 1248 WarnMsgID_58 500;
BA_ "GenSigTimeoutTime_ALL" SG_ 1248 WarnMsgID_59 500;
BA_ "GenSigTimeoutTime_ALL" SG_ 1248 WarnMsgID_60 500;
BA_ "GenSigTimeoutTime_ALL" SG_ 1248 WarnMsgID_61 500;
BA_ "GenSigTimeoutTime_ALL" SG_ 1248 WarnMsgID_62 500;
BA_ "GenSigTimeoutTime_ALL" SG_ 1248 WarnMsgID_63 500;
BA_ "GenSigTimeoutTime_ALL" SG_ 1248 WarnMsgID_64 500;
BA_ "GenSigTimeoutTime_ALL" SG_ 1248 WarnMsgID_65 500;
BA_ "GenSigTimeoutTime_ALL" SG_ 1248 WarnMsgID_66 500;
BA_ "GenSigTimeoutTime_ALL" SG_ 1248 WarnMsgID_67 500;
BA_ "GenSigTimeoutTime_ALL" SG_ 1248 WarnMsgID_68 500;
BA_ "GenSigTimeoutTime_ALL" SG_ 1248 WarnMsgID_69 500;
BA_ "GenSigTimeoutTime_ALL" SG_ 1248 WarnMsgID_70 500;
BA_ "GenSigTimeoutTime_ALL" SG_ 1248 WarnMsgID_71 500;
BA_ "GenSigTimeoutTime_ALL" SG_ 1248 WarnMsgID_72 500;
BA_ "GenSigTimeoutTime_ALL" SG_ 1248 WarnMsgID_73 500;
BA_ "GenSigTimeoutTime_ALL" SG_ 1248 WarnMsgID_74 500;
BA_ "GenSigTimeoutTime_ALL" SG_ 1248 WarnMsgID_75 500;
BA_ "GenSigTimeoutTime_ALL" SG_ 1248 WarnMsgID_76 500;
BA_ "GenSigTimeoutTime_ALL" SG_ 1248 WarnMsgID_77 500;
BA_ "GenSigTimeoutTime_ALL" SG_ 1248 WarnMsgID_78 500;
BA_ "GenSigTimeoutTime_ALL" SG_ 1248 WarnMsgID_79 500;
BA_ "GenSigTimeoutTime_ALL" SG_ 1248 WarnMsgID_80 500;
BA_ "GenSigTimeoutTime_ALL" SG_ 1248 WarnMsgID_81 500;
BA_ "GenSigTimeoutTime_ALL" SG_ 1248 WarnMsgID_82 500;
BA_ "GenSigTimeoutTime_ALL" SG_ 1248 WarnMsgID_83 500;
BA_ "GenSigTimeoutTime_ALL" SG_ 1248 WarnMsgID_84 500;
BA_ "GenSigTimeoutTime_ALL" SG_ 1248 WarnMsgID_85 500;
BA_ "GenSigTimeoutTime_ALL" SG_ 1248 WarnMsgID_86 500;
BA_ "GenSigTimeoutTime_ALL" SG_ 1248 WarnMsgID_87 500;
BA_ "GenSigTimeoutTime_ALL" SG_ 1248 WarnMsgID_88 500;
BA_ "GenSigTimeoutTime_ALL" SG_ 1248 WarnMsgID_89 500;
BA_ "GenSigTimeoutTime_ALL" SG_ 1248 WarnMsgID_90 500;
BA_ "GenSigTimeoutTime_ALL" SG_ 1248 WarnMsgID_91 500;
BA_ "GenSigTimeoutTime_ALL" SG_ 1248 WarnMsgID_92 500;
BA_ "GenSigTimeoutTime_ALL" SG_ 1248 WarnMsgID_93 500;
BA_ "GenSigTimeoutTime_ALL" SG_ 1248 WarnMsgID_94 500;
BA_ "GenSigTimeoutTime_ALL" SG_ 1248 WarnMsgID_95 500;
BA_ "GenSigTimeoutTime_ALL" SG_ 1248 WarnMsgID_96 500;
BA_ "GenSigTimeoutTime_ALL" SG_ 1248 WarnMsgID_97 500;
BA_ "GenSigTimeoutTime_ALL" SG_ 1248 WarnMsgID_98 500;
BA_ "GenSigTimeoutTime_ALL" SG_ 1248 WarnMsgID_99 500;
BA_ "GenSigTimeoutTime_ALL" SG_ 1248 WarnMsgID_100 500;
BA_ "GenSigTimeoutTime_ALL" SG_ 1248 WarnMsgID_101 500;
BA_ "GenSigTimeoutTime_ALL" SG_ 1248 WarnMsgID_102 500;
BA_ "GenSigTimeoutTime_ALL" SG_ 1248 WarnMsgID_103 500;
BA_ "GenSigTimeoutTime_ALL" SG_ 1248 WarnMsgID_104 500;
BA_ "GenSigTimeoutTime_ALL" SG_ 1248 WarnMsgID_105 500;
BA_ "GenSigTimeoutTime_ALL" SG_ 1248 WarnMsgID_106 500;
BA_ "GenSigTimeoutTime_ALL" SG_ 1248 WarnMsgID_107 500;
BA_ "GenSigTimeoutTime_ALL" SG_ 1248 WarnMsgID_108 500;
BA_ "GenSigTimeoutTime_ALL" SG_ 1248 WarnMsgID_109 500;
BA_ "GenSigTimeoutTime_ALL" SG_ 1248 WarnMsgID_110 500;
BA_ "GenSigTimeoutTime_ALL" SG_ 1248 WarnMsgID_111 500;
BA_ "GenSigTimeoutTime_ALL" SG_ 1248 WarnMsgID_112 500;
BA_ "GenSigTimeoutTime_ALL" SG_ 1248 WarnMsgID_113 500;
BA_ "GenSigTimeoutTime_ALL" SG_ 1248 WarnMsgID_114 500;
BA_ "GenSigTimeoutTime_ALL" SG_ 1248 WarnMsgID_115 500;
BA_ "GenSigTimeoutTime_ALL" SG_ 1248 WarnMsgID_116 500;
BA_ "GenSigTimeoutTime_ALL" SG_ 1248 WarnMsgID_117 500;
BA_ "GenSigTimeoutTime_ALL" SG_ 1248 WarnMsgID_118 500;
BA_ "GenSigTimeoutTime_ALL" SG_ 1248 WarnMsgID_119 500;
BA_ "GenSigTimeoutTime_ALL" SG_ 1248 WarnMsgID_120 500;
BA_ "GenSigTimeoutTime_ALL" SG_ 1248 WarnMsgID_121 500;
BA_ "GenSigTimeoutTime_ALL" SG_ 1248 WarnMsgID_122 500;
BA_ "GenSigTimeoutTime_ALL" SG_ 1248 WarnMsgID_123 500;
BA_ "GenSigTimeoutTime_ALL" SG_ 1248 WarnMsgID_124 500;
BA_ "GenSigTimeoutTime_ALL" SG_ 1248 WarnMsgID_125 500;
BA_ "GenSigTimeoutTime_ALL" SG_ 1248 WarnMsgID_126 500;
BA_ "GenSigTimeoutTime_ALL" SG_ 1248 WarnMsgID_127 500;
BA_ "GenSigTimeoutTime_ALL" SG_ 1248 WarnMsgID_128 500;
BA_ "GenSigTimeoutTime_ALL" SG_ 1248 WarnMsgID_129 500;
BA_ "GenSigTimeoutTime_ALL" SG_ 1248 WarnMsgID_130 500;
BA_ "GenSigTimeoutTime_ALL" SG_ 1248 WarnMsgID_131 500;
BA_ "GenSigTimeoutTime_ALL" SG_ 1248 WarnMsgID_132 500;
BA_ "GenSigTimeoutTime_ALL" SG_ 1248 WarnMsgID_133 500;
BA_ "GenSigTimeoutTime_ALL" SG_ 1248 WarnMsgID_134 500;
BA_ "GenSigTimeoutTime_ALL" SG_ 1248 WarnMsgID_135 500;
BA_ "GenSigTimeoutTime_ALL" SG_ 1248 WarnMsgID_136 500;
BA_ "GenSigTimeoutTime_ALL" SG_ 1248 WarnMsgID_137 500;
BA_ "GenSigTimeoutTime_ALL" SG_ 1248 WarnMsgID_138 500;
BA_ "GenSigTimeoutTime_ALL" SG_ 1248 WarnMsgID_139 500;
BA_ "GenSigTimeoutTime_ALL" SG_ 1248 WarnMsgID_140 500;
BA_ "GenSigTimeoutTime_ALL" SG_ 1248 WarnMsgID_141 500;
BA_ "GenSigTimeoutTime_ALL" SG_ 1248 WarnMsgID_142 500;
BA_ "GenSigTimeoutTime_ALL" SG_ 1248 WarnMsgID_143 500;
BA_ "GenSigTimeoutTime_ALL" SG_ 1248 WarnMsgID_144 500;
BA_ "GenSigTimeoutTime_ALL" SG_ 1248 WarnMsgID_145 500;
BA_ "GenSigTimeoutTime_ALL" SG_ 1248 WarnMsgID_146 500;
BA_ "GenSigTimeoutTime_ALL" SG_ 1248 WarnMsgID_147 500;
BA_ "GenSigTimeoutTime_ALL" SG_ 1248 WarnMsgID_148 500;
BA_ "GenSigTimeoutTime_ALL" SG_ 1248 WarnMsgID_149 500;
BA_ "GenSigTimeoutTime_ALL" SG_ 1248 WarnMsgID_150 500;
BA_ "GenSigTimeoutTime_ALL" SG_ 1248 WarnMsgID_151 500;
BA_ "GenSigTimeoutTime_ALL" SG_ 1248 WarnMsgID_152 500;
BA_ "GenSigTimeoutTime_ALL" SG_ 1248 WarnMsgID_153 500;
BA_ "GenSigTimeoutTime_ALL" SG_ 1248 WarnMsgID_154 500;
BA_ "GenSigTimeoutTime_ALL" SG_ 1248 WarnMsgID_155 500;
BA_ "GenSigTimeoutTime_ALL" SG_ 1248 WarnMsgID_156 500;
BA_ "GenSigTimeoutTime_ALL" SG_ 1248 WarnMsgID_157 500;
BA_ "GenSigTimeoutTime_ALL" SG_ 1248 WarnMsgID_158 500;
BA_ "GenSigTimeoutTime_ALL" SG_ 1248 WarnMsgID_159 500;
BA_ "GenSigTimeoutTime_ALL" SG_ 1248 WarnMsgID_160 500;
BA_ "GenSigTimeoutTime_ALL" SG_ 1248 WarnMsgID_161 500;
BA_ "GenSigTimeoutTime_ALL" SG_ 1248 WarnMsgID_162 500;
BA_ "GenSigTimeoutTime_ALL" SG_ 1248 WarnMsgID_163 500;
BA_ "GenSigTimeoutTime_ALL" SG_ 1248 WarnMsgID_164 500;
BA_ "GenSigTimeoutTime_ALL" SG_ 1248 WarnMsgID_165 500;
BA_ "GenSigTimeoutTime_ALL" SG_ 1248 WarnMsgID_166 500;
BA_ "GenSigTimeoutTime_ALL" SG_ 1248 WarnMsgID_167 500;
BA_ "GenSigTimeoutTime_ALL" SG_ 1248 WarnMsgID_168 500;
BA_ "GenSigTimeoutTime_ALL" SG_ 1248 WarnMsgID_169 500;
BA_ "GenSigTimeoutTime_ALL" SG_ 1248 WarnMsgID_170 500;
BA_ "GenSigTimeoutTime_ALL" SG_ 1248 WarnMsgID_171 500;
BA_ "GenSigTimeoutTime_ALL" SG_ 1248 WarnMsgID_172 500;
BA_ "GenSigTimeoutTime_ALL" SG_ 1248 WarnMsgID_173 500;
BA_ "GenSigTimeoutTime_ALL" SG_ 1248 WarnMsgID_174 500;
BA_ "GenSigTimeoutTime_ALL" SG_ 1248 WarnMsgID_175 500;
BA_ "GenSigTimeoutTime_ALL" SG_ 1248 WarnMsgID_176 500;
BA_ "GenSigTimeoutTime_ALL" SG_ 1248 WarnMsgID_177 500;
BA_ "GenSigTimeoutTime_ALL" SG_ 1248 WarnMsgID_178 500;
BA_ "GenSigTimeoutTime_ALL" SG_ 1248 WarnMsgID_179 500;
BA_ "GenSigTimeoutTime_ALL" SG_ 1248 WarnMsgID_180 500;
BA_ "GenSigTimeoutTime_ALL" SG_ 1248 WarnMsgID_181 500;
BA_ "GenSigTimeoutTime_ALL" SG_ 1248 WarnMsgID_182 500;
BA_ "GenSigTimeoutTime_ALL" SG_ 1248 WarnMsgID_183 500;
BA_ "GenSigTimeoutTime_ALL" SG_ 1248 WarnMsgID_184 500;
BA_ "GenSigTimeoutTime_ALL" SG_ 1248 WarnMsgID_185 500;
BA_ "GenSigTimeoutTime_ALL" SG_ 1248 WarnMsgID_186 500;
BA_ "GenSigTimeoutTime_ALL" SG_ 1248 WarnMsgID_187 500;
BA_ "GenSigTimeoutTime_ALL" SG_ 1248 WarnMsgID_188 500;
BA_ "GenSigTimeoutTime_ALL" SG_ 1248 WarnMsgID_189 500;
BA_ "GenSigTimeoutTime_ALL" SG_ 1248 WarnMsgID_190 500;
BA_ "GenSigTimeoutTime_ALL" SG_ 1248 WarnMsgID_191 500;
BA_ "GenSigTimeoutTime_ALL" SG_ 1248 WarnMsgID_192 500;
BA_ "GenSigTimeoutTime_ALL" SG_ 1248 WarnMsgID_193 500;
BA_ "GenSigTimeoutTime_ALL" SG_ 1248 WarnMsgID_194 500;
BA_ "GenSigTimeoutTime_ALL" SG_ 1248 WarnMsgID_195 500;
BA_ "GenSigTimeoutTime_ALL" SG_ 1248 WarnMsgID_196 500;
BA_ "GenSigTimeoutTime_ALL" SG_ 1248 WarnMsgID_197 500;
BA_ "GenSigTimeoutTime_ALL" SG_ 1248 WarnMsgID_198 500;
BA_ "GenSigTimeoutTime_ALL" SG_ 1248 WarnMsgID_199 500;
BA_ "GenSigTimeoutTime_ALL" SG_ 1248 WarnMsgID_200 500;
BA_ "GenSigTimeoutTime_ALL" SG_ 1248 WarnMsgID_201 500;
BA_ "GenSigTimeoutTime_ALL" SG_ 1248 WarnMsgID_202 500;
BA_ "GenSigTimeoutTime_ALL" SG_ 1248 WarnMsgID_203 500;
BA_ "GenSigTimeoutTime_ALL" SG_ 1248 WarnMsgID_204 500;
BA_ "GenSigTimeoutTime_ALL" SG_ 1248 WarnMsgID_205 500;
BA_ "GenSigTimeoutTime_ALL" SG_ 1248 WarnMsgID_206 500;
BA_ "GenSigTimeoutTime_ALL" SG_ 1248 WarnMsgID_207 500;
BA_ "GenSigTimeoutTime_ALL" SG_ 1248 WarnMsgID_208 500;
BA_ "GenSigTimeoutTime_ALL" SG_ 1248 WarnMsgID_209 500;
BA_ "GenSigTimeoutTime_ALL" SG_ 1248 WarnMsgID_210 500;
BA_ "GenSigTimeoutTime_ALL" SG_ 1248 WarnMsgID_211 500;
BA_ "GenSigTimeoutTime_ALL" SG_ 1248 WarnMsgID_212 500;
BA_ "GenSigTimeoutTime_ALL" SG_ 1248 WarnMsgID_213 500;
BA_ "GenSigTimeoutTime_ALL" SG_ 1248 WarnMsgID_214 500;
BA_ "GenSigTimeoutTime_ALL" SG_ 1248 WarnMsgID_215 500;
BA_ "GenSigTimeoutTime_ALL" SG_ 1248 WarnMsgID_216 500;
BA_ "GenSigTimeoutTime_ALL" SG_ 1248 WarnMsgID_217 500;
BA_ "GenSigTimeoutTime_ALL" SG_ 1248 WarnMsgID_218 500;
BA_ "GenSigTimeoutTime_ALL" SG_ 1248 WarnMsgID_219 500;
BA_ "GenSigTimeoutTime_ALL" SG_ 1248 WarnMsgID_220 500;
BA_ "GenSigTimeoutTime_ALL" SG_ 1248 WarnMsgID_221 500;
BA_ "GenSigTimeoutTime_ALL" SG_ 1248 WarnMsgID_222 500;
BA_ "GenSigTimeoutTime_ALL" SG_ 1248 WarnMsgID_223 500;
BA_ "GenSigTimeoutTime_ALL" SG_ 1248 WarnMsgID_224 500;
BA_ "GenSigTimeoutTime_ALL" SG_ 1248 WarnMsgID_225 500;
BA_ "GenSigTimeoutTime_ALL" SG_ 1248 WarnMsgID_226 500;
BA_ "GenSigTimeoutTime_ALL" SG_ 1248 WarnMsgID_227 500;
BA_ "GenSigTimeoutTime_ALL" SG_ 1248 WarnMsgID_228 500;
BA_ "GenSigTimeoutTime_ALL" SG_ 1248 WarnMsgID_229 500;
BA_ "GenSigTimeoutTime_ALL" SG_ 1248 WarnMsgID_230 500;
BA_ "GenSigTimeoutTime_ALL" SG_ 1248 WarnMsgID_231 500;
BA_ "GenSigTimeoutTime_ALL" SG_ 1248 WarnMsgID_232 500;
BA_ "GenSigTimeoutTime_ALL" SG_ 1248 WarnMsgID_233 500;
BA_ "GenSigTimeoutTime_ALL" SG_ 1248 WarnMsgID_234 500;
BA_ "GenSigTimeoutTime_ALL" SG_ 1248 WarnMsgID_235 500;
BA_ "GenSigTimeoutTime_ALL" SG_ 1248 WarnMsgID_236 500;
BA_ "GenSigTimeoutTime_ALL" SG_ 1248 WarnMsgID_237 500;
BA_ "GenSigTimeoutTime_ALL" SG_ 1248 WarnMsgID_238 500;
BA_ "GenSigTimeoutTime_ALL" SG_ 1248 WarnMsgID_239 500;
BA_ "GenSigTimeoutTime_ALL" SG_ 1248 WarnMsgID_240 500;
BA_ "GenSigTimeoutTime_ALL" SG_ 1248 WarnMsgID_241 500;
BA_ "GenSigTimeoutTime_ALL" SG_ 1248 WarnMsgID_242 500;
BA_ "GenSigTimeoutTime_ALL" SG_ 1248 WarnMsgID_243 500;
BA_ "GenSigTimeoutTime_ALL" SG_ 1248 WarnMsgID_244 500;
BA_ "GenSigTimeoutTime_ALL" SG_ 1248 WarnMsgID_245 500;
BA_ "GenSigTimeoutTime_ALL" SG_ 1248 WarnMsgID_246 500;
BA_ "GenSigTimeoutTime_ALL" SG_ 1248 WarnMsgID_247 500;
BA_ "GenSigTimeoutTime_ALL" SG_ 1248 WarnMsgID_248 500;
BA_ "GenSigTimeoutTime_ALL" SG_ 1248 WarnMsgID_249 500;
BA_ "GenSigTimeoutTime_ALL" SG_ 1248 WarnMsgID_250 500;
BA_ "GenSigTimeoutTime_ALL" SG_ 1248 WarnMsgID_251 500;
BA_ "GenSigTimeoutTime_ALL" SG_ 1248 WarnMsgID_252 500;
BA_ "GenSigTimeoutTime_ALL" SG_ 1248 WarnMsgID_253 500;
BA_ "GenSigTimeoutTime_ALL" SG_ 1248 WarnMsgID_254 500;
BA_ "GenSigTimeoutTime_ALL" SG_ 1248 WarnMsgID_255 500;
BA_ "GenSigTimeoutTime_ALL" SG_ 1248 WarnMsgID_256 500;
BA_ "GenSigTimeoutTime_ALL" SG_ 1248 WarnMsgID_257 500;
BA_ "GenSigTimeoutTime_ALL" SG_ 1248 WarnMsgID_258 500;
BA_ "GenSigTimeoutTime_ALL" SG_ 1248 WarnMsgID_259 500;
BA_ "GenSigTimeoutTime_ALL" SG_ 1248 WarnMsgID_260 500;
BA_ "GenSigTimeoutTime_ALL" SG_ 1248 WarnMsgID_261 500;
BA_ "GenSigTimeoutTime_ALL" SG_ 1248 WarnMsgID_262 500;
BA_ "GenSigTimeoutTime_ALL" SG_ 1248 WarnMsgID_263 500;
BA_ "GenSigTimeoutTime_ALL" SG_ 1248 WarnMsgID_264 500;
BA_ "GenSigTimeoutTime_ALL" SG_ 1248 WarnMsgID_265 500;
BA_ "GenSigTimeoutTime_ALL" SG_ 1248 WarnMsgID_266 500;
BA_ "GenSigTimeoutTime_ALL" SG_ 1248 WarnMsgID_267 500;
BA_ "GenSigTimeoutTime_ALL" SG_ 1248 WarnMsgID_268 500;
BA_ "GenSigTimeoutTime_ALL" SG_ 1248 WarnMsgID_269 500;
BA_ "GenSigTimeoutTime_ALL" SG_ 1248 WarnMsgID_270 500;
BA_ "GenSigTimeoutTime_ALL" SG_ 1248 WarnMsgID_271 500;
BA_ "GenSigTimeoutTime_ALL" SG_ 1248 WarnMsgID_272 500;
BA_ "GenSigTimeoutTime_ALL" SG_ 1248 WarnMsgID_273 500;
BA_ "GenSigTimeoutTime_ALL" SG_ 1248 WarnMsgID_274 500;
BA_ "GenSigTimeoutTime_ALL" SG_ 1248 WarnMsgID_275 500;
BA_ "GenSigTimeoutTime_ALL" SG_ 1248 WarnMsgID_276 500;
BA_ "GenSigTimeoutTime_ALL" SG_ 1248 WarnMsgID_277 500;
BA_ "GenSigTimeoutTime_ALL" SG_ 1248 WarnMsgID_278 500;
BA_ "GenSigTimeoutTime_ALL" SG_ 1248 WarnMsgID_279 500;
BA_ "GenSigTimeoutTime_ALL" SG_ 1248 WarnMsgID_280 500;
BA_ "GenSigTimeoutTime_ALL" SG_ 1248 WarnMsgID_281 500;
BA_ "GenSigTimeoutTime_ALL" SG_ 1248 WarnMsgID_282 500;
BA_ "GenSigTimeoutTime_ALL" SG_ 1248 WarnMsgID_283 500;
BA_ "GenSigTimeoutTime_ALL" SG_ 1248 WarnMsgID_284 500;
BA_ "GenSigTimeoutTime_ALL" SG_ 1248 WarnMsgID_285 500;
BA_ "GenSigTimeoutTime_ALL" SG_ 1248 WarnMsgID_286 500;
BA_ "GenSigTimeoutTime_ALL" SG_ 1248 WarnMsgID_287 500;
BA_ "GenSigTimeoutTime_ALL" SG_ 1248 WarnMsgID_288 500;
BA_ "GenSigTimeoutTime_ALL" SG_ 1248 WarnMsgID_289 500;
BA_ "GenSigTimeoutTime_ALL" SG_ 1248 WarnMsgID_290 500;
BA_ "GenSigTimeoutTime_ALL" SG_ 1248 WarnMsgID_291 500;
BA_ "GenSigTimeoutTime_ALL" SG_ 1248 WarnMsgID_292 500;
BA_ "GenSigTimeoutTime_ALL" SG_ 1248 WarnMsgID_293 500;
BA_ "GenSigTimeoutTime_ALL" SG_ 1248 WarnMsgID_294 500;
BA_ "GenSigTimeoutTime_ALL" SG_ 1248 WarnMsgID_295 500;
BA_ "GenSigTimeoutTime_ALL" SG_ 1248 WarnMsgID_296 500;
BA_ "GenSigTimeoutTime_ALL" SG_ 1248 WarnMsgID_297 500;
BA_ "GenSigTimeoutTime_ALL" SG_ 1248 WarnMsgID_298 500;
BA_ "GenSigTimeoutTime_ALL" SG_ 1248 WarnMsgID_299 500;
BA_ "GenSigTimeoutTime_ALL" SG_ 1248 WarnMsgID_300 500;
BA_ "GenSigTimeoutTime_ALL" SG_ 1248 WarnMsgID_301 500;
BA_ "GenSigTimeoutTime_ALL" SG_ 1248 WarnMsgID_302 500;
BA_ "GenSigTimeoutTime_ALL" SG_ 1248 WarnMsgID_303 500;
BA_ "GenSigTimeoutTime_ALL" SG_ 1248 WarnMsgID_304 500;
BA_ "GenSigTimeoutTime_ALL" SG_ 1248 WarnMsgID_305 500;
BA_ "GenSigTimeoutTime_ALL" SG_ 1248 WarnMsgID_306 500;
BA_ "GenSigTimeoutTime_ALL" SG_ 1248 WarnMsgID_307 500;
BA_ "GenSigTimeoutTime_ALL" SG_ 1248 WarnMsgID_308 500;
BA_ "GenSigTimeoutTime_ALL" SG_ 1248 WarnMsgID_309 500;
BA_ "GenSigTimeoutTime_ALL" SG_ 1248 WarnMsgID_310 500;
BA_ "GenSigTimeoutTime_ALL" SG_ 1248 WarnMsgID_311 500;
BA_ "GenSigTimeoutTime_ALL" SG_ 1248 WarnMsgID_312 500;
BA_ "GenSigTimeoutTime_ALL" SG_ 1248 WarnMsgID_313 500;
BA_ "GenSigTimeoutTime_ALL" SG_ 1248 WarnMsgID_314 500;
BA_ "GenSigTimeoutTime_ALL" SG_ 1248 WarnMsgID_315 500;
BA_ "GenSigTimeoutTime_ALL" SG_ 1248 WarnMsgID_316 500;
BA_ "GenSigTimeoutTime_ALL" SG_ 1248 WarnMsgID_317 500;
BA_ "GenSigTimeoutTime_ALL" SG_ 1248 WarnMsgID_318 500;
BA_ "GenSigTimeoutTime_ALL" SG_ 1248 WarnMsgID_319 500;
BA_ "GenSigTimeoutTime_ALL" SG_ 1248 WarnMsgID_320 500;
BA_ "GenSigTimeoutTime_ALL" SG_ 1248 WarnMsgID_321 500;
BA_ "GenSigTimeoutTime_ALL" SG_ 1248 WarnMsgID_322 500;
BA_ "GenSigTimeoutTime_ALL" SG_ 1248 WarnMsgID_323 500;
BA_ "GenSigTimeoutTime_ALL" SG_ 1248 WarnMsgID_324 500;
BA_ "GenSigTimeoutTime_ALL" SG_ 1248 WarnMsgID_325 500;
BA_ "GenSigTimeoutTime_ALL" SG_ 1248 WarnMsgID_326 500;
BA_ "GenSigTimeoutTime_ALL" SG_ 1248 WarnMsgID_327 500;
BA_ "GenSigTimeoutTime_ALL" SG_ 1248 WarnMsgID_328 500;
BA_ "GenSigTimeoutTime_ALL" SG_ 1248 WarnMsgID_329 500;
BA_ "GenSigTimeoutTime_ALL" SG_ 1248 WarnMsgID_330 500;
BA_ "GenSigTimeoutTime_ALL" SG_ 1248 WarnMsgID_331 500;
BA_ "GenSigTimeoutTime_ALL" SG_ 1248 WarnMsgID_332 500;
BA_ "GenSigTimeoutTime_ALL" SG_ 1248 WarnMsgID_333 500;
BA_ "GenSigTimeoutTime_ALL" SG_ 1248 WarnMsgID_334 500;
BA_ "GenSigTimeoutTime_ALL" SG_ 1248 WarnMsgID_335 500;
BA_ "GenSigTimeoutTime_ALL" SG_ 1248 WarnMsgID_336 500;
BA_ "GenSigTimeoutTime_ALL" SG_ 1248 WarnMsgID_337 500;
BA_ "GenSigTimeoutTime_ALL" SG_ 1248 WarnMsgID_338 500;
BA_ "GenSigTimeoutTime_ALL" SG_ 1248 WarnMsgID_339 500;
BA_ "GenSigTimeoutTime_ALL" SG_ 1248 WarnMsgID_340 500;
BA_ "GenSigTimeoutTime_ALL" SG_ 1248 WarnMsgID_341 500;
BA_ "GenSigTimeoutTime_ALL" SG_ 1248 WarnMsgID_342 500;
BA_ "GenSigTimeoutTime_ALL" SG_ 1248 WarnMsgID_343 500;
BA_ "GenSigTimeoutTime_ALL" SG_ 1248 WarnMsgID_344 500;
BA_ "GenSigTimeoutTime_ALL" SG_ 1248 WarnMsgID_345 500;
BA_ "GenSigTimeoutTime_ALL" SG_ 1248 WarnMsgID_346 500;
BA_ "GenSigTimeoutTime_ALL" SG_ 1248 WarnMsgID_347 500;
BA_ "GenSigTimeoutTime_ALL" SG_ 1248 WarnMsgID_348 500;
BA_ "GenSigTimeoutTime_ALL" SG_ 1248 WarnMsgID_349 500;
BA_ "GenSigTimeoutTime_ALL" SG_ 1248 WarnMsgID_350 500;
BA_ "GenSigTimeoutTime_ALL" SG_ 1248 WarnMsgID_351 500;
BA_ "GenSigTimeoutTime_ALL" SG_ 1248 WarnMsgID_352 500;
BA_ "GenSigTimeoutTime_ALL" SG_ 1248 WarnMsgID_353 500;
BA_ "GenSigTimeoutTime_ALL" SG_ 1248 WarnMsgID_354 500;
BA_ "GenSigTimeoutTime_ALL" SG_ 1248 WarnMsgID_355 500;
BA_ "GenSigTimeoutTime_ALL" SG_ 1248 WarnMsgID_356 500;
BA_ "GenSigTimeoutTime_ALL" SG_ 1248 WarnMsgID_357 500;
BA_ "GenSigTimeoutTime_ALL" SG_ 1248 WarnMsgID_358 500;
BA_ "GenSigTimeoutTime_ALL" SG_ 1248 WarnMsgID_359 500;
BA_ "GenSigTimeoutTime_ALL" SG_ 1248 WarnMsgID_360 500;
BA_ "GenSigTimeoutTime_ALL" SG_ 1248 WarnMsgID_361 500;
BA_ "GenSigTimeoutTime_ALL" SG_ 1248 WarnMsgID_362 500;
BA_ "GenSigTimeoutTime_ALL" SG_ 1248 WarnMsgID_363 500;
BA_ "GenSigTimeoutTime_ALL" SG_ 1248 WarnMsgID_364 500;
BA_ "GenSigTimeoutTime_ALL" SG_ 1248 WarnMsgID_365 500;
BA_ "GenSigTimeoutTime_ALL" SG_ 1248 WarnMsgID_366 500;
BA_ "GenSigTimeoutTime_ALL" SG_ 1248 WarnMsgID_367 500;
BA_ "GenSigTimeoutTime_ALL" SG_ 1248 WarnMsgID_368 500;
BA_ "GenSigTimeoutTime_ALL" SG_ 1248 WarnMsgID_369 500;
BA_ "GenSigTimeoutTime_ALL" SG_ 1248 WarnMsgID_370 500;
BA_ "GenSigTimeoutTime_ALL" SG_ 1248 WarnMsgID_371 500;
BA_ "GenSigTimeoutTime_ALL" SG_ 1248 WarnMsgID_372 500;
BA_ "GenSigTimeoutTime_ALL" SG_ 1248 WarnMsgID_373 500;
BA_ "GenSigTimeoutTime_ALL" SG_ 1248 WarnMsgID_374 500;
BA_ "GenSigTimeoutTime_ALL" SG_ 1248 WarnMsgID_375 500;
BA_ "GenSigTimeoutTime_ALL" SG_ 1248 WarnMsgID_376 500;
BA_ "GenSigTimeoutTime_ALL" SG_ 1248 WarnMsgID_377 500;
BA_ "GenSigTimeoutTime_ALL" SG_ 1248 WarnMsgID_378 500;
BA_ "GenSigTimeoutTime_ALL" SG_ 1248 WarnMsgID_379 500;
BA_ "GenSigTimeoutTime_ALL" SG_ 1248 WarnMsgID_380 500;
BA_ "GenSigTimeoutTime_ALL" SG_ 1248 WarnMsgID_381 500;
BA_ "GenSigTimeoutTime_ALL" SG_ 1248 WarnMsgID_382 500;
BA_ "GenSigTimeoutTime_ALL" SG_ 1248 WarnMsgID_383 500;
BA_ "GenSigTimeoutTime_ALL" SG_ 1248 WarnMsgID_384 500;
BA_ "GenSigTimeoutTime_ALL" SG_ 1248 WarnMsgID_385 500;
BA_ "GenSigTimeoutTime_ALL" SG_ 1248 WarnMsgID_386 500;
BA_ "GenSigTimeoutTime_ALL" SG_ 1248 WarnMsgID_387 500;
BA_ "GenSigTimeoutTime_ALL" SG_ 1248 WarnMsgID_388 500;
BA_ "GenSigTimeoutTime_ALL" SG_ 1248 WarnMsgID_389 500;
BA_ "GenSigTimeoutTime_ALL" SG_ 1248 WarnMsgID_390 500;
BA_ "GenSigTimeoutTime_ALL" SG_ 1248 WarnMsgID_391 500;
BA_ "GenSigTimeoutTime_ALL" SG_ 1248 WarnMsgID_392 500;
BA_ "GenSigTimeoutTime_ALL" SG_ 1248 WarnMsgID_393 500;
BA_ "GenSigTimeoutTime_ALL" SG_ 1248 WarnMsgID_394 500;
BA_ "GenSigTimeoutTime_ALL" SG_ 1248 WarnMsgID_395 500;
BA_ "GenSigTimeoutTime_ALL" SG_ 1248 WarnMsgID_396 500;
BA_ "GenSigTimeoutTime_ALL" SG_ 1248 WarnMsgID_397 500;
BA_ "GenSigTimeoutTime_ALL" SG_ 1248 WarnMsgID_398 500;
BA_ "GenSigTimeoutTime_ALL" SG_ 1248 WarnMsgID_399 500;
BA_ "GenSigTimeoutTime_ALL" SG_ 1248 WarnMsgID_400 500;
BA_ "GenSigTimeoutTime_ALL" SG_ 1248 WarnMsgID_401 500;
BA_ "GenSigTimeoutTime_ALL" SG_ 1248 WarnMsgID_402 500;
BA_ "GenSigTimeoutTime_ALL" SG_ 1248 WarnMsgID_403 500;
BA_ "GenSigTimeoutTime_ALL" SG_ 1248 WarnMsgID_404 500;
BA_ "GenSigTimeoutTime_ALL" SG_ 1248 WarnMsgID_405 500;
BA_ "GenSigTimeoutTime_ALL" SG_ 1248 WarnMsgID_406 500;
BA_ "GenSigTimeoutTime_ALL" SG_ 1248 WarnMsgID_407 500;
BA_ "GenSigTimeoutTime_ALL" SG_ 1248 WarnMsgID_408 500;
BA_ "GenSigTimeoutTime_ALL" SG_ 1248 WarnMsgID_409 500;
BA_ "GenSigTimeoutTime_ALL" SG_ 1248 WarnMsgID_410 500;
BA_ "GenSigTimeoutTime_ALL" SG_ 1248 WarnMsgID_411 500;
BA_ "GenSigTimeoutTime_ALL" SG_ 1248 WarnMsgID_412 500;
BA_ "GenSigTimeoutTime_ALL" SG_ 1248 WarnMsgID_413 500;
BA_ "GenSigTimeoutTime_ALL" SG_ 1248 WarnMsgID_414 500;
BA_ "GenSigTimeoutTime_ALL" SG_ 1248 WarnMsgID_415 500;
BA_ "GenSigTimeoutTime_ALL" SG_ 1248 WarnMsgID_416 500;
BA_ "GenSigTimeoutTime_ALL" SG_ 1248 WarnMsgID_417 500;
BA_ "GenSigTimeoutTime_ALL" SG_ 1248 WarnMsgID_418 500;
BA_ "GenSigTimeoutTime_ALL" SG_ 1248 WarnMsgID_419 500;
BA_ "GenSigTimeoutTime_ALL" SG_ 1248 WarnMsgID_420 500;
BA_ "GenSigTimeoutTime_ALL" SG_ 1248 WarnMsgID_421 500;
BA_ "GenSigTimeoutTime_ALL" SG_ 1248 WarnMsgID_422 500;
BA_ "GenSigTimeoutTime_ALL" SG_ 1248 WarnMsgID_423 500;
BA_ "GenSigTimeoutTime_ALL" SG_ 1248 WarnMsgID_424 500;
BA_ "GenSigTimeoutTime_ALL" SG_ 1248 WarnMsgID_425 500;
BA_ "GenSigTimeoutTime_ALL" SG_ 1248 WarnMsgID_426 500;
BA_ "GenSigTimeoutTime_ALL" SG_ 1248 WarnMsgID_427 500;
BA_ "GenSigTimeoutTime_ALL" SG_ 1248 WarnMsgID_428 500;
BA_ "GenSigTimeoutTime_ALL" SG_ 1248 WarnMsgID_429 500;
BA_ "GenSigTimeoutTime_ALL" SG_ 1248 WarnMsgID_430 500;
BA_ "GenSigTimeoutTime_ALL" SG_ 1248 WarnMsgID_431 500;
BA_ "GenSigTimeoutTime_ALL" SG_ 1248 WarnMsgID_432 500;
BA_ "GenSigTimeoutTime_ALL" SG_ 1248 WarnMsgID_433 500;
BA_ "GenSigTimeoutTime_ALL" SG_ 1248 WarnMsgID_434 500;
BA_ "GenSigTimeoutTime_ALL" SG_ 1248 WarnMsgID_435 500;
BA_ "GenSigTimeoutTime_ALL" SG_ 1248 WarnMsgID_436 500;
BA_ "GenSigTimeoutTime_ALL" SG_ 1248 WarnMsgID_437 500;
BA_ "GenSigTimeoutTime_ALL" SG_ 1248 WarnMsgID_438 500;
BA_ "GenSigTimeoutTime_ALL" SG_ 1248 WarnMsgID_439 500;
BA_ "GenSigTimeoutTime_ALL" SG_ 1248 WarnMsgID_440 500;
BA_ "GenSigTimeoutTime_ALL" SG_ 1248 WarnMsgID_441 500;
BA_ "GenSigTimeoutTime_ALL" SG_ 1248 WarnMsgID_442 500;
BA_ "GenSigTimeoutTime_ALL" SG_ 1248 WarnMsgID_443 500;
BA_ "GenSigTimeoutTime_ALL" SG_ 1248 WarnMsgID_444 500;
BA_ "GenSigTimeoutTime_ALL" SG_ 1248 WarnMsgID_445 500;
BA_ "GenSigTimeoutTime_ALL" SG_ 1248 WarnMsgID_446 500;
BA_ "GenSigTimeoutTime_ALL" SG_ 1248 WarnMsgID_447 500;
BA_ "GenSigTimeoutTime_ALL" SG_ 1248 WarnMsgID_448 500;
BA_ "GenSigTimeoutTime_ALL" SG_ 1248 WarnMsgID_449 500;
BA_ "GenSigTimeoutTime_ALL" SG_ 1248 WarnMsgID_450 500;
BA_ "GenSigTimeoutTime_ALL" SG_ 1248 WarnMsgID_451 500;
BA_ "GenSigTimeoutTime_ALL" SG_ 1248 WarnMsgID_452 500;
BA_ "GenSigTimeoutTime_ALL" SG_ 1248 WarnMsgID_453 500;
BA_ "GenSigTimeoutTime_ALL" SG_ 1248 WarnMsgID_454 500;
BA_ "GenSigTimeoutTime_ALL" SG_ 1248 WarnMsgID_455 500;
BA_ "GenSigTimeoutTime_ALL" SG_ 1248 WarnMsgID_456 500;
BA_ "GenSigTimeoutTime_ALL" SG_ 1248 WarnMsgID_457 500;
BA_ "GenSigTimeoutTime_ALL" SG_ 1248 WarnMsgID_458 500;
BA_ "GenSigTimeoutTime_ALL" SG_ 1248 WarnMsgID_459 500;
BA_ "GenSigTimeoutTime_ALL" SG_ 1248 WarnMsgID_460 500;
BA_ "GenSigTimeoutTime_ALL" SG_ 1248 WarnMsgID_461 500;
BA_ "GenSigTimeoutTime_ALL" SG_ 1248 WarnMsgID_462 500;
BA_ "GenSigTimeoutTime_ALL" SG_ 1248 WarnMsgID_463 500;
BA_ "GenSigTimeoutTime_ALL" SG_ 1248 WarnMsgID_464 500;
BA_ "GenSigTimeoutTime_ALL" SG_ 1248 WarnMsgID_465 500;
BA_ "GenSigTimeoutTime_ALL" SG_ 1248 WarnMsgID_466 500;
BA_ "GenSigTimeoutTime_ALL" SG_ 1248 WarnMsgID_467 500;
BA_ "GenSigTimeoutTime_ALL" SG_ 1248 WarnMsgID_468 500;
BA_ "GenSigTimeoutTime_ALL" SG_ 1248 WarnMsgID_469 500;
BA_ "GenSigTimeoutTime_ALL" SG_ 1248 WarnMsgID_470 500;
BA_ "GenSigTimeoutTime_ALL" SG_ 1248 WarnMsgID_471 500;
BA_ "GenSigTimeoutTime_ALL" SG_ 1248 WarnMsgID_472 500;
BA_ "GenSigTimeoutTime_ALL" SG_ 1248 WarnMsgID_473 500;
BA_ "GenSigTimeoutTime_ALL" SG_ 1248 WarnMsgID_474 500;
BA_ "GenSigTimeoutTime_ALL" SG_ 1248 WarnMsgID_475 500;
BA_ "GenSigTimeoutTime_ALL" SG_ 1248 WarnMsgID_476 500;
BA_ "GenSigTimeoutTime_ALL" SG_ 1248 WarnMsgID_477 500;
BA_ "GenSigTimeoutTime_ALL" SG_ 1248 WarnMsgID_478 500;
BA_ "GenSigTimeoutTime_ALL" SG_ 1248 WarnMsgID_479 500;
BA_ "GenSigTimeoutTime_ALL" SG_ 1248 WarnMsgID_480 500;
BA_ "GenSigTimeoutTime_ALL" SG_ 1248 WarnMsgID_481 500;
BA_ "GenSigTimeoutTime_ALL" SG_ 1248 WarnMsgID_482 500;
BA_ "GenSigTimeoutTime_ALL" SG_ 1248 WarnMsgID_483 500;
BA_ "GenSigTimeoutTime_ALL" SG_ 1248 WarnMsgID_484 500;
BA_ "GenSigTimeoutTime_ALL" SG_ 1248 WarnMsgID_485 500;
BA_ "GenSigTimeoutTime_ALL" SG_ 1248 WarnMsgID_486 500;
BA_ "GenSigTimeoutTime_ALL" SG_ 1248 WarnMsgID_487 500;
BA_ "GenSigTimeoutTime_ALL" SG_ 1248 WarnMsgID_488 500;
BA_ "GenSigTimeoutTime_ALL" SG_ 1248 WarnMsgID_489 500;
BA_ "GenSigTimeoutTime_ALL" SG_ 1248 WarnMsgID_490 500;
BA_ "GenSigTimeoutTime_ALL" SG_ 1248 WarnMsgID_491 500;
BA_ "GenSigTimeoutTime_ALL" SG_ 1248 WarnMsgID_492 500;
BA_ "GenSigTimeoutTime_ALL" SG_ 1248 WarnMsgID_493 500;
BA_ "GenSigTimeoutTime_ALL" SG_ 1248 WarnMsgID_494 500;
BA_ "GenSigTimeoutTime_ALL" SG_ 1248 WarnMsgID_495 500;
BA_ "GenSigTimeoutTime_ALL" SG_ 1248 WarnMsgID_496 500;
BA_ "GenSigTimeoutTime_ALL" SG_ 1248 WarnMsgID_497 500;
BA_ "GenSigTimeoutTime_ALL" SG_ 1248 WarnMsgID_498 500;
BA_ "GenSigTimeoutTime_ALL" SG_ 1248 WarnMsgID_499 500;
BA_ "GenSigTimeoutTime_ALL" SG_ 1249 CRC_CVC_WarnMsgID_2 500;
BA_ "InvalidValue" SG_ 1249 ALIVE_CVC_WarnMsgID_2 "Fh";
BA_ "GenSigTimeoutTime_ALL" SG_ 1249 ALIVE_CVC_WarnMsgID_2 500;
BA_ "GenSigTimeoutTime_ALL" SG_ 1249 WarnMsgID_500 500;
BA_ "GenSigTimeoutTime_ALL" SG_ 1249 WarnMsgID_501 500;
BA_ "GenSigTimeoutTime_ALL" SG_ 1249 WarnMsgID_502 500;
BA_ "GenSigTimeoutTime_ALL" SG_ 1249 WarnMsgID_503 500;
BA_ "GenSigTimeoutTime_ALL" SG_ 1249 WarnMsgID_504 500;
BA_ "GenSigTimeoutTime_ALL" SG_ 1249 WarnMsgID_505 500;
BA_ "GenSigTimeoutTime_ALL" SG_ 1249 WarnMsgID_506 500;
BA_ "GenSigTimeoutTime_ALL" SG_ 1249 WarnMsgID_507 500;
BA_ "GenSigTimeoutTime_ALL" SG_ 1249 WarnMsgID_508 500;
BA_ "GenSigTimeoutTime_ALL" SG_ 1249 WarnMsgID_509 500;
BA_ "GenSigTimeoutTime_ALL" SG_ 1249 WarnMsgID_510 500;
BA_ "GenSigTimeoutTime_ALL" SG_ 1249 WarnMsgID_511 500;
BA_ "GenSigTimeoutTime_ALL" SG_ 1249 WarnMsgID_512 500;
BA_ "GenSigTimeoutTime_ALL" SG_ 1249 WarnMsgID_513 500;
BA_ "GenSigTimeoutTime_ALL" SG_ 1249 WarnMsgID_514 500;
BA_ "GenSigTimeoutTime_ALL" SG_ 1249 WarnMsgID_515 500;
BA_ "GenSigTimeoutTime_ALL" SG_ 1249 WarnMsgID_516 500;
BA_ "GenSigTimeoutTime_ALL" SG_ 1249 WarnMsgID_517 500;
BA_ "GenSigTimeoutTime_ALL" SG_ 1249 WarnMsgID_518 500;
BA_ "GenSigTimeoutTime_ALL" SG_ 1249 WarnMsgID_519 500;
BA_ "GenSigTimeoutTime_ALL" SG_ 1249 WarnMsgID_520 500;
BA_ "GenSigTimeoutTime_ALL" SG_ 1249 WarnMsgID_521 500;
BA_ "GenSigTimeoutTime_ALL" SG_ 1249 WarnMsgID_522 500;
BA_ "GenSigTimeoutTime_ALL" SG_ 1249 WarnMsgID_523 500;
BA_ "GenSigTimeoutTime_ALL" SG_ 1249 WarnMsgID_524 500;
BA_ "GenSigTimeoutTime_ALL" SG_ 1249 WarnMsgID_525 500;
BA_ "GenSigTimeoutTime_ALL" SG_ 1249 WarnMsgID_526 500;
BA_ "GenSigTimeoutTime_ALL" SG_ 1249 WarnMsgID_527 500;
BA_ "GenSigTimeoutTime_ALL" SG_ 1249 WarnMsgID_528 500;
BA_ "GenSigTimeoutTime_ALL" SG_ 1249 WarnMsgID_529 500;
BA_ "GenSigTimeoutTime_ALL" SG_ 1249 WarnMsgID_530 500;
BA_ "GenSigTimeoutTime_ALL" SG_ 1249 WarnMsgID_531 500;
BA_ "GenSigTimeoutTime_ALL" SG_ 1249 WarnMsgID_532 500;
BA_ "GenSigTimeoutTime_ALL" SG_ 1249 WarnMsgID_533 500;
BA_ "GenSigTimeoutTime_ALL" SG_ 1249 WarnMsgID_534 500;
BA_ "GenSigTimeoutTime_ALL" SG_ 1249 WarnMsgID_535 500;
BA_ "GenSigTimeoutTime_ALL" SG_ 1249 WarnMsgID_536 500;
BA_ "GenSigTimeoutTime_ALL" SG_ 1249 WarnMsgID_537 500;
BA_ "GenSigTimeoutTime_ALL" SG_ 1249 WarnMsgID_538 500;
BA_ "GenSigTimeoutTime_ALL" SG_ 1249 WarnMsgID_539 500;
BA_ "GenSigTimeoutTime_ALL" SG_ 1249 WarnMsgID_540 500;
BA_ "GenSigTimeoutTime_ALL" SG_ 1249 WarnMsgID_541 500;
BA_ "GenSigTimeoutTime_ALL" SG_ 1249 WarnMsgID_542 500;
BA_ "GenSigTimeoutTime_ALL" SG_ 1249 WarnMsgID_543 500;
BA_ "GenSigTimeoutTime_ALL" SG_ 1249 WarnMsgID_544 500;
BA_ "GenSigTimeoutTime_ALL" SG_ 1249 WarnMsgID_545 500;
BA_ "GenSigTimeoutTime_ALL" SG_ 1249 WarnMsgID_546 500;
BA_ "GenSigTimeoutTime_ALL" SG_ 1249 WarnMsgID_547 500;
BA_ "GenSigTimeoutTime_ALL" SG_ 1249 WarnMsgID_548 500;
BA_ "GenSigTimeoutTime_ALL" SG_ 1249 WarnMsgID_549 500;
BA_ "GenSigTimeoutTime_ALL" SG_ 1249 WarnMsgID_550 500;
BA_ "GenSigTimeoutTime_ALL" SG_ 1249 WarnMsgID_551 500;
BA_ "GenSigTimeoutTime_ALL" SG_ 1249 WarnMsgID_552 500;
BA_ "GenSigTimeoutTime_ALL" SG_ 1249 WarnMsgID_553 500;
BA_ "GenSigTimeoutTime_ALL" SG_ 1249 WarnMsgID_554 500;
BA_ "GenSigTimeoutTime_ALL" SG_ 1249 WarnMsgID_555 500;
BA_ "GenSigTimeoutTime_ALL" SG_ 1249 WarnMsgID_556 500;
BA_ "GenSigTimeoutTime_ALL" SG_ 1249 WarnMsgID_557 500;
BA_ "GenSigTimeoutTime_ALL" SG_ 1249 WarnMsgID_558 500;
BA_ "GenSigTimeoutTime_ALL" SG_ 1249 WarnMsgID_559 500;
BA_ "GenSigTimeoutTime_ALL" SG_ 1249 WarnMsgID_560 500;
BA_ "GenSigTimeoutTime_ALL" SG_ 1249 WarnMsgID_561 500;
BA_ "GenSigTimeoutTime_ALL" SG_ 1249 WarnMsgID_562 500;
BA_ "GenSigTimeoutTime_ALL" SG_ 1249 WarnMsgID_563 500;
BA_ "GenSigTimeoutTime_ALL" SG_ 1249 WarnMsgID_564 500;
BA_ "GenSigTimeoutTime_ALL" SG_ 1249 WarnMsgID_565 500;
BA_ "GenSigTimeoutTime_ALL" SG_ 1249 WarnMsgID_566 500;
BA_ "GenSigTimeoutTime_ALL" SG_ 1249 WarnMsgID_567 500;
BA_ "GenSigTimeoutTime_ALL" SG_ 1249 WarnMsgID_568 500;
BA_ "GenSigTimeoutTime_ALL" SG_ 1249 WarnMsgID_569 500;
BA_ "GenSigTimeoutTime_ALL" SG_ 1249 WarnMsgID_570 500;
BA_ "GenSigTimeoutTime_ALL" SG_ 1249 WarnMsgID_571 500;
BA_ "GenSigTimeoutTime_ALL" SG_ 1249 WarnMsgID_572 500;
BA_ "GenSigTimeoutTime_ALL" SG_ 1249 WarnMsgID_573 500;
BA_ "GenSigTimeoutTime_ALL" SG_ 1249 WarnMsgID_574 500;
BA_ "GenSigTimeoutTime_ALL" SG_ 1249 WarnMsgID_575 500;
BA_ "GenSigTimeoutTime_ALL" SG_ 1249 WarnMsgID_576 500;
BA_ "GenSigTimeoutTime_ALL" SG_ 1249 WarnMsgID_577 500;
BA_ "GenSigTimeoutTime_ALL" SG_ 1249 WarnMsgID_578 500;
BA_ "GenSigTimeoutTime_ALL" SG_ 1249 WarnMsgID_579 500;
BA_ "GenSigTimeoutTime_ALL" SG_ 1249 WarnMsgID_580 500;
BA_ "GenSigTimeoutTime_ALL" SG_ 1249 WarnMsgID_581 500;
BA_ "GenSigTimeoutTime_ALL" SG_ 1249 WarnMsgID_582 500;
BA_ "GenSigTimeoutTime_ALL" SG_ 1249 WarnMsgID_583 500;
BA_ "GenSigTimeoutTime_ALL" SG_ 1249 WarnMsgID_584 500;
BA_ "GenSigTimeoutTime_ALL" SG_ 1249 WarnMsgID_585 500;
BA_ "GenSigTimeoutTime_ALL" SG_ 1249 WarnMsgID_586 500;
BA_ "GenSigTimeoutTime_ALL" SG_ 1249 WarnMsgID_587 500;
BA_ "GenSigTimeoutTime_ALL" SG_ 1249 WarnMsgID_588 500;
BA_ "GenSigTimeoutTime_ALL" SG_ 1249 WarnMsgID_589 500;
BA_ "GenSigTimeoutTime_ALL" SG_ 1249 WarnMsgID_590 500;
BA_ "GenSigTimeoutTime_ALL" SG_ 1249 WarnMsgID_591 500;
BA_ "GenSigTimeoutTime_ALL" SG_ 1249 WarnMsgID_592 500;
BA_ "GenSigTimeoutTime_ALL" SG_ 1249 WarnMsgID_593 500;
BA_ "GenSigTimeoutTime_ALL" SG_ 1249 WarnMsgID_594 500;
BA_ "GenSigTimeoutTime_ALL" SG_ 1249 WarnMsgID_595 500;
BA_ "GenSigTimeoutTime_ALL" SG_ 1249 WarnMsgID_596 500;
BA_ "GenSigTimeoutTime_ALL" SG_ 1249 WarnMsgID_597 500;
BA_ "GenSigTimeoutTime_ALL" SG_ 1249 WarnMsgID_598 500;
BA_ "GenSigTimeoutTime_ALL" SG_ 1249 WarnMsgID_599 500;
BA_ "GenSigTimeoutTime_ALL" SG_ 1249 WarnMsgID_600 500;
BA_ "GenSigTimeoutTime_ALL" SG_ 1249 WarnMsgID_601 500;
BA_ "GenSigTimeoutTime_ALL" SG_ 1249 WarnMsgID_602 500;
BA_ "GenSigTimeoutTime_ALL" SG_ 1249 WarnMsgID_603 500;
BA_ "GenSigTimeoutTime_ALL" SG_ 1249 WarnMsgID_604 500;
BA_ "GenSigTimeoutTime_ALL" SG_ 1249 WarnMsgID_605 500;
BA_ "GenSigTimeoutTime_ALL" SG_ 1249 WarnMsgID_606 500;
BA_ "GenSigTimeoutTime_ALL" SG_ 1249 WarnMsgID_607 500;
BA_ "GenSigTimeoutTime_ALL" SG_ 1249 WarnMsgID_608 500;
BA_ "GenSigTimeoutTime_ALL" SG_ 1249 WarnMsgID_609 500;
BA_ "GenSigTimeoutTime_ALL" SG_ 1249 WarnMsgID_610 500;
BA_ "GenSigTimeoutTime_ALL" SG_ 1249 WarnMsgID_611 500;
BA_ "GenSigTimeoutTime_ALL" SG_ 1249 WarnMsgID_612 500;
BA_ "GenSigTimeoutTime_ALL" SG_ 1249 WarnMsgID_613 500;
BA_ "GenSigTimeoutTime_ALL" SG_ 1249 WarnMsgID_614 500;
BA_ "GenSigTimeoutTime_ALL" SG_ 1249 WarnMsgID_615 500;
BA_ "GenSigTimeoutTime_ALL" SG_ 1249 WarnMsgID_616 500;
BA_ "GenSigTimeoutTime_ALL" SG_ 1249 WarnMsgID_617 500;
BA_ "GenSigTimeoutTime_ALL" SG_ 1249 WarnMsgID_618 500;
BA_ "GenSigTimeoutTime_ALL" SG_ 1249 WarnMsgID_619 500;
BA_ "GenSigTimeoutTime_ALL" SG_ 1249 WarnMsgID_620 500;
BA_ "GenSigTimeoutTime_ALL" SG_ 1249 WarnMsgID_621 500;
BA_ "GenSigTimeoutTime_ALL" SG_ 1249 WarnMsgID_622 500;
BA_ "GenSigTimeoutTime_ALL" SG_ 1249 WarnMsgID_623 500;
BA_ "GenSigTimeoutTime_ALL" SG_ 1249 WarnMsgID_624 500;
BA_ "GenSigTimeoutTime_ALL" SG_ 1249 WarnMsgID_625 500;
BA_ "GenSigTimeoutTime_ALL" SG_ 1249 WarnMsgID_626 500;
BA_ "GenSigTimeoutTime_ALL" SG_ 1249 WarnMsgID_627 500;
BA_ "GenSigTimeoutTime_ALL" SG_ 1249 WarnMsgID_628 500;
BA_ "GenSigTimeoutTime_ALL" SG_ 1249 WarnMsgID_629 500;
BA_ "GenSigTimeoutTime_ALL" SG_ 1249 WarnMsgID_630 500;
BA_ "GenSigTimeoutTime_ALL" SG_ 1249 WarnMsgID_631 500;
BA_ "GenSigTimeoutTime_ALL" SG_ 1249 WarnMsgID_632 500;
BA_ "GenSigTimeoutTime_ALL" SG_ 1249 WarnMsgID_633 500;
BA_ "GenSigTimeoutTime_ALL" SG_ 1249 WarnMsgID_634 500;
BA_ "GenSigTimeoutTime_ALL" SG_ 1249 WarnMsgID_635 500;
BA_ "GenSigTimeoutTime_ALL" SG_ 1249 WarnMsgID_636 500;
BA_ "GenSigTimeoutTime_ALL" SG_ 1249 WarnMsgID_637 500;
BA_ "GenSigTimeoutTime_ALL" SG_ 1249 WarnMsgID_638 500;
BA_ "GenSigTimeoutTime_ALL" SG_ 1249 WarnMsgID_639 500;
BA_ "GenSigTimeoutTime_ALL" SG_ 1249 WarnMsgID_640 500;
BA_ "GenSigTimeoutTime_ALL" SG_ 1249 WarnMsgID_641 500;
BA_ "GenSigTimeoutTime_ALL" SG_ 1249 WarnMsgID_642 500;
BA_ "GenSigTimeoutTime_ALL" SG_ 1249 WarnMsgID_643 500;
BA_ "GenSigTimeoutTime_ALL" SG_ 1249 WarnMsgID_644 500;
BA_ "GenSigTimeoutTime_ALL" SG_ 1249 WarnMsgID_645 500;
BA_ "GenSigTimeoutTime_ALL" SG_ 1249 WarnMsgID_646 500;
BA_ "GenSigTimeoutTime_ALL" SG_ 1249 WarnMsgID_647 500;
BA_ "GenSigTimeoutTime_ALL" SG_ 1249 WarnMsgID_648 500;
BA_ "GenSigTimeoutTime_ALL" SG_ 1249 WarnMsgID_649 500;
BA_ "GenSigTimeoutTime_ALL" SG_ 1249 WarnMsgID_650 500;
BA_ "GenSigTimeoutTime_ALL" SG_ 1249 WarnMsgID_651 500;
BA_ "GenSigTimeoutTime_ALL" SG_ 1249 WarnMsgID_652 500;
BA_ "GenSigTimeoutTime_ALL" SG_ 1249 WarnMsgID_653 500;
BA_ "GenSigTimeoutTime_ALL" SG_ 1249 WarnMsgID_654 500;
BA_ "GenSigTimeoutTime_ALL" SG_ 1249 WarnMsgID_655 500;
BA_ "GenSigTimeoutTime_ALL" SG_ 1249 WarnMsgID_656 500;
BA_ "GenSigTimeoutTime_ALL" SG_ 1249 WarnMsgID_657 500;
BA_ "GenSigTimeoutTime_ALL" SG_ 1249 WarnMsgID_658 500;
BA_ "GenSigTimeoutTime_ALL" SG_ 1249 WarnMsgID_659 500;
BA_ "GenSigTimeoutTime_ALL" SG_ 1249 WarnMsgID_660 500;
BA_ "GenSigTimeoutTime_ALL" SG_ 1249 WarnMsgID_661 500;
BA_ "GenSigTimeoutTime_ALL" SG_ 1249 WarnMsgID_662 500;
BA_ "GenSigTimeoutTime_ALL" SG_ 1249 WarnMsgID_663 500;
BA_ "GenSigTimeoutTime_ALL" SG_ 1249 WarnMsgID_664 500;
BA_ "GenSigTimeoutTime_ALL" SG_ 1249 WarnMsgID_665 500;
BA_ "GenSigTimeoutTime_ALL" SG_ 1249 WarnMsgID_666 500;
BA_ "GenSigTimeoutTime_ALL" SG_ 1249 WarnMsgID_667 500;
BA_ "GenSigTimeoutTime_ALL" SG_ 1249 WarnMsgID_668 500;
BA_ "GenSigTimeoutTime_ALL" SG_ 1249 WarnMsgID_669 500;
BA_ "GenSigTimeoutTime_ALL" SG_ 1249 WarnMsgID_670 500;
BA_ "GenSigTimeoutTime_ALL" SG_ 1249 WarnMsgID_671 500;
BA_ "GenSigTimeoutTime_ALL" SG_ 1249 WarnMsgID_672 500;
BA_ "GenSigTimeoutTime_ALL" SG_ 1249 WarnMsgID_673 500;
BA_ "GenSigTimeoutTime_ALL" SG_ 1249 WarnMsgID_674 500;
BA_ "GenSigTimeoutTime_ALL" SG_ 1249 WarnMsgID_675 500;
BA_ "GenSigTimeoutTime_ALL" SG_ 1249 WarnMsgID_676 500;
BA_ "GenSigTimeoutTime_ALL" SG_ 1249 WarnMsgID_677 500;
BA_ "GenSigTimeoutTime_ALL" SG_ 1249 WarnMsgID_678 500;
BA_ "GenSigTimeoutTime_ALL" SG_ 1249 WarnMsgID_679 500;
BA_ "GenSigTimeoutTime_ALL" SG_ 1249 WarnMsgID_680 500;
BA_ "GenSigTimeoutTime_ALL" SG_ 1249 WarnMsgID_681 500;
BA_ "GenSigTimeoutTime_ALL" SG_ 1249 WarnMsgID_682 500;
BA_ "GenSigTimeoutTime_ALL" SG_ 1249 WarnMsgID_683 500;
BA_ "GenSigTimeoutTime_ALL" SG_ 1249 WarnMsgID_684 500;
BA_ "GenSigTimeoutTime_ALL" SG_ 1249 WarnMsgID_685 500;
BA_ "GenSigTimeoutTime_ALL" SG_ 1249 WarnMsgID_686 500;
BA_ "GenSigTimeoutTime_ALL" SG_ 1249 WarnMsgID_687 500;
BA_ "GenSigTimeoutTime_ALL" SG_ 1249 WarnMsgID_688 500;
BA_ "GenSigTimeoutTime_ALL" SG_ 1249 WarnMsgID_689 500;
BA_ "GenSigTimeoutTime_ALL" SG_ 1249 WarnMsgID_690 500;
BA_ "GenSigTimeoutTime_ALL" SG_ 1249 WarnMsgID_691 500;
BA_ "GenSigTimeoutTime_ALL" SG_ 1249 WarnMsgID_692 500;
BA_ "GenSigTimeoutTime_ALL" SG_ 1249 WarnMsgID_693 500;
BA_ "GenSigTimeoutTime_ALL" SG_ 1249 WarnMsgID_694 500;
BA_ "GenSigTimeoutTime_ALL" SG_ 1249 WarnMsgID_695 500;
BA_ "GenSigTimeoutTime_ALL" SG_ 1249 WarnMsgID_696 500;
BA_ "GenSigTimeoutTime_ALL" SG_ 1249 WarnMsgID_697 500;
BA_ "GenSigTimeoutTime_ALL" SG_ 1249 WarnMsgID_698 500;
BA_ "GenSigTimeoutTime_ALL" SG_ 1249 WarnMsgID_699 500;
BA_ "GenSigTimeoutTime_ALL" SG_ 1249 WarnMsgID_700 500;
BA_ "GenSigTimeoutTime_ALL" SG_ 1249 WarnMsgID_701 500;
BA_ "GenSigTimeoutTime_ALL" SG_ 1249 WarnMsgID_702 500;
BA_ "GenSigTimeoutTime_ALL" SG_ 1249 WarnMsgID_703 500;
BA_ "GenSigTimeoutTime_ALL" SG_ 1249 WarnMsgID_704 500;
BA_ "GenSigTimeoutTime_ALL" SG_ 1249 WarnMsgID_705 500;
BA_ "GenSigTimeoutTime_ALL" SG_ 1249 WarnMsgID_706 500;
BA_ "GenSigTimeoutTime_ALL" SG_ 1249 WarnMsgID_707 500;
BA_ "GenSigTimeoutTime_ALL" SG_ 1249 WarnMsgID_708 500;
BA_ "GenSigTimeoutTime_ALL" SG_ 1249 WarnMsgID_709 500;
BA_ "GenSigTimeoutTime_ALL" SG_ 1249 WarnMsgID_710 500;
BA_ "GenSigTimeoutTime_ALL" SG_ 1249 WarnMsgID_711 500;
BA_ "GenSigTimeoutTime_ALL" SG_ 1249 WarnMsgID_712 500;
BA_ "GenSigTimeoutTime_ALL" SG_ 1249 WarnMsgID_713 500;
BA_ "GenSigTimeoutTime_ALL" SG_ 1249 WarnMsgID_714 500;
BA_ "GenSigTimeoutTime_ALL" SG_ 1249 WarnMsgID_715 500;
BA_ "GenSigTimeoutTime_ALL" SG_ 1249 WarnMsgID_716 500;
BA_ "GenSigTimeoutTime_ALL" SG_ 1249 WarnMsgID_717 500;
BA_ "GenSigTimeoutTime_ALL" SG_ 1249 WarnMsgID_718 500;
BA_ "GenSigTimeoutTime_ALL" SG_ 1249 WarnMsgID_719 500;
BA_ "GenSigTimeoutTime_ALL" SG_ 1249 WarnMsgID_720 500;
BA_ "GenSigTimeoutTime_ALL" SG_ 1249 WarnMsgID_721 500;
BA_ "GenSigTimeoutTime_ALL" SG_ 1249 WarnMsgID_722 500;
BA_ "GenSigTimeoutTime_ALL" SG_ 1249 WarnMsgID_723 500;
BA_ "GenSigTimeoutTime_ALL" SG_ 1249 WarnMsgID_724 500;
BA_ "GenSigTimeoutTime_ALL" SG_ 1249 WarnMsgID_725 500;
BA_ "GenSigTimeoutTime_ALL" SG_ 1249 WarnMsgID_726 500;
BA_ "GenSigTimeoutTime_ALL" SG_ 1249 WarnMsgID_727 500;
BA_ "GenSigTimeoutTime_ALL" SG_ 1249 WarnMsgID_728 500;
BA_ "GenSigTimeoutTime_ALL" SG_ 1249 WarnMsgID_729 500;
BA_ "GenSigTimeoutTime_ALL" SG_ 1249 WarnMsgID_730 500;
BA_ "GenSigTimeoutTime_ALL" SG_ 1249 WarnMsgID_731 500;
BA_ "GenSigTimeoutTime_ALL" SG_ 1249 WarnMsgID_732 500;
BA_ "GenSigTimeoutTime_ALL" SG_ 1249 WarnMsgID_733 500;
BA_ "GenSigTimeoutTime_ALL" SG_ 1249 WarnMsgID_734 500;
BA_ "GenSigTimeoutTime_ALL" SG_ 1249 WarnMsgID_735 500;
BA_ "GenSigTimeoutTime_ALL" SG_ 1249 WarnMsgID_736 500;
BA_ "GenSigTimeoutTime_ALL" SG_ 1249 WarnMsgID_737 500;
BA_ "GenSigTimeoutTime_ALL" SG_ 1249 WarnMsgID_738 500;
BA_ "GenSigTimeoutTime_ALL" SG_ 1249 WarnMsgID_739 500;
BA_ "GenSigTimeoutTime_ALL" SG_ 1249 WarnMsgID_740 500;
BA_ "GenSigTimeoutTime_ALL" SG_ 1249 WarnMsgID_741 500;
BA_ "GenSigTimeoutTime_ALL" SG_ 1249 WarnMsgID_742 500;
BA_ "GenSigTimeoutTime_ALL" SG_ 1249 WarnMsgID_743 500;
BA_ "GenSigTimeoutTime_ALL" SG_ 1249 WarnMsgID_744 500;
BA_ "GenSigTimeoutTime_ALL" SG_ 1249 WarnMsgID_745 500;
BA_ "GenSigTimeoutTime_ALL" SG_ 1249 WarnMsgID_746 500;
BA_ "GenSigTimeoutTime_ALL" SG_ 1249 WarnMsgID_747 500;
BA_ "GenSigTimeoutTime_ALL" SG_ 1249 WarnMsgID_748 500;
BA_ "GenSigTimeoutTime_ALL" SG_ 1249 WarnMsgID_749 500;
BA_ "GenSigTimeoutTime_ALL" SG_ 1249 WarnMsgID_750 500;
BA_ "GenSigTimeoutTime_ALL" SG_ 1249 WarnMsgID_751 500;
BA_ "GenSigTimeoutTime_ALL" SG_ 1249 WarnMsgID_752 500;
BA_ "GenSigTimeoutTime_ALL" SG_ 1249 WarnMsgID_753 500;
BA_ "GenSigTimeoutTime_ALL" SG_ 1249 WarnMsgID_754 500;
BA_ "GenSigTimeoutTime_ALL" SG_ 1249 WarnMsgID_755 500;
BA_ "GenSigTimeoutTime_ALL" SG_ 1249 WarnMsgID_756 500;
BA_ "GenSigTimeoutTime_ALL" SG_ 1249 WarnMsgID_757 500;
BA_ "GenSigTimeoutTime_ALL" SG_ 1249 WarnMsgID_758 500;
BA_ "GenSigTimeoutTime_ALL" SG_ 1249 WarnMsgID_759 500;
BA_ "GenSigTimeoutTime_ALL" SG_ 1249 WarnMsgID_760 500;
BA_ "GenSigTimeoutTime_ALL" SG_ 1249 WarnMsgID_761 500;
BA_ "GenSigTimeoutTime_ALL" SG_ 1249 WarnMsgID_762 500;
BA_ "GenSigTimeoutTime_ALL" SG_ 1249 WarnMsgID_763 500;
BA_ "GenSigTimeoutTime_ALL" SG_ 1249 WarnMsgID_764 500;
BA_ "GenSigTimeoutTime_ALL" SG_ 1249 WarnMsgID_765 500;
BA_ "GenSigTimeoutTime_ALL" SG_ 1249 WarnMsgID_766 500;
BA_ "GenSigTimeoutTime_ALL" SG_ 1249 WarnMsgID_767 500;
BA_ "GenSigTimeoutTime_ALL" SG_ 1249 WarnMsgID_768 500;
BA_ "GenSigTimeoutTime_ALL" SG_ 1249 WarnMsgID_769 500;
BA_ "GenSigTimeoutTime_ALL" SG_ 1249 WarnMsgID_770 500;
BA_ "GenSigTimeoutTime_ALL" SG_ 1249 WarnMsgID_771 500;
BA_ "GenSigTimeoutTime_ALL" SG_ 1249 WarnMsgID_772 500;
BA_ "GenSigTimeoutTime_ALL" SG_ 1249 WarnMsgID_773 500;
BA_ "GenSigTimeoutTime_ALL" SG_ 1249 WarnMsgID_774 500;
BA_ "GenSigTimeoutTime_ALL" SG_ 1249 WarnMsgID_775 500;
BA_ "GenSigTimeoutTime_ALL" SG_ 1249 WarnMsgID_776 500;
BA_ "GenSigTimeoutTime_ALL" SG_ 1249 WarnMsgID_777 500;
BA_ "GenSigTimeoutTime_ALL" SG_ 1249 WarnMsgID_778 500;
BA_ "GenSigTimeoutTime_ALL" SG_ 1249 WarnMsgID_779 500;
BA_ "GenSigTimeoutTime_ALL" SG_ 1249 WarnMsgID_780 500;
BA_ "GenSigTimeoutTime_ALL" SG_ 1249 WarnMsgID_781 500;
BA_ "GenSigTimeoutTime_ALL" SG_ 1249 WarnMsgID_782 500;
BA_ "GenSigTimeoutTime_ALL" SG_ 1249 WarnMsgID_783 500;
BA_ "GenSigTimeoutTime_ALL" SG_ 1249 WarnMsgID_784 500;
BA_ "GenSigTimeoutTime_ALL" SG_ 1249 WarnMsgID_785 500;
BA_ "GenSigTimeoutTime_ALL" SG_ 1249 WarnMsgID_786 500;
BA_ "GenSigTimeoutTime_ALL" SG_ 1249 WarnMsgID_787 500;
BA_ "GenSigTimeoutTime_ALL" SG_ 1249 WarnMsgID_788 500;
BA_ "GenSigTimeoutTime_ALL" SG_ 1249 WarnMsgID_789 500;
BA_ "GenSigTimeoutTime_ALL" SG_ 1249 WarnMsgID_790 500;
BA_ "GenSigTimeoutTime_ALL" SG_ 1249 WarnMsgID_791 500;
BA_ "GenSigTimeoutTime_ALL" SG_ 1249 WarnMsgID_792 500;
BA_ "GenSigTimeoutTime_ALL" SG_ 1249 WarnMsgID_793 500;
BA_ "GenSigTimeoutTime_ALL" SG_ 1249 WarnMsgID_794 500;
BA_ "GenSigTimeoutTime_ALL" SG_ 1249 WarnMsgID_795 500;
BA_ "GenSigTimeoutTime_ALL" SG_ 1249 WarnMsgID_796 500;
BA_ "GenSigTimeoutTime_ALL" SG_ 1249 WarnMsgID_797 500;
BA_ "GenSigTimeoutTime_ALL" SG_ 1249 WarnMsgID_798 500;
BA_ "GenSigTimeoutTime_ALL" SG_ 1249 WarnMsgID_799 500;
BA_ "GenSigTimeoutTime_ALL" SG_ 1249 WarnMsgID_800 500;
BA_ "GenSigTimeoutTime_ALL" SG_ 1249 WarnMsgID_801 500;
BA_ "GenSigTimeoutTime_ALL" SG_ 1249 WarnMsgID_802 500;
BA_ "GenSigTimeoutTime_ALL" SG_ 1249 WarnMsgID_803 500;
BA_ "GenSigTimeoutTime_ALL" SG_ 1249 WarnMsgID_804 500;
BA_ "GenSigTimeoutTime_ALL" SG_ 1249 WarnMsgID_805 500;
BA_ "GenSigTimeoutTime_ALL" SG_ 1249 WarnMsgID_806 500;
BA_ "GenSigTimeoutTime_ALL" SG_ 1249 WarnMsgID_807 500;
BA_ "GenSigTimeoutTime_ALL" SG_ 1249 WarnMsgID_808 500;
BA_ "GenSigTimeoutTime_ALL" SG_ 1249 WarnMsgID_809 500;
BA_ "GenSigTimeoutTime_ALL" SG_ 1249 WarnMsgID_810 500;
BA_ "GenSigTimeoutTime_ALL" SG_ 1249 WarnMsgID_811 500;
BA_ "GenSigTimeoutTime_ALL" SG_ 1249 WarnMsgID_812 500;
BA_ "GenSigTimeoutTime_ALL" SG_ 1249 WarnMsgID_813 500;
BA_ "GenSigTimeoutTime_ALL" SG_ 1249 WarnMsgID_814 500;
BA_ "GenSigTimeoutTime_ALL" SG_ 1249 WarnMsgID_815 500;
BA_ "GenSigTimeoutTime_ALL" SG_ 1249 WarnMsgID_816 500;
BA_ "GenSigTimeoutTime_ALL" SG_ 1249 WarnMsgID_817 500;
BA_ "GenSigTimeoutTime_ALL" SG_ 1249 WarnMsgID_818 500;
BA_ "GenSigTimeoutTime_ALL" SG_ 1249 WarnMsgID_819 500;
BA_ "GenSigTimeoutTime_ALL" SG_ 1249 WarnMsgID_820 500;
BA_ "GenSigTimeoutTime_ALL" SG_ 1249 WarnMsgID_821 500;
BA_ "GenSigTimeoutTime_ALL" SG_ 1249 WarnMsgID_822 500;
BA_ "GenSigTimeoutTime_ALL" SG_ 1249 WarnMsgID_823 500;
BA_ "GenSigTimeoutTime_ALL" SG_ 1249 WarnMsgID_824 500;
BA_ "GenSigTimeoutTime_ALL" SG_ 1249 WarnMsgID_825 500;
BA_ "GenSigTimeoutTime_ALL" SG_ 1249 WarnMsgID_826 500;
BA_ "GenSigTimeoutTime_ALL" SG_ 1249 WarnMsgID_827 500;
BA_ "GenSigTimeoutTime_ALL" SG_ 1249 WarnMsgID_828 500;
BA_ "GenSigTimeoutTime_ALL" SG_ 1249 WarnMsgID_829 500;
BA_ "GenSigTimeoutTime_ALL" SG_ 1249 WarnMsgID_830 500;
BA_ "GenSigTimeoutTime_ALL" SG_ 1249 WarnMsgID_831 500;
BA_ "GenSigTimeoutTime_ALL" SG_ 1249 WarnMsgID_832 500;
BA_ "GenSigTimeoutTime_ALL" SG_ 1249 WarnMsgID_833 500;
BA_ "GenSigTimeoutTime_ALL" SG_ 1249 WarnMsgID_834 500;
BA_ "GenSigTimeoutTime_ALL" SG_ 1249 WarnMsgID_835 500;
BA_ "GenSigTimeoutTime_ALL" SG_ 1249 WarnMsgID_836 500;
BA_ "GenSigTimeoutTime_ALL" SG_ 1249 WarnMsgID_837 500;
BA_ "GenSigTimeoutTime_ALL" SG_ 1249 WarnMsgID_838 500;
BA_ "GenSigTimeoutTime_ALL" SG_ 1249 WarnMsgID_839 500;
BA_ "GenSigTimeoutTime_ALL" SG_ 1249 WarnMsgID_840 500;
BA_ "GenSigTimeoutTime_ALL" SG_ 1249 WarnMsgID_841 500;
BA_ "GenSigTimeoutTime_ALL" SG_ 1249 WarnMsgID_842 500;
BA_ "GenSigTimeoutTime_ALL" SG_ 1249 WarnMsgID_843 500;
BA_ "GenSigTimeoutTime_ALL" SG_ 1249 WarnMsgID_844 500;
BA_ "GenSigTimeoutTime_ALL" SG_ 1249 WarnMsgID_845 500;
BA_ "GenSigTimeoutTime_ALL" SG_ 1249 WarnMsgID_846 500;
BA_ "GenSigTimeoutTime_ALL" SG_ 1249 WarnMsgID_847 500;
BA_ "GenSigTimeoutTime_ALL" SG_ 1249 WarnMsgID_848 500;
BA_ "GenSigTimeoutTime_ALL" SG_ 1249 WarnMsgID_849 500;
BA_ "GenSigTimeoutTime_ALL" SG_ 1249 WarnMsgID_850 500;
BA_ "GenSigTimeoutTime_ALL" SG_ 1249 WarnMsgID_851 500;
BA_ "GenSigTimeoutTime_ALL" SG_ 1249 WarnMsgID_852 500;
BA_ "GenSigTimeoutTime_ALL" SG_ 1249 WarnMsgID_853 500;
BA_ "GenSigTimeoutTime_ALL" SG_ 1249 WarnMsgID_854 500;
BA_ "GenSigTimeoutTime_ALL" SG_ 1249 WarnMsgID_855 500;
BA_ "GenSigTimeoutTime_ALL" SG_ 1249 WarnMsgID_856 500;
BA_ "GenSigTimeoutTime_ALL" SG_ 1249 WarnMsgID_857 500;
BA_ "GenSigTimeoutTime_ALL" SG_ 1249 WarnMsgID_858 500;
BA_ "GenSigTimeoutTime_ALL" SG_ 1249 WarnMsgID_859 500;
BA_ "GenSigTimeoutTime_ALL" SG_ 1249 WarnMsgID_860 500;
BA_ "GenSigTimeoutTime_ALL" SG_ 1249 WarnMsgID_861 500;
BA_ "GenSigTimeoutTime_ALL" SG_ 1249 WarnMsgID_862 500;
BA_ "GenSigTimeoutTime_ALL" SG_ 1249 WarnMsgID_863 500;
BA_ "GenSigTimeoutTime_ALL" SG_ 1249 WarnMsgID_864 500;
BA_ "GenSigTimeoutTime_ALL" SG_ 1249 WarnMsgID_865 500;
BA_ "GenSigTimeoutTime_ALL" SG_ 1249 WarnMsgID_866 500;
BA_ "GenSigTimeoutTime_ALL" SG_ 1249 WarnMsgID_867 500;
BA_ "GenSigTimeoutTime_ALL" SG_ 1249 WarnMsgID_868 500;
BA_ "GenSigTimeoutTime_ALL" SG_ 1249 WarnMsgID_869 500;
BA_ "GenSigTimeoutTime_ALL" SG_ 1249 WarnMsgID_870 500;
BA_ "GenSigTimeoutTime_ALL" SG_ 1249 WarnMsgID_871 500;
BA_ "GenSigTimeoutTime_ALL" SG_ 1249 WarnMsgID_872 500;
BA_ "GenSigTimeoutTime_ALL" SG_ 1249 WarnMsgID_873 500;
BA_ "GenSigTimeoutTime_ALL" SG_ 1249 WarnMsgID_874 500;
BA_ "GenSigTimeoutTime_ALL" SG_ 1249 WarnMsgID_875 500;
BA_ "GenSigTimeoutTime_ALL" SG_ 1249 WarnMsgID_876 500;
BA_ "GenSigTimeoutTime_ALL" SG_ 1249 WarnMsgID_877 500;
BA_ "GenSigTimeoutTime_ALL" SG_ 1249 WarnMsgID_878 500;
BA_ "GenSigTimeoutTime_ALL" SG_ 1249 WarnMsgID_879 500;
BA_ "GenSigTimeoutTime_ALL" SG_ 1249 WarnMsgID_880 500;
BA_ "GenSigTimeoutTime_ALL" SG_ 1249 WarnMsgID_881 500;
BA_ "GenSigTimeoutTime_ALL" SG_ 1249 WarnMsgID_882 500;
BA_ "GenSigTimeoutTime_ALL" SG_ 1249 WarnMsgID_883 500;
BA_ "GenSigTimeoutTime_ALL" SG_ 1249 WarnMsgID_884 500;
BA_ "GenSigTimeoutTime_ALL" SG_ 1249 WarnMsgID_885 500;
BA_ "GenSigTimeoutTime_ALL" SG_ 1249 WarnMsgID_886 500;
BA_ "GenSigTimeoutTime_ALL" SG_ 1249 WarnMsgID_887 500;
BA_ "GenSigTimeoutTime_ALL" SG_ 1249 WarnMsgID_888 500;
BA_ "GenSigTimeoutTime_ALL" SG_ 1249 WarnMsgID_889 500;
BA_ "GenSigTimeoutTime_ALL" SG_ 1249 WarnMsgID_890 500;
BA_ "GenSigTimeoutTime_ALL" SG_ 1249 WarnMsgID_891 500;
BA_ "GenSigTimeoutTime_ALL" SG_ 1249 WarnMsgID_892 500;
BA_ "GenSigTimeoutTime_ALL" SG_ 1249 WarnMsgID_893 500;
BA_ "GenSigTimeoutTime_ALL" SG_ 1249 WarnMsgID_894 500;
BA_ "GenSigTimeoutTime_ALL" SG_ 1249 WarnMsgID_895 500;
BA_ "GenSigTimeoutTime_ALL" SG_ 1249 WarnMsgID_896 500;
BA_ "GenSigTimeoutTime_ALL" SG_ 1249 WarnMsgID_897 500;
BA_ "GenSigTimeoutTime_ALL" SG_ 1249 WarnMsgID_898 500;
BA_ "GenSigTimeoutTime_ALL" SG_ 1249 WarnMsgID_899 500;
BA_ "GenSigTimeoutTime_ALL" SG_ 1249 WarnMsgID_900 500;
BA_ "GenSigTimeoutTime_ALL" SG_ 1249 WarnMsgID_901 500;
BA_ "GenSigTimeoutTime_ALL" SG_ 1249 WarnMsgID_902 500;
BA_ "GenSigTimeoutTime_ALL" SG_ 1249 WarnMsgID_903 500;
BA_ "GenSigTimeoutTime_ALL" SG_ 1249 WarnMsgID_904 500;
BA_ "GenSigTimeoutTime_ALL" SG_ 1249 WarnMsgID_905 500;
BA_ "GenSigTimeoutTime_ALL" SG_ 1249 WarnMsgID_906 500;
BA_ "GenSigTimeoutTime_ALL" SG_ 1249 WarnMsgID_907 500;
BA_ "GenSigTimeoutTime_ALL" SG_ 1249 WarnMsgID_908 500;
BA_ "GenSigTimeoutTime_ALL" SG_ 1249 WarnMsgID_909 500;
BA_ "GenSigTimeoutTime_ALL" SG_ 1249 WarnMsgID_910 500;
BA_ "GenSigTimeoutTime_ALL" SG_ 1249 WarnMsgID_911 500;
BA_ "GenSigTimeoutTime_ALL" SG_ 1249 WarnMsgID_912 500;
BA_ "GenSigTimeoutTime_ALL" SG_ 1249 WarnMsgID_913 500;
BA_ "GenSigTimeoutTime_ALL" SG_ 1249 WarnMsgID_914 500;
BA_ "GenSigTimeoutTime_ALL" SG_ 1249 WarnMsgID_915 500;
BA_ "GenSigTimeoutTime_ALL" SG_ 1249 WarnMsgID_916 500;
BA_ "GenSigTimeoutTime_ALL" SG_ 1249 WarnMsgID_917 500;
BA_ "GenSigTimeoutTime_ALL" SG_ 1249 WarnMsgID_918 500;
BA_ "GenSigTimeoutTime_ALL" SG_ 1249 WarnMsgID_919 500;
BA_ "GenSigTimeoutTime_ALL" SG_ 1249 WarnMsgID_920 500;
BA_ "GenSigTimeoutTime_ALL" SG_ 1249 WarnMsgID_921 500;
BA_ "GenSigTimeoutTime_ALL" SG_ 1249 WarnMsgID_922 500;
BA_ "GenSigTimeoutTime_ALL" SG_ 1249 WarnMsgID_923 500;
BA_ "GenSigTimeoutTime_ALL" SG_ 1249 WarnMsgID_924 500;
BA_ "GenSigTimeoutTime_ALL" SG_ 1249 WarnMsgID_925 500;
BA_ "GenSigTimeoutTime_ALL" SG_ 1249 WarnMsgID_926 500;
BA_ "GenSigTimeoutTime_ALL" SG_ 1249 WarnMsgID_927 500;
BA_ "GenSigTimeoutTime_ALL" SG_ 1249 WarnMsgID_928 500;
BA_ "GenSigTimeoutTime_ALL" SG_ 1249 WarnMsgID_929 500;
BA_ "GenSigTimeoutTime_ALL" SG_ 1249 WarnMsgID_930 500;
BA_ "GenSigTimeoutTime_ALL" SG_ 1249 WarnMsgID_931 500;
BA_ "GenSigTimeoutTime_ALL" SG_ 1249 WarnMsgID_932 500;
BA_ "GenSigTimeoutTime_ALL" SG_ 1249 WarnMsgID_933 500;
BA_ "GenSigTimeoutTime_ALL" SG_ 1249 WarnMsgID_934 500;
BA_ "GenSigTimeoutTime_ALL" SG_ 1249 WarnMsgID_935 500;
BA_ "GenSigTimeoutTime_ALL" SG_ 1249 WarnMsgID_936 500;
BA_ "GenSigTimeoutTime_ALL" SG_ 1249 WarnMsgID_937 500;
BA_ "GenSigTimeoutTime_ALL" SG_ 1249 WarnMsgID_938 500;
BA_ "GenSigTimeoutTime_ALL" SG_ 1249 WarnMsgID_939 500;
BA_ "GenSigTimeoutTime_ALL" SG_ 1249 WarnMsgID_940 500;
BA_ "GenSigTimeoutTime_ALL" SG_ 1249 WarnMsgID_941 500;
BA_ "GenSigTimeoutTime_ALL" SG_ 1249 WarnMsgID_942 500;
BA_ "GenSigTimeoutTime_ALL" SG_ 1249 WarnMsgID_943 500;
BA_ "GenSigTimeoutTime_ALL" SG_ 1249 WarnMsgID_944 500;
BA_ "GenSigTimeoutTime_ALL" SG_ 1249 WarnMsgID_945 500;
BA_ "GenSigTimeoutTime_ALL" SG_ 1249 WarnMsgID_946 500;
BA_ "GenSigTimeoutTime_ALL" SG_ 1249 WarnMsgID_947 500;
BA_ "GenSigTimeoutTime_ALL" SG_ 1249 WarnMsgID_948 500;
BA_ "GenSigTimeoutTime_ALL" SG_ 1249 WarnMsgID_949 500;
BA_ "GenSigTimeoutTime_ALL" SG_ 1249 WarnMsgID_950 500;
BA_ "GenSigTimeoutTime_ALL" SG_ 1249 WarnMsgID_951 500;
BA_ "GenSigTimeoutTime_ALL" SG_ 1249 WarnMsgID_952 500;
BA_ "GenSigTimeoutTime_ALL" SG_ 1249 WarnMsgID_953 500;
BA_ "GenSigTimeoutTime_ALL" SG_ 1249 WarnMsgID_954 500;
BA_ "GenSigTimeoutTime_ALL" SG_ 1249 WarnMsgID_955 500;
BA_ "GenSigTimeoutTime_ALL" SG_ 1249 WarnMsgID_956 500;
BA_ "GenSigTimeoutTime_ALL" SG_ 1249 WarnMsgID_957 500;
BA_ "GenSigTimeoutTime_ALL" SG_ 1249 WarnMsgID_958 500;
BA_ "GenSigTimeoutTime_ALL" SG_ 1249 WarnMsgID_959 500;
BA_ "GenSigTimeoutTime_ALL" SG_ 1249 WarnMsgID_960 500;
BA_ "GenSigTimeoutTime_ALL" SG_ 1249 WarnMsgID_961 500;
BA_ "GenSigTimeoutTime_ALL" SG_ 1249 WarnMsgID_962 500;
BA_ "GenSigTimeoutTime_ALL" SG_ 1249 WarnMsgID_963 500;
BA_ "GenSigTimeoutTime_ALL" SG_ 1249 WarnMsgID_964 500;
BA_ "GenSigTimeoutTime_ALL" SG_ 1249 WarnMsgID_965 500;
BA_ "GenSigTimeoutTime_ALL" SG_ 1249 WarnMsgID_966 500;
BA_ "GenSigTimeoutTime_ALL" SG_ 1249 WarnMsgID_967 500;
BA_ "GenSigTimeoutTime_ALL" SG_ 1249 WarnMsgID_968 500;
BA_ "GenSigTimeoutTime_ALL" SG_ 1249 WarnMsgID_969 500;
BA_ "GenSigTimeoutTime_ALL" SG_ 1249 WarnMsgID_970 500;
BA_ "GenSigTimeoutTime_ALL" SG_ 1249 WarnMsgID_971 500;
BA_ "GenSigTimeoutTime_ALL" SG_ 1249 WarnMsgID_972 500;
BA_ "GenSigTimeoutTime_ALL" SG_ 1249 WarnMsgID_973 500;
BA_ "GenSigTimeoutTime_ALL" SG_ 1249 WarnMsgID_974 500;
BA_ "GenSigTimeoutTime_ALL" SG_ 1249 WarnMsgID_975 500;
BA_ "GenSigTimeoutTime_ALL" SG_ 1249 WarnMsgID_976 500;
BA_ "GenSigTimeoutTime_ALL" SG_ 1249 WarnMsgID_977 500;
BA_ "GenSigTimeoutTime_ALL" SG_ 1249 WarnMsgID_978 500;
BA_ "GenSigTimeoutTime_ALL" SG_ 1249 WarnMsgID_979 500;
BA_ "GenSigTimeoutTime_ALL" SG_ 1249 WarnMsgID_980 500;
BA_ "GenSigTimeoutTime_ALL" SG_ 1249 WarnMsgID_981 500;
BA_ "GenSigTimeoutTime_ALL" SG_ 1249 WarnMsgID_982 500;
BA_ "GenSigTimeoutTime_ALL" SG_ 1249 WarnMsgID_983 500;
BA_ "GenSigTimeoutTime_ALL" SG_ 1249 WarnMsgID_984 500;
BA_ "GenSigTimeoutTime_ALL" SG_ 1249 WarnMsgID_985 500;
BA_ "GenSigTimeoutTime_ALL" SG_ 1249 WarnMsgID_986 500;
BA_ "GenSigTimeoutTime_ALL" SG_ 1249 WarnMsgID_987 500;
BA_ "GenSigTimeoutTime_ALL" SG_ 1249 WarnMsgID_988 500;
BA_ "GenSigTimeoutTime_ALL" SG_ 1249 WarnMsgID_989 500;
BA_ "GenSigTimeoutTime_ALL" SG_ 1249 WarnMsgID_990 500;
BA_ "GenSigTimeoutTime_ALL" SG_ 1249 WarnMsgID_991 500;
BA_ "GenSigTimeoutTime_ALL" SG_ 1249 WarnMsgID_992 500;
BA_ "GenSigTimeoutTime_ALL" SG_ 1249 WarnMsgID_993 500;
BA_ "GenSigTimeoutTime_ALL" SG_ 1249 WarnMsgID_994 500;
BA_ "GenSigTimeoutTime_ALL" SG_ 1249 WarnMsgID_995 500;
BA_ "GenSigTimeoutTime_ALL" SG_ 1249 WarnMsgID_996 500;
BA_ "GenSigTimeoutTime_ALL" SG_ 1249 WarnMsgID_997 500;
BA_ "GenSigTimeoutTime_ALL" SG_ 1249 WarnMsgID_998 500;
BA_ "GenSigTimeoutTime_ALL" SG_ 1249 WarnMsgID_999 500;
BA_ "GenSigStartValue" SG_ 1109 VehicleSpeedAdjustment_Sensitivi 1;
BA_ "SystemSignalLongSymbol" SG_ 1109 VehicleSpeedAdjustment_Sensitivi "VehicleSpeedAdjustment_Sensitivity";
BA_ "InvalidValue" SG_ 1109 Media_Volume "3Fh";
BA_ "GenSigStartValue" SG_ 1109 Media_Volume 8;
BA_ "InvalidValue" SG_ 1109 TEL_Volume "3Fh";
BA_ "GenSigStartValue" SG_ 1109 TEL_Volume 8;
BA_ "InvalidValue" SG_ 1109 Warning_Volume "3Fh";
BA_ "GenSigStartValue" SG_ 1109 Warning_Volume 8;
BA_ "InvalidValue" SG_ 1109 Navigation_Volume "3Fh";
BA_ "GenSigStartValue" SG_ 1109 Navigation_Volume 8;
BA_ "InvalidValue" SG_ 1109 VA_Volume "3Fh";
BA_ "GenSigStartValue" SG_ 1109 VA_Volume 8;
BA_ "InvalidValue" SG_ 1109 Notification_Volume "3Fh";
BA_ "GenSigStartValue" SG_ 1109 Notification_Volume 8;
BA_ "InvalidValue" SG_ 1109 Ringtone_Volume "3Fh";
BA_ "GenSigStartValue" SG_ 1109 Ringtone_Volume 8;
BA_ "GenSigStartValue" SG_ 1109 Media_Mute 1;
BA_ "GenSigStartValue" SG_ 1109 TEL_Mute 1;
BA_ "GenSigStartValue" SG_ 1109 Warning_Mute 1;
BA_ "GenSigStartValue" SG_ 1109 Navigation_Mute 1;
BA_ "GenSigStartValue" SG_ 1109 VA_Mute 1;
BA_ "GenSigStartValue" SG_ 1109 Notification_Mute 1;
BA_ "GenSigStartValue" SG_ 1109 Ringtone_Mute 1;
BA_ "GenSigStartValue" SG_ 1109 Global_Mute 1;
BA_ "GenSigStartValue" SG_ 1109 Directional_Warning_Mute_FL 1;
BA_ "GenSigStartValue" SG_ 1109 Directional_Warning_Mute_FR 1;
BA_ "GenSigStartValue" SG_ 1109 Directional_Warning_Mute_RL 1;
BA_ "GenSigStartValue" SG_ 1109 Directional_Warning_Mute_RR 1;
BA_ "GenSigStartValue" SG_ 1109 Directional_Warning_Mute_Center 1;
BA_ "GenSigStartValue" SG_ 1138 VehicleSpeedAdjustment_Sens_0000 1;
BA_ "SystemSignalLongSymbol" SG_ 1138 VehicleSpeedAdjustment_Sens_0000 "VehicleSpeedAdjustment_Sensitivity_Sts";
BA_ "InvalidValue" SG_ 1138 Media_Volume_Sts "3Fh";
BA_ "GenSigStartValue" SG_ 1138 Media_Volume_Sts 8;
BA_ "InvalidValue" SG_ 1138 TEL_Volume_Sts "3Fh";
BA_ "GenSigStartValue" SG_ 1138 TEL_Volume_Sts 8;
BA_ "InvalidValue" SG_ 1138 Warning_Volume_Sts "3Fh";
BA_ "GenSigStartValue" SG_ 1138 Warning_Volume_Sts 8;
BA_ "InvalidValue" SG_ 1138 Navigation_Volume_Sts "3Fh";
BA_ "GenSigStartValue" SG_ 1138 Navigation_Volume_Sts 8;
BA_ "InvalidValue" SG_ 1138 VA_Volume_Sts "3Fh";
BA_ "GenSigStartValue" SG_ 1138 VA_Volume_Sts 8;
BA_ "InvalidValue" SG_ 1138 Notification_Volume_Sts "3Fh";
BA_ "GenSigStartValue" SG_ 1138 Notification_Volume_Sts 8;
BA_ "InvalidValue" SG_ 1138 Ringtone_Volume_Sts "3Fh";
BA_ "GenSigStartValue" SG_ 1138 Ringtone_Volume_Sts 8;
BA_ "GenSigStartValue" SG_ 1138 Media_Mute_Sts 1;
BA_ "GenSigStartValue" SG_ 1138 TEL_Mute_Sts 1;
BA_ "GenSigStartValue" SG_ 1138 Warning_Mute_Sts 1;
BA_ "GenSigStartValue" SG_ 1138 Navigation_Mute_Sts 1;
BA_ "GenSigStartValue" SG_ 1138 VA_Mute_Sts 1;
BA_ "GenSigStartValue" SG_ 1138 Notification_Mute_Sts 1;
BA_ "GenSigStartValue" SG_ 1138 Ringtone_Mute_Sts 1;
BA_ "GenSigStartValue" SG_ 1138 Global_Mute_Sts 1;
BA_ "GenSigStartValue" SG_ 1138 Directional_Warning_Mute_FL_Sts 1;
BA_ "GenSigStartValue" SG_ 1138 Directional_Warning_Mute_FR_Sts 1;
BA_ "GenSigStartValue" SG_ 1138 Directional_Warning_Mute_RL_Sts 1;
BA_ "GenSigStartValue" SG_ 1138 Directional_Warning_Mute_RR_Sts 1;
BA_ "GenSigStartValue" SG_ 1138 Directional_Warning_Mute_Center_ 1;
BA_ "SystemSignalLongSymbol" SG_ 1138 Directional_Warning_Mute_Center_ "Directional_Warning_Mute_Center_Sts";
BA_ "GenSigSendType" SG_ 1257 CVC_RHMirrorAdjustmentSet 1;
BA_ "GenSigSendType" SG_ 1257 CVC_LHMirrorAdjustmentSet 1;
BA_ "GenSigSendType" SG_ 1257 CVC_SET_MirrorFold_Right 1;
BA_ "GenSigSendType" SG_ 1257 CVC_SET_MirrorFold_Left 1;
BA_ "GenSigSendType" SG_ 1257 RHMirror_Adjustment_Req 1;
BA_ "GenSigSendType" SG_ 1257 LHMirror_Adjustment_Req 1;
BA_ "InvalidValue" SG_ 1257 CVC_SET_LeftMirrorPosX "FFh";
BA_ "GenSigStartValue" SG_ 1257 CVC_SET_LeftMirrorPosX 255;
BA_ "GenSigSendType" SG_ 1257 CVC_SET_LeftMirrorPosX 1;
BA_ "InvalidValue" SG_ 1257 CVC_SET_LeftMirrorPosY "FFh";
BA_ "GenSigStartValue" SG_ 1257 CVC_SET_LeftMirrorPosY 255;
BA_ "GenSigSendType" SG_ 1257 CVC_SET_LeftMirrorPosY 1;
BA_ "InvalidValue" SG_ 1257 CVC_SET_RightMirrorPosX "FFh";
BA_ "GenSigStartValue" SG_ 1257 CVC_SET_RightMirrorPosX 255;
BA_ "GenSigSendType" SG_ 1257 CVC_SET_RightMirrorPosX 1;
BA_ "InvalidValue" SG_ 1257 CVC_SET_RightMirrorPosY "FFh";
BA_ "GenSigStartValue" SG_ 1257 CVC_SET_RightMirrorPosY 255;
BA_ "GenSigSendType" SG_ 1257 CVC_SET_RightMirrorPosY 1;
BA_ "GenSigSendType" SG_ 1968 Sync_TripCnt 2;
BA_ "GenSigSendType" SG_ 1968 Sync_ResetCnt 2;
BA_ "GenSigSendType" SG_ 1968 Sync_MAC 2;
BA_ "InvalidValue" SG_ 256 ALIVE_MHU_Vehicle_Info "Fh";
BA_ "InvalidValue" SG_ 257 ALIVE_MHU_DMS_DriverAttentionWar "Fh";
BA_ "SystemSignalLongSymbol" SG_ 257 ALIVE_MHU_DMS_DriverAttentionWar "ALIVE_MHU_DMS_DriverAttentionWarn";
BA_ "GenSigSendType" SG_ 284 TBOX_FOTA_STAT_TerminalReq 1;
BA_ "InvalidValue" SG_ 294 ALIVE_MHU_ISA_Speed "Fh";
BA_ "InvalidValue" SG_ 294 MHU_ISA_SpeedLimitCon_Percent "7h";
BA_ "InvalidValue" SG_ 294 MHU_ISA_Speed_Setting "Fh";
BA_ "InvalidValue" SG_ 297 ALIVE_MHU_LocalSetting "Fh";
BA_ "InvalidValue" SG_ 297 MHU_STAT_SelectedCountry "3FFh";
BA_ "InvalidValue" SG_ 498 Nav_RoadType "Fh";
BA_ "InvalidValue" SG_ 498 Nav_VehToTrafEyeDist "3FFh";
BA_ "GenSigStartValue" SG_ 498 Nav_VehToTrafEyeDist 1000;
BA_ "InvalidValue" SG_ 498 Nav_errorSts "1h";
BA_ "InvalidValue" SG_ 498 Nav_SpdLimValue "3Fh";
BA_ "GenSigSendType" SG_ 506 MHU_TouchEvtTyp 1;
BA_ "GenSigSendType" SG_ 506 MHU_XGestureSpd 1;
BA_ "GenSigSendType" SG_ 506 MHU_YGestureSpd 1;
BA_ "GenSigSendType" SG_ 506 MHU_Ycoordinate 1;
BA_ "GenSigSendType" SG_ 506 MHU_Xcoordinate 1;
BA_ "GenSigTimeoutTime_ALL" SG_ 649 CRC_MHU_ADCU_VAP_Control 100;
BA_ "InvalidValue" SG_ 649 ALIVE_MHU_ADCU_VAP_Control "Fh";
BA_ "GenSigTimeoutTime_ALL" SG_ 649 ALIVE_MHU_ADCU_VAP_Control 100;
BA_ "InvalidValue" SG_ 649 MHU_ADCU_VAP_Type "Fh";
BA_ "GenSigTimeoutTime_ALL" SG_ 649 MHU_ADCU_VAP_Type 100;
BA_ "InvalidValue" SG_ 649 MHU_ADCU_VAP_TypeSelection "Fh";
BA_ "GenSigTimeoutTime_ALL" SG_ 649 MHU_ADCU_VAP_TypeSelection 100;
BA_ "InvalidValue" SG_ 649 MHU_ADCU_VAP_UserSelection "Fh";
BA_ "GenSigTimeoutTime_ALL" SG_ 649 MHU_ADCU_VAP_UserSelection 100;
BA_ "InvalidValue" SG_ 649 MHU_ADCU_VAP_NoseDir "3h";
BA_ "GenSigTimeoutTime_ALL" SG_ 649 MHU_ADCU_VAP_NoseDir 100;
BA_ "InvalidValue" SG_ 649 MHU_ADCU_VAP_ParkAngle "0h";
BA_ "GenSigTimeoutTime_ALL" SG_ 649 MHU_ADCU_VAP_ParkAngle 100;
BA_ "InvalidValue" SG_ 649 MHU_ADCU_VAP_FinalDestination "FFh";
BA_ "GenSigTimeoutTime_ALL" SG_ 649 MHU_ADCU_VAP_FinalDestination 100;
BA_ "InvalidValue" SG_ 649 MHU_ADCU_VAP_UserAction "0h";
BA_ "GenSigTimeoutTime_ALL" SG_ 649 MHU_ADCU_VAP_UserAction 100;
BA_ "InvalidValue" SG_ 649 MHU_ADCU_VAP_Req "0h";
BA_ "GenSigTimeoutTime_ALL" SG_ 649 MHU_ADCU_VAP_Req 100;
BA_ "InvalidValue" SG_ 649 MHU_ADCU_VAP_RemoteOption "0h";
BA_ "GenSigTimeoutTime_ALL" SG_ 649 MHU_ADCU_VAP_RemoteOption 100;
BA_ "GenSigTimeoutTime_ALL" SG_ 649 MHU_ADCU_VAP_UserSpotSelect 100;
VAL_ 1178 RMCU_Warning_Flag_1 0 "No Error" 1 "Error" ;
VAL_ 1178 RMCU_Warning_Flag_2 0 "No Error" 1 "Error" ;
VAL_ 1178 RMCU_Warning_Flag_3 0 "No Error" 1 "Error" ;
VAL_ 1178 RMCU_Warning_Flag_4 0 "No Error" 1 "Error" ;
VAL_ 1178 RMCU_Warning_Flag_5 0 "No Error" 1 "Error" ;
VAL_ 1178 RMCU_Warning_Flag_6 0 "No Error" 1 "Error" ;
VAL_ 1178 RMCU_Warning_Flag_7 0 "No Error" 1 "Error" ;
VAL_ 1178 RMCU_Warning_Flag_8 0 "No Error" 1 "Error" ;
VAL_ 1178 RMCU_Warning_Flag_9 0 "No Error" 1 "Error" ;
VAL_ 1178 RMCU_Warning_Flag_10 0 "No Error" 1 "Error" ;
VAL_ 1178 RMCU_Warning_Flag_11 0 "No Error" 1 "Error" ;
VAL_ 1178 RMCU_Warning_Flag_12 0 "No Error" 1 "Error" ;
VAL_ 1179 FMCU_Warning_Flag_1 0 "No Error" 1 "Error" ;
VAL_ 1179 FMCU_Warning_Flag_2 0 "No Error" 1 "Error" ;
VAL_ 1179 FMCU_Warning_Flag_3 0 "No Error" 1 "Error" ;
VAL_ 1179 FMCU_Warning_Flag_4 0 "No Error" 1 "Error" ;
VAL_ 1179 FMCU_Warning_Flag_5 0 "No Error" 1 "Error" ;
VAL_ 1179 FMCU_Warning_Flag_6 0 "No Error" 1 "Error" ;
VAL_ 1179 FMCU_Warning_Flag_7 0 "No Error" 1 "Error" ;
VAL_ 1179 FMCU_Warning_Flag_8 0 "No Error" 1 "Error" ;
VAL_ 1179 FMCU_Warning_Flag_9 0 "No Error" 1 "Error" ;
VAL_ 1179 FMCU_Warning_Flag_10 0 "No Error" 1 "Error" ;
VAL_ 1179 FMCU_Warning_Flag_11 0 "No Error" 1 "Error" ;
VAL_ 1179 FMCU_Warning_Flag_12 0 "No Error" 1 "Error" ;
VAL_ 1192 EPS_Malfunction 0 "No Error" 1 "Error" ;
VAL_ 1192 EPS_Reduced 0 "No Error" 1 "Error" ;
VAL_ 1192 EPS_Overheat 0 "No Error" 1 "Error" ;
VAL_ 1192 EPS_NotReady 0 "No Error" 1 "Error" ;
VAL_ 1192 EPS_VEH_SPD_VALID 0 "Valid" 1 "Timeout" 2 "Error" 3 "Reserved" ;
VAL_ 1192 EPS_HV_SIGNAL_EFF 0 "Valid" 1 "Timeout" 2 "Error" 3 "Reserved" ;
VAL_ 1192 EPS_MOS_OT_FLAG 0 "No Error" 1 "MOS1 Error" 2 "MOS2 Error" 3 "MOS1 and MOS2 Error" ;
VAL_ 1192 EPS_MTR_ANG_CALIB_STS 0 "not calibrated" 1 "calibrated" ;
VAL_ 1192 EPS_FAULT_LVL 0 "No Error" 1 "Level 1 malfunctionr" 2 "Level 2 malfunction" 3 "Level 3 malfunction" ;
VAL_ 1196 CVC_GearPOnlyAtStationaryAlert 0 "None" 1 "Alert" ;
VAL_ 1196 CVC_GearP_NotPossibleAlert 0 "None" 1 "Alert" ;
VAL_ 1196 CVC_PressBrakeToEngageGear 0 "None" 1 "Alert" ;
VAL_ 1196 CVC_CantChangeGear 0 "None" 1 "Alert" ;
VAL_ 1196 CVC_GearMalfunction 0 "None" 1 "Alert" ;
VAL_ 1196 CVC_RangeAlert 0 "None" 1 "Alert" ;
VAL_ 1196 CVC_HVSystemReduced 0 "None" 1 "Alert" ;
VAL_ 1196 CVC_FrontEDSReduced 0 "None" 1 "Alert" ;
VAL_ 1196 CVC_FrontEDS_Malfunc 0 "None" 1 "Alert" ;
VAL_ 1196 CVC_RearEDSReduced 0 "None" 1 "Alert" ;
VAL_ 1196 CVC_RearEDS_Malfunc 0 "None" 1 "Alert" ;
VAL_ 1196 CVC_CoolingSystem_Malfunc 0 "None" 1 "Alert" ;
VAL_ 1196 CVC_NeutralRequest 0 "None" 1 "Alert" ;
VAL_ 1196 CVC_SoftShutdown 0 "None" 1 "Alert" ;
VAL_ 1196 CVC_EmergencyShutdown 0 "None" 1 "Alert" ;
VAL_ 1196 CVC_ChgPortDoorSys_Malfunc 0 "None" 1 "Alert" ;
VAL_ 1196 CVC_Gearchange_NotPossible 0 "None" 1 "Alert" ;
VAL_ 1196 CVC_12v_Warning 0 "None" 1 "Alert" ;
VAL_ 1196 CVC_WflagRes19 0 "None" 1 "Alert" ;
VAL_ 1196 CVC_WflagRes20 0 "None" 1 "Alert" ;
VAL_ 1196 CVC_WflagRes21 0 "None" 1 "Alert" ;
VAL_ 1196 CVC_WflagRes22 0 "None" 1 "Alert" ;
VAL_ 1196 CVC_WflagRes23 0 "None" 1 "Alert" ;
VAL_ 1196 CVC_WflagRes24 0 "None" 1 "Alert" ;
VAL_ 1196 CVC_WflagRes25 0 "None" 1 "Alert" ;
VAL_ 1196 CVC_WflagRes26 0 "None" 1 "Alert" ;
VAL_ 1196 CVC_WflagRes27 0 "None" 1 "Alert" ;
VAL_ 1196 CVC_SuperFastCharge_longer 0 "None" 1 "Alert" ;
VAL_ 1196 CVC_InvalidLimitSpeed 0 "None" 1 "Alert" ;
VAL_ 1196 CVC_InvalidCruiseSpeed 0 "None" 1 "Alert" ;
VAL_ 1196 CVC_TMSMode 0 "Reserved" 1 "C1" 2 "C2" 3 "C3" 4 "C4" 5 "C5" 6 "C6" 7 "C7" 8 "C8" 9 "C9" 10 "C10" 11 "C11" 12 "H1" 13 "H2" 14 "H3" 15 "H4" 16 "H5" 17 "H6" 18 "H7" 19 "Filling Mode" 255 "Invalid" ;
VAL_ 1088 AMP_Sts_EQ_1000HZ 0 "-12dB" 1 "-11dB" 2 "-10dB" 3 "-9dB" 4 "-8dB" 5 "-7dB" 6 "-6dB" 7 "-5dB" 8 "-4dB" 9 "-3dB" 10 "-2dB" 11 "-1dB" 12 "0dB" 13 "1dB" 14 "2dB" 15 "3dB" 16 "4dB" 17 "5dB" 18 "6dB" 19 "7dB" 20 "8dB" 21 "9dB" 22 "10dB" 23 "11dB" 24 "12dB" ;
VAL_ 1088 AMP_Sts_EQ_16000HZ 0 "-12dB" 1 "-11dB" 2 "-10dB" 3 "-9dB" 4 "-8dB" 5 "-7dB" 6 "-6dB" 7 "-5dB" 8 "-4dB" 9 "-3dB" 10 "-2dB" 11 "-1dB" 12 "0dB" 13 "1dB" 14 "2dB" 15 "3dB" 16 "4dB" 17 "5dB" 18 "6dB" 19 "7dB" 20 "8dB" 21 "9dB" 22 "10dB" 23 "11dB" 24 "12dB" ;
VAL_ 1088 AMP_Sts_EQ_250HZ 0 "-12dB" 1 "-11dB" 2 "-10dB" 3 "-9dB" 4 "-8dB" 5 "-7dB" 6 "-6dB" 7 "-5dB" 8 "-4dB" 9 "-3dB" 10 "-2dB" 11 "-1dB" 12 "0dB" 13 "1dB" 14 "2dB" 15 "3dB" 16 "4dB" 17 "5dB" 18 "6dB" 19 "7dB" 20 "8dB" 21 "9dB" 22 "10dB" 23 "11dB" 24 "12dB" ;
VAL_ 1088 AMP_Sts_EQ_4000HZ 0 "-12dB" 1 "-11dB" 2 "-10dB" 3 "-9dB" 4 "-8dB" 5 "-7dB" 6 "-6dB" 7 "-5dB" 8 "-4dB" 9 "-3dB" 10 "-2dB" 11 "-1dB" 12 "0dB" 13 "1dB" 14 "2dB" 15 "3dB" 16 "4dB" 17 "5dB" 18 "6dB" 19 "7dB" 20 "8dB" 21 "9dB" 22 "10dB" 23 "11dB" 24 "12dB" ;
VAL_ 1088 AMP_Sts_EQ_60HZ 0 "-12dB" 1 "-11dB" 2 "-10dB" 3 "-9dB" 4 "-8dB" 5 "-7dB" 6 "-6dB" 7 "-5dB" 8 "-4dB" 9 "-3dB" 10 "-2dB" 11 "-1dB" 12 "0dB" 13 "1dB" 14 "2dB" 15 "3dB" 16 "4dB" 17 "5dB" 18 "6dB" 19 "7dB" 20 "8dB" 21 "9dB" 22 "10dB" 23 "11dB" 24 "12dB" ;
VAL_ 1088 AMP_Sts_EQType 0 "Flat" 1 "Pop" 2 "Rock" 3 "Jazz" 4 "Classic" 5 "Vocal" 6 "Custom" 15 "Invalid" ;
VAL_ 1882 DSP_RUN_STATUS 0 "OFF" 1 "ON" 2 "Reserve1" 3 "Reserve2" ;
VAL_ 1882 SYS_RUN_STATUS 0 "NotReady" 1 "Ready" 2 "Error" 3 "Reserved" ;
VAL_ 1882 A2B_RUN_STATUS 0 "NotReady" 1 "Ready" 2 "Error" 3 "Reserved" ;
VAL_ 1882 POWERIC_STATUS 0 "NotReady" 1 "Ready" 2 "Error" 3 "Reserved" ;
VAL_ 1882 CHANNEL1_DAIG_STATUS 0 "Normal" 1 "Abnornal" 2 "Reserved" ;
VAL_ 1882 CHANNEL2_DAIG_STATUS 0 "Normal" 1 "Abnornal" 2 "Reserved" ;
VAL_ 1882 CHANNEL3_DAIG_STATUS 0 "Normal" 1 "Abnornal" 2 "Reserved" ;
VAL_ 1882 CHANNEL4_DAIG_STATUS 0 "Normal" 1 "Abnornal" 2 "Reserved" ;
VAL_ 1882 CHANNEL5_DAIG_STATUS 0 "Normal" 1 "Abnornal" 2 "Reserved" ;
VAL_ 1882 CHANNEL6_DAIG_STATUS 0 "Normal" 1 "Abnornal" 2 "Reserved" ;
VAL_ 1882 CHANNEL7_DAIG_STATUS 0 "Normal" 1 "Abnornal" 2 "Reserved" ;
VAL_ 1882 CHANNEL8_DAIG_STATUS 0 "Normal" 1 "Abnornal" 2 "Reserved" ;
VAL_ 1882 CHANNEL9_DAIG_STATUS 0 "Normal" 1 "Abnornal" 2 "Reserved" ;
VAL_ 1882 CHANNEL10_DAIG_STATUS 0 "Normal" 1 "Abnornal" 2 "Reserved" ;
VAL_ 1882 CHANNEL11_DAIG_STATUS 0 "Normal" 1 "Abnornal" 2 "Reserved" ;
VAL_ 1882 CHANNEL12_DAIG_STATUS 0 "Normal" 1 "Abnornal" 2 "Reserved" ;
VAL_ 1882 CHANNEL13_DAIG_STATUS 0 "Normal" 1 "Abnornal" 2 "Reserved" ;
VAL_ 1882 CHANNEL14_DAIG_STATUS 0 "Normal" 1 "Abnornal" 2 "Reserved" ;
VAL_ 1882 CHANNEL15_DAIG_STATUS 0 "Normal" 1 "Abnornal" 2 "Reserved" ;
VAL_ 1882 CHANNEL16_DAIG_STATUS 0 "Normal" 1 "Abnornal" 2 "Reserved" ;
VAL_ 1136 Slot0_Ready_Sts 0 "NotReady" 1 "Ready" 2 "Error" 3 "Reserved" ;
VAL_ 1136 Slot0_Data_Available_Sts 0 "Available" 1 "Not available" ;
VAL_ 1136 Slot1_Ready_Sts 0 "NotReady" 1 "Ready" 2 "Error" 3 "Reserved" ;
VAL_ 1136 Slot1_Data_Available_Sts 0 "Available" 1 "Not available" ;
VAL_ 1136 Slot2_Ready_Sts 0 "NotReady" 1 "Ready" 2 "Error" 3 "Reserved" ;
VAL_ 1136 Slot2_Data_Available_Sts 0 "Available" 1 "Not available" ;
VAL_ 1136 Slot3_Ready_Sts 0 "NotReady" 1 "Ready" 2 "Error" 3 "Reserved" ;
VAL_ 1136 Slot3_Data_Available_Sts 0 "Available" 1 "Not available" ;
VAL_ 1136 Slot4_Ready_Sts 0 "NotReady" 1 "Ready" 2 "Error" 3 "Reserved" ;
VAL_ 1136 Slot4_Data_Available_Sts 0 "Available" 1 "Not available" ;
VAL_ 1136 Slot5_Ready_Sts 0 "NotReady" 1 "Ready" 2 "Error" 3 "Reserved" ;
VAL_ 1136 Slot5_Data_Available_Sts 0 "Available" 1 "Not available" ;
VAL_ 1136 Slot6_Ready_Sts 0 "NotReady" 1 "Ready" 2 "Error" 3 "Reserved" ;
VAL_ 1136 Slot6_Data_Available_Sts 0 "Available" 1 "Not available" ;
VAL_ 1136 Slot7_Ready_Sts 0 "NotReady" 1 "Ready" 2 "Error" 3 "Reserved" ;
VAL_ 1136 Slot7_Data_Available_Sts 0 "Available" 1 "Not available" ;
VAL_ 1136 Slot8_Ready_Sts 0 "NotReady" 1 "Ready" 2 "Error" 3 "Reserved" ;
VAL_ 1136 Slot8_Data_Available_Sts 0 "Available" 1 "Not available" ;
VAL_ 1136 Slot9_Ready_Sts 0 "NotReady" 1 "Ready" 2 "Error" 3 "Reserved" ;
VAL_ 1136 Slot9_Data_Available_Sts 0 "Available" 1 "Not available" ;
VAL_ 1136 Slot10_Ready_Sts 0 "NotReady" 1 "Ready" 2 "Error" 3 "Reserved" ;
VAL_ 1136 Slot10_Data_Available_Sts 0 "Available" 1 "Not available" ;
VAL_ 1136 Slot11_Ready_Sts 0 "NotReady" 1 "Ready" 2 "Error" 3 "Reserved" ;
VAL_ 1136 Slot11_Data_Available_Sts 0 "Available" 1 "Not available" ;
VAL_ 1136 Slot12_Ready_Sts 0 "NotReady" 1 "Ready" 2 "Error" 3 "Reserved" ;
VAL_ 1136 Slot12_Data_Available_Sts 0 "Available" 1 "Not available" ;
VAL_ 1136 Slot13_Ready_Sts 0 "NotReady" 1 "Ready" 2 "Error" 3 "Reserved" ;
VAL_ 1136 Slot13_Data_Available_Sts 0 "Available" 1 "Not available" ;
VAL_ 1136 Slot14_Ready_Sts 0 "NotReady" 1 "Ready" 2 "Error" 3 "Reserved" ;
VAL_ 1136 Slot14_Data_Available_Sts 0 "Available" 1 "Not available" ;
VAL_ 1136 Slot15_Ready_Sts 0 "NotReady" 1 "Ready" 2 "Error" 3 "Reserved" ;
VAL_ 1136 Slot15_Data_Available_Sts 0 "Available" 1 "Not available" ;
VAL_ 1136 Slot16_Ready_Sts 0 "NotReady" 1 "Ready" 2 "Error" 3 "Reserved" ;
VAL_ 1136 Slot16_Data_Available_Sts 0 "Available" 1 "Not available" ;
VAL_ 1136 Slot17_Ready_Sts 0 "NotReady" 1 "Ready" 2 "Error" 3 "Reserved" ;
VAL_ 1136 Slot17_Data_Available_Sts 0 "Available" 1 "Not available" ;
VAL_ 1136 Slot18_Ready_Sts 0 "NotReady" 1 "Ready" 2 "Error" 3 "Reserved" ;
VAL_ 1136 Slot18_Data_Available_Sts 0 "Available" 1 "Not available" ;
VAL_ 1136 A2B_Initialization_Sts 0 "NotReady" 1 "Ready" 2 "Error" 3 "Reserved" ;
VAL_ 1141 Slot0_Ready 0 "NotReady" 1 "Ready" 2 "Error" 3 "Reserved" ;
VAL_ 1141 Slot0_Data_Available 0 "Available" 1 "Not available" ;
VAL_ 1141 Slot1_Ready 0 "NotReady" 1 "Ready" 2 "Error" 3 "Reserved" ;
VAL_ 1141 Slot1_Data_Available 0 "Available" 1 "Not available" ;
VAL_ 1141 Slot2_Ready 0 "NotReady" 1 "Ready" 2 "Error" 3 "Reserved" ;
VAL_ 1141 Slot2_Data_Available 0 "Available" 1 "Not available" ;
VAL_ 1141 Slot3_Ready 0 "NotReady" 1 "Ready" 2 "Error" 3 "Reserved" ;
VAL_ 1141 Slot3_Data_Available 0 "Available" 1 "Not available" ;
VAL_ 1141 Slot4_Ready 0 "NotReady" 1 "Ready" 2 "Error" 3 "Reserved" ;
VAL_ 1141 Slot4_Data_Available 0 "Available" 1 "Not available" ;
VAL_ 1141 Slot5_Ready 0 "NotReady" 1 "Ready" 2 "Error" 3 "Reserved" ;
VAL_ 1141 Slot5_Data_Available 0 "Available" 1 "Not available" ;
VAL_ 1141 Slot6_Ready 0 "NotReady" 1 "Ready" 2 "Error" 3 "Reserved" ;
VAL_ 1141 Slot6_Data_Available 0 "Available" 1 "Not available" ;
VAL_ 1141 Slot7_Ready 0 "NotReady" 1 "Ready" 2 "Error" 3 "Reserved" ;
VAL_ 1141 Slot7_Data_Available 0 "Available" 1 "Not available" ;
VAL_ 1141 Slot8_Ready 0 "NotReady" 1 "Ready" 2 "Error" 3 "Reserved" ;
VAL_ 1141 Slot8_Data_Available 0 "Available" 1 "Not available" ;
VAL_ 1141 Slot9_Ready 0 "NotReady" 1 "Ready" 2 "Error" 3 "Reserved" ;
VAL_ 1141 Slot9_Data_Available 0 "Available" 1 "Not available" ;
VAL_ 1141 Slot10_Ready 0 "NotReady" 1 "Ready" 2 "Error" 3 "Reserved" ;
VAL_ 1141 Slot10_Data_Available 0 "Available" 1 "Not available" ;
VAL_ 1141 Slot11_Ready 0 "NotReady" 1 "Ready" 2 "Error" 3 "Reserved" ;
VAL_ 1141 Slot11_Data_Available 0 "Available" 1 "Not available" ;
VAL_ 1141 Slot12_Ready 0 "NotReady" 1 "Ready" 2 "Error" 3 "Reserved" ;
VAL_ 1141 Slot12_Data_Available 0 "Available" 1 "Not available" ;
VAL_ 1141 Slot13_Ready 0 "NotReady" 1 "Ready" 2 "Error" 3 "Reserved" ;
VAL_ 1141 Slot13_Data_Available 0 "Available" 1 "Not available" ;
VAL_ 1141 Slot14_Ready 0 "NotReady" 1 "Ready" 2 "Error" 3 "Reserved" ;
VAL_ 1141 Slot14_Data_Available 0 "Available" 1 "Not available" ;
VAL_ 1141 Slot15_Ready 0 "NotReady" 1 "Ready" 2 "Error" 3 "Reserved" ;
VAL_ 1141 Slot15_Data_Available 0 "Available" 1 "Not available" ;
VAL_ 1141 Slot16_Ready 0 "NotReady" 1 "Ready" 2 "Error" 3 "Reserved" ;
VAL_ 1141 Slot16_Data_Available 0 "Available" 1 "Not available" ;
VAL_ 1141 Slot17_Ready 0 "NotReady" 1 "Ready" 2 "Error" 3 "Reserved" ;
VAL_ 1141 Slot17_Data_Available 0 "Available" 1 "Not available" ;
VAL_ 1141 Slot18_Ready 0 "NotReady" 1 "Ready" 2 "Error" 3 "Reserved" ;
VAL_ 1141 Slot18_Data_Available 0 "Available" 1 "Not available" ;
VAL_ 1141 A2B_Initialization 0 "NotReady" 1 "Ready" 2 "Error" 3 "Reserved" ;
VAL_ 1137 MHU_SET_EQ_1000HZ 0 "-12dB" 1 "-11dB" 2 "-10dB" 3 "-9dB" 4 "-8dB" 5 "-7dB" 6 "-6dB" 7 "-5dB" 8 "-4dB" 9 "-3dB" 10 "-2dB" 11 "-1dB" 12 "0dB" 13 "1dB" 14 "2dB" 15 "3dB" 16 "4dB" 17 "5dB" 18 "6dB" 19 "7dB" 20 "8dB" 21 "9dB" 22 "10dB" 23 "11dB" 24 "12dB" ;
VAL_ 1137 MHU_SET_EQ_16000HZ 0 "-12dB" 1 "-11dB" 2 "-10dB" 3 "-9dB" 4 "-8dB" 5 "-7dB" 6 "-6dB" 7 "-5dB" 8 "-4dB" 9 "-3dB" 10 "-2dB" 11 "-1dB" 12 "0dB" 13 "1dB" 14 "2dB" 15 "3dB" 16 "4dB" 17 "5dB" 18 "6dB" 19 "7dB" 20 "8dB" 21 "9dB" 22 "10dB" 23 "11dB" 24 "12dB" ;
VAL_ 1137 MHU_SET_EQ_250HZ 0 "-12dB" 1 "-11dB" 2 "-10dB" 3 "-9dB" 4 "-8dB" 5 "-7dB" 6 "-6dB" 7 "-5dB" 8 "-4dB" 9 "-3dB" 10 "-2dB" 11 "-1dB" 12 "0dB" 13 "1dB" 14 "2dB" 15 "3dB" 16 "4dB" 17 "5dB" 18 "6dB" 19 "7dB" 20 "8dB" 21 "9dB" 22 "10dB" 23 "11dB" 24 "12dB" ;
VAL_ 1137 MHU_SET_EQ_4000HZ 0 "-12dB" 1 "-11dB" 2 "-10dB" 3 "-9dB" 4 "-8dB" 5 "-7dB" 6 "-6dB" 7 "-5dB" 8 "-4dB" 9 "-3dB" 10 "-2dB" 11 "-1dB" 12 "0dB" 13 "1dB" 14 "2dB" 15 "3dB" 16 "4dB" 17 "5dB" 18 "6dB" 19 "7dB" 20 "8dB" 21 "9dB" 22 "10dB" 23 "11dB" 24 "12dB" ;
VAL_ 1137 MHU_SET_EQ_60HZ 0 "-12dB" 1 "-11dB" 2 "-10dB" 3 "-9dB" 4 "-8dB" 5 "-7dB" 6 "-6dB" 7 "-5dB" 8 "-4dB" 9 "-3dB" 10 "-2dB" 11 "-1dB" 12 "0dB" 13 "1dB" 14 "2dB" 15 "3dB" 16 "4dB" 17 "5dB" 18 "6dB" 19 "7dB" 20 "8dB" 21 "9dB" 22 "10dB" 23 "11dB" 24 "12dB" ;
VAL_ 1137 MHU_SET_EQType 0 "Flat" 1 "Pop" 2 "Rock" 3 "Jazz" 4 "Classic" 5 "Vocal" 6 "Custom" 15 "Invalid" ;
VAL_ 1109 Audio_Zone 0 "Front left" 1 "Front right" 2 "Front row" 3 "All" 7 "Invalid" ;
VAL_ 1109 VehicleSpeedAdjustment_Sensitivi 0 "OFF" 1 "LOW" 2 "MID" 3 "HIGH" 4 "Reserved" 5 "Reserved" 6 "Reserved" 7 "Reserved" ;
VAL_ 1109 Preset_Value 0 "Music" 1 "Club" 2 "Voice" 3 "Reserved" ;
VAL_ 1109 Media_Mute 0 "Unmute" 1 "Mute" ;
VAL_ 1109 TEL_Mute 0 "Unmute" 1 "Mute" ;
VAL_ 1109 Warning_Mute 0 "Unmute" 1 "Mute" ;
VAL_ 1109 Navigation_Mute 0 "Unmute" 1 "Mute" ;
VAL_ 1109 VA_Mute 0 "Unmute" 1 "Mute" ;
VAL_ 1109 Notification_Mute 0 "Unmute" 1 "Mute" ;
VAL_ 1109 Ringtone_Mute 0 "Unmute" 1 "Mute" ;
VAL_ 1109 Global_Mute 0 "Unmute" 1 "Mute" ;
VAL_ 1109 Directional_Warning_Mute_FL 0 "Unmute" 1 "Mute" ;
VAL_ 1109 Directional_Warning_Mute_FR 0 "Unmute" 1 "Mute" ;
VAL_ 1109 Directional_Warning_Mute_RL 0 "Unmute" 1 "Mute" ;
VAL_ 1109 Directional_Warning_Mute_RR 0 "Unmute" 1 "Mute" ;
VAL_ 1109 Directional_Warning_Mute_Center 0 "Unmute" 1 "Mute" ;
VAL_ 1138 Audio_Zone_Sts 0 "Front left" 1 "Front right" 2 "Front row" 3 "All" 7 "Invalid" ;
VAL_ 1138 VehicleSpeedAdjustment_Sens_0000 0 "OFF" 1 "LOW" 2 "MID" 3 "HIGH" 4 "Reserved" 5 "Reserved" 6 "Reserved" 7 "Reserved" ;
VAL_ 1138 Preset_Value_Sts 0 "Music" 1 "Club" 2 "Voice" 3 "Reserved" ;
VAL_ 1138 Media_Mute_Sts 0 "Unmute" 1 "Mute" ;
VAL_ 1138 TEL_Mute_Sts 0 "Unmute" 1 "Mute" ;
VAL_ 1138 Warning_Mute_Sts 0 "Unmute" 1 "Mute" ;
VAL_ 1138 Navigation_Mute_Sts 0 "Unmute" 1 "Mute" ;
VAL_ 1138 VA_Mute_Sts 0 "Unmute" 1 "Mute" ;
VAL_ 1138 Notification_Mute_Sts 0 "Unmute" 1 "Mute" ;
VAL_ 1138 Ringtone_Mute_Sts 0 "Unmute" 1 "Mute" ;
VAL_ 1138 Global_Mute_Sts 0 "Unmute" 1 "Mute" ;
VAL_ 1138 Directional_Warning_Mute_FL_Sts 0 "Unmute" 1 "Mute" ;
VAL_ 1138 Directional_Warning_Mute_FR_Sts 0 "Unmute" 1 "Mute" ;
VAL_ 1138 Directional_Warning_Mute_RL_Sts 0 "Unmute" 1 "Mute" ;
VAL_ 1138 Directional_Warning_Mute_RR_Sts 0 "Unmute" 1 "Mute" ;
VAL_ 1138 Directional_Warning_Mute_Center_ 0 "Unmute" 1 "Mute" ;
VAL_ 1257 CVC_RHMirrorAdjustmentSet 0 "OFF" 1 "ON" 2 "Reserved" 3 "Invalid" ;
VAL_ 1257 CVC_LHMirrorAdjustmentSet 0 "OFF" 1 "ON" 2 "Reserved" 3 "Invalid" ;
VAL_ 1257 CVC_SET_MirrorFold_Right 0 "No request" 1 "Fold" 2 "Unfold" 3 "Invalid" ;
VAL_ 1257 CVC_SET_MirrorFold_Left 0 "No request" 1 "Fold" 2 "Unfold" 3 "Invalid" ;
VAL_ 1257 RHMirror_Adjustment_Req 0 "No request" 1 "Up" 2 "Down" 3 "Left" 4 "Right" 5 "Invalid" ;
VAL_ 1257 LHMirror_Adjustment_Req 0 "No request" 1 "Up" 2 "Down" 3 "Left" 4 "Right" 5 "Invalid" ;
VAL_ 256 MHU_Connectivity_Status 0 "Init" 1 "No Connection" 2 "LTE Internet Connection" 3 "WIFI Internet Establish" 4 "WIFI + LTE Connection" 5 "Reserved" 6 "Reserved" 7 "Reserved" ;
VAL_ 257 MHU_DriverAttentionWarn 0 "Unavailable" 1 "Unknown" 2 "NoWarning" 3 "Distractive" 4 "Warninglevel1" 5 "Warninglevel2" 6 "Reserved" 7 "Signal invalid" ;
VAL_ 257 MHU_DMS_DrvAttentionSts 0 "Off" 1 "Initializing" 2 "Stand-by" 3 "Monitoring" 4 "DegradedMonitoring" 5 "DriverUndetected" 6 "Failure" 7 "Reserved" 8 "Reserved" ;
VAL_ 257 MHU_DMS_OperatingSts 0 "NA" 1 "Engaged" 2 "Disengaged" 3 "Reserved" ;
VAL_ 257 MHU_DMS_DrvVisEngageSts 0 "NA" 1 "Responsive" 2 "Unresponsive" 3 "Reserved" ;
VAL_ 257 MHU_DMS_DrvRespSts 0 "Unknown" 1 "EyesOnRoad" 2 "EyesOffRoad" 3 "Reserved" ;
VAL_ 284 TBOX_FOTA_STAT_TerminalReq 0 "OFF(Comfort Enable)" 1 "ACC(Park)" 2 "ON (Driver Present)" 3 "FOTA" 4 "Reserved" 5 "Reserved" 6 "No action" 7 "Signal Invalid" ;
VAL_ 294 MHU_ISA_SpeedLimitCon_Percent 0 "0 Percent" 1 "5 Percent" 2 "10 Percent" 3 "15 percent" 4 "Reserved" 5 "Reserved" 6 "Reserved" ;
VAL_ 294 MHU_ISA_Speed_Setting 0 "0" 1 "5 KPH" 2 "10 KPH" 3 "15 KPH" 4 "20 KPH" 5 "5 MPH" 6 "10 MPH" 7 "15 MPH" 8 "Reserved" 9 "Reserved" 10 "Reserved" 11 "Reserved" 12 "Reserved" 13 "Reserved" 14 "Reserved" ;
VAL_ 498 Nav_RoadType 0 "Unknown" 1 "Expressway" 2 "City expressway" 3 "National rode" 4 "Provincial rode" 5 "County rode" 6 "City or Village rode" 7 "ramp" 8 "Tunnel" 9 "Side rode" 10 "Channel" 15 "Reserved" ;
VAL_ 498 Nav_errorSts 0 "no error" 1 "error" ;
VAL_ 498 Nav_SpdLimValue 0 "No Display" 1 "SPL 5" 2 "SPL 10" 3 "SPL 15" 4 "SPL 20" 5 "SPL 25" 6 "SPL 30" 7 "SPL 35" 8 "SPL 40" 9 "SPL 45" 10 "SPL 50" 11 "SPL 55" 12 "SPL 60" 13 "SPL 65" 14 "SPL 70" 15 "SPL 75" 16 "SPL 80" 17 "SPL 85" 18 "SPL 90" 19 "SPL 95" 20 "SPL 100" 21 "SPL 105" 22 "SPL 110" 23 "SPL 115" 24 "SPL 120" 25 "SPL 125" 26 "SPL 130" 27 "SPL 135" 28 "SPL 140" 29 "SPL 145" 30 "SPL 150" 62 "Reserved" 63 "Invalid" ;
VAL_ 498 Nav_SpdLimType 0 "Unknown" 1 "Traffic sign" 2 "Electronic eye" 3 "Rode Default" ;
VAL_ 498 Nav_SpdLimUnit 0 "Unknown" 1 "KMH" 2 "MPH" 3 "Reserved" ;
VAL_ 498 Nav_TimeIndcn 0 "Invalid" 1 "am" 2 "pm" ;
VAL_ 498 Nav_TimeMod 0 "24" 1 "12" ;
VAL_ 498 Nav_TSRTrafSign 0 "None" 1 "Rain/Wetness" 2 "Snow/Icy" 3 "Time" 4 "Distance for" 5 "Distance in" 6 "Arrow_Straight" 7 "Arrow_left" 8 "Arrow_right" 9 "BendArrow_left" 10 "BendArrow_right" 11 "Arrow_frontageleft" 12 "Arrow_frontageright" 13 "Arrow_turnleftright" 14 "Trailer" 15 "Highway Start" 16 "Highway End" 17 "Motorway Start" 18 "Motorway End" 19 "City Entry" 20 "City Exit" 21 "Residential zones Entry" 22 "Residential zones Exit" 23 "- 0x1F:Reserved" 32 "Curve left" 33 "Curve right" 34 "Double curve left" 35 "Double curve right" 36 "BiCyclic corssing" 37 "Children" 38 "Pedestrains crossing" 39 "Roundabout" 40 "Traffic signals" 41 "Yield" 42 "Stop" 43 "No entrance" 44 "No pass" 45 "End no pass" ;
VAL_ 506 MHU_TouchEvtTyp 0 "One finger single click" 1 "One finger double click" 2 "One finger long press" 3 "One finger moving" 4 "Rotate" 5 "Release" ;
VAL_ 649 MHU_ADCU_VAP_Type 0 "Init" 1 "Park In via MHU" 2 "Park In continue Remote" 3 "Comfort Park In via MHU" 4 "Comfort Park In Continue Remote" 5 "Park Out via MHU" 6 "Park Out via Remote" 7 "Comfort Park Out via MHU" 8 "Comfort Park Out via Remote" 9 "Reverse Forward via MHU" 10 "Reverse Forward via Remote" 11 "Reverse Backward via MHU" 12 "Straight Parking" ;
VAL_ 649 MHU_ADCU_VAP_TypeSelection 0 "Init" 1 "Parallel" 2 "Perpendicular" 3 "Angled" 4 "Reserved" ;
VAL_ 649 MHU_ADCU_VAP_UserSelection 0 "Init" 1 "Front Left" 2 "Front Right" 3 "Rear Left" 4 "Rear Right" ;
VAL_ 649 MHU_ADCU_VAP_NoseDir 0 "Init" 1 "Nose Out" 2 "Nose In" 3 "Reserve" ;
VAL_ 649 MHU_ADCU_VAP_ParkAngle 0 "0 deg" 1 "'Angled 45deg" 2 "90deg" 3 "Angled 135deg" ;
VAL_ 649 MHU_ADCU_VAP_UserAction 0 "No action" 1 "StartParking" 2 "Pause" 3 "Abort" 4 "Skip" 5 "Back" 6 "Resume" 7 "Accept Spot" ;
VAL_ 649 MHU_ADCU_VAP_Req 0 "No Request" 1 "Request" ;
VAL_ 649 MHU_ADCU_VAP_RemoteOption 0 "MHU" 1 "Remote" ;
